VERSION "created by canmatrix"

NS_ :

BS_:

BU_: RadarFrontCenter DASy MPC3

BO_ 214 VFC_Object19A: 64 MPC3
 SG_ VFC_Obj19A_CRC : 0|16@1+ (1,0) [0|65535] ""  RadarFrontCenter,DASy
 SG_ VFC_Obj19A_AliveCtr : 16|8@1+ (1,0) [0|255] ""  RadarFrontCenter,DASy
 SG_ VFC_Obj19A_BlockCtr : 24|4@1+ (1,0) [0|15] ""  RadarFrontCenter,DASy
 SG_ VFC_Obj19A_ProtOrderIndex : 32|6@1+ (1,0) [0|63] ""  RadarFrontCenter,DASy
 SG_ VFC_Obj19A_Ax : 39|9@1+ (0.1,-16) [-16|16] "m/s^2"  RadarFrontCenter,DASy
 SG_ VFC_Obj19A_Vx : 48|12@1+ (0.1,-154) [-154|50] "m/s"  RadarFrontCenter,DASy
 SG_ VFC_Obj19A_Dx : 60|12@1+ (0.05,0) [0|204.7] "m"  RadarFrontCenter,DASy
 SG_ VFC_Obj19A_Dy : 72|14@1+ (0.01,-80) [-80|80] "m"  RadarFrontCenter,DASy
 SG_ VFC_Obj19A_Vy : 86|10@1+ (0.1,-50) [-50|50] "m/s"  RadarFrontCenter,DASy
 SG_ VFC_Obj19A_Ay : 96|8@1+ (0.1,-12) [-12|12] "m/s^2"  RadarFrontCenter,DASy
 SG_ VFC_Obj19A_DyStdDev : 104|10@1+ (0.02,0) [0|20] "m"  RadarFrontCenter,DASy
 SG_ VFC_Obj19A_DxStdDev : 118|10@1+ (0.05,0) [0|50] "m"  RadarFrontCenter,DASy
 SG_ VFC_Obj19A_VxStdDev : 128|10@1+ (0.1,0) [0|100] "m/s"  RadarFrontCenter,DASy
 SG_ VFC_Obj19A_ExistProb : 138|6@1+ (2,0) [0|100] "%"  RadarFrontCenter,DASy
 SG_ VFC_Obj19A_VyStdDev : 144|9@1+ (0.1,0) [0|50] "m/s"  RadarFrontCenter,DASy
 SG_ VFC_Obj19A_TypeProb : 154|6@1+ (2,0) [0|100] "%"  RadarFrontCenter,DASy
 SG_ VFC_Obj19A_AxStdDev : 160|8@1+ (0.1,0) [0|25] "m/s^2"  RadarFrontCenter,DASy
 SG_ VFC_Obj19A_AyStdDev : 168|8@1+ (0.1,0) [0|25] "m/s^2"  RadarFrontCenter,DASy
 SG_ VFC_Obj19A_PhiLeft : 176|13@1+ (0.00025,-1) [-1|1] ""  RadarFrontCenter,DASy
 SG_ VFC_Obj19A_ClassifiedView : 189|3@1+ (1,0) [0|7] ""  RadarFrontCenter,DASy
 SG_ VFC_Obj19A_Length : 192|9@1+ (0.05,0) [0|25.5] "m"  RadarFrontCenter,DASy
 SG_ VFC_Obj19A_WidthStdDev : 201|7@1+ (0.01,0) [0|1] "m"  RadarFrontCenter,DASy
 SG_ VFC_Obj19A_Height : 208|9@1+ (0.01,0) [0|5.11] "m"  RadarFrontCenter,DASy
 SG_ VFC_Obj19A_HeightStdDev : 217|7@1+ (0.01,0) [0|1] "m"  RadarFrontCenter,DASy
 SG_ VFC_Obj19A_PhiLeftStdDev : 224|8@1+ (0.0002,0) [0|0.05] ""  RadarFrontCenter,DASy
 SG_ VFC_Obj19A_HeadingStdDev : 232|6@1+ (0.01,0) [0|0.5] "rad"  RadarFrontCenter,DASy
 SG_ VFC_Obj19A_Measured : 238|2@1+ (1,0) [0|3] ""  RadarFrontCenter,DASy
 SG_ VFC_Obj19A_Heading : 240|9@1+ (0.01,-1.57) [-1.57|1.57] "rad"  RadarFrontCenter,DASy
 SG_ VFC_Obj19A_LengthStdDev : 249|7@1+ (0.05,0) [0|5] "m"  RadarFrontCenter,DASy
 SG_ VFC_Obj19A_PhiMid : 256|13@1+ (0.00025,-1) [-1|1] ""  RadarFrontCenter,DASy
 SG_ VFC_Obj19A_Width : 269|11@1+ (0.01,0) [0|12] "m"  RadarFrontCenter,DASy
 SG_ VFC_Obj19A_PhiMidStdDev : 280|8@1+ (0.0002,0) [0|0.05] ""  RadarFrontCenter,DASy
 SG_ VFC_Obj19A_PhiRight : 288|13@1+ (0.00025,-1) [-1|1] ""  RadarFrontCenter,DASy
 SG_ VFC_Obj19A_VisibleView : 301|3@1+ (1,0) [0|4] ""  RadarFrontCenter,DASy
 SG_ VFC_Obj19A_PhiRightStdDev : 304|8@1+ (0.0002,0) [0|0.05] ""  RadarFrontCenter,DASy
 SG_ VFC_Obj19A_PhiLeftVel : 312|13@1+ (0.001,-4) [-4|4] "1/s"  RadarFrontCenter,DASy
 SG_ VFC_Obj19A_PhiRightVel : 328|13@1+ (0.001,-4) [-4|4] "1/s"  RadarFrontCenter,DASy
 SG_ VFC_Obj19A_PhiRightVelStdDev : 344|8@1+ (0.001,0) [0|0.25] "1/s"  RadarFrontCenter,DASy
 SG_ VFC_Obj19A_PhiLeftVelStdDev : 352|8@1+ (0.001,0) [0|0.25] "1/s"  RadarFrontCenter,DASy
 SG_ VFC_Obj19A_PhiTop : 360|12@1+ (0.00025,-0.4) [-0.4|0.4] ""  RadarFrontCenter,DASy
 SG_ VFC_Obj19A_PhiBottom : 372|12@1+ (0.00025,-0.4) [-0.4|0.4] ""  RadarFrontCenter,DASy
 SG_ VFC_Obj19A_PhiTopStdDev : 384|8@1+ (0.0002,0) [0|0.05] ""  RadarFrontCenter,DASy
 SG_ VFC_Obj19A_HeadOrientation : 392|4@1+ (1,0) [0|10] ""  RadarFrontCenter,DASy
 SG_ VFC_Obj19A_Type : 396|4@1+ (1,0) [0|15] ""  RadarFrontCenter,DASy
 SG_ VFC_Obj19A_PhiBottomStdDev : 400|8@1+ (0.0002,0) [0|0.05] ""  RadarFrontCenter,DASy
 SG_ VFC_Obj19A_NormVx : 408|16@1+ (0.001,-40) [-40|25] "1/s"  RadarFrontCenter,DASy
 SG_ VFC_Obj19A_NormAx : 424|13@1+ (0.002,-10) [-10|6] "1/s^2"  RadarFrontCenter,DASy
 SG_ VFC_Obj19A_NormAxStdDev : 440|10@1+ (0.0025,0) [0|2.5] "1/s^2"  RadarFrontCenter,DASy
 SG_ VFC_Obj19A_ProbMovingLat : 450|6@1+ (2,0) [0|100] "%"  RadarFrontCenter,DASy
 SG_ VFC_Obj19A_ID : 456|8@1+ (1,0) [0|254] ""  RadarFrontCenter,DASy
 SG_ VFC_Obj19A_NormVxStdDev : 464|10@1+ (0.001,0) [0|1] "1/s"  RadarFrontCenter,DASy
 SG_ VFC_Obj19A_ProbMovingLong : 474|6@1+ (2,0) [0|100] "%"  RadarFrontCenter,DASy

BO_ 215 VFC_Object19B: 16 MPC3
 SG_ VFC_Obj19B_TTIPC_StdDev : 120|7@1+ (0.0625,0) [0|7.875] ""  RadarFrontCenter,DASy
 SG_ VFC_Obj19B_TTIPC : 104|11@1+ (0.008,-8) [-8|8] ""  RadarFrontCenter,DASy
 SG_ VFC_Obj19B_AngLongitude : 88|10@1+ (0.005,-2.5) [-2.5|2.5] "rad/s"  RadarFrontCenter,DASy
 SG_ VFC_Obj19B_CRC : 0|16@1+ (1,0) [0|65535] ""  RadarFrontCenter,DASy
 SG_ VFC_Obj19B_AliveCtr : 16|8@1+ (1,0) [0|255] ""  RadarFrontCenter,DASy
 SG_ VFC_Obj19B_BlockCtr : 24|4@1+ (1,0) [0|15] ""  RadarFrontCenter,DASy
 SG_ VFC_Obj19B_ScaleChange : 32|14@1+ (0.0001,0.5) [0.5|2.1] ""  RadarFrontCenter,DASy
 SG_ VFC_Obj19B_ScaleChngStdDev : 48|10@1+ (0.0001,0) [0|0.1] ""  RadarFrontCenter,DASy
 SG_ VFC_Obj19B_LineEdgeRightEgo : 58|1@1+ (1,0) [0|1] ""  RadarFrontCenter,DASy
 SG_ VFC_Obj19B_LineEdgeLeftEgo : 59|1@1+ (1,0) [0|1] ""  RadarFrontCenter,DASy
 SG_ VFC_Obj19B_CompletelyInImg : 60|1@1+ (1,0) [0|1] ""  RadarFrontCenter,DASy
 SG_ VFC_Obj19B_DirIndicator : 61|3@1+ (1,0) [0|7] ""  RadarFrontCenter,DASy
 SG_ VFC_Obj19B_LineEdgeAngle : 64|13@1+ (0.00025,-1) [-1|1] "rad"  RadarFrontCenter,DASy
 SG_ VFC_Obj19B_BrakeLight : 77|3@1+ (1,0) [0|7] ""  RadarFrontCenter,DASy
 SG_ VFC_Obj19B_MeasSource : 80|5@1+ (1,0) [0|31] ""  RadarFrontCenter,DASy
 SG_ VFC_Obj19B_Reliab : 98|6@1+ (1,0) [0|63] ""  RadarFrontCenter,DASy

BO_ 128 VFC_LineHeader: 16 MPC3
 SG_ VFC_LineHdr_AUTOSARTStamp : 96|26@1+ (1,0) [0|67108863] "ms"  DASy,RadarFrontCenter
 SG_ VFC_LineHdr_FrameNo : 28|4@1+ (1,0) [0|15] ""  RadarFrontCenter,DASy
 SG_ VFC_LineHdr_CRC : 0|16@1+ (1,0) [0|65535] ""  RadarFrontCenter,DASy
 SG_ VFC_LineHdr_AliveCtr : 16|8@1+ (1,0) [0|255] ""  RadarFrontCenter,DASy
 SG_ VFC_LineHdr_BlockCounter : 24|4@1+ (1,0) [0|15] ""  RadarFrontCenter,DASy
 SG_ VFC_LineHdr_Report : 32|8@1+ (1,0) [0|255] ""  RadarFrontCenter,DASy
 SG_ VFC_LineHdr_LineCount : 40|8@1+ (1,0) [0|255] ""  RadarFrontCenter,DASy
 SG_ VFC_LineHdr_PEPSIRuntime : 48|8@1+ (0.05,0) [0|10] "ms"  RadarFrontCenter,DASy
 SG_ VFC_LineHdr_TimeStamp : 56|26@1+ (1,0) [0|67108863] "ms"  RadarFrontCenter,DASy
 SG_ VFC_LineHdr_Blindness : 82|6@1+ (2,0) [0|100] "%"  RadarFrontCenter,DASy
 SG_ VFC_LineHdr_State : 88|3@1+ (1,0) [0|7] ""  RadarFrontCenter,DASy

BO_ 129 VFC_Line01: 32 MPC3
 SG_ VFC_Line01_CRC : 0|16@1+ (1,0) [0|65535] ""  RadarFrontCenter,DASy
 SG_ VFC_Line01_AliveCtr : 16|8@1+ (1,0) [0|255] ""  RadarFrontCenter,DASy
 SG_ VFC_Line01_BlockCounter : 24|4@1+ (1,0) [0|15] ""  RadarFrontCenter,DASy
 SG_ VFC_Line01_ProtOrderIndex : 32|6@1+ (1,0) [0|63] ""  RadarFrontCenter,DASy
 SG_ VFC_Line01_LineID : 40|8@1+ (1,0) [0|255] ""  RadarFrontCenter,DASy
 SG_ VFC_Line01_LaneRelation : 48|8@1+ (1,0) [0|255] ""  RadarFrontCenter,DASy
 SG_ VFC_Line01_ExistProb : 56|6@1+ (2,0) [0|100] "%"  RadarFrontCenter,DASy
 SG_ VFC_Line01_DxStart : 64|13@1+ (0.025,0) [0|204.775] "m"  RadarFrontCenter,DASy
 SG_ VFC_Line01_ColorClass : 77|3@1+ (1,0) [0|7] ""  RadarFrontCenter,DASy
 SG_ VFC_Line01_DxEnd : 80|10@1+ (0.25,0) [0|255.75] "m"  RadarFrontCenter,DASy
 SG_ VFC_Line01_HeadingAngle : 91|13@1+ (0.000488281,-1.6) [-1.6|1.6] "rad"  RadarFrontCenter,DASy
 SG_ VFC_Line01_Dy : 104|12@1+ (0.015625,-32) [-32|31.984375] "m"  RadarFrontCenter,DASy
 SG_ VFC_Line01_CurvChange : 116|12@1+ (3.8147E-006,-0.0078125) [-0.0078125|0.0078086965] "1/(m*m)"  RadarFrontCenter,DASy
 SG_ VFC_Line01_Curv : 128|13@1+ (3.8147E-006,-0.015625) [-0.015625|0.0156212077] "1/m"  RadarFrontCenter,DASy
 SG_ VFC_Line01_MeasureType : 141|3@1+ (1,0) [0|3] ""  RadarFrontCenter,DASy
 SG_ VFC_Line01_LineWidth : 144|8@1+ (0.01,0) [0|2.55] "m"  RadarFrontCenter,DASy
 SG_ VFC_Line01_CourseDeviation : 152|10@1+ (0.05,0) [0|50] ""  RadarFrontCenter,DASy
 SG_ VFC_Line01_Type : 162|5@1+ (1,0) [0|31] ""  RadarFrontCenter,DASy
 SG_ VFC_Line01_DyStdDevDxEnd : 167|9@1+ (0.0078125,0) [0|3.9921875] "m"  RadarFrontCenter,DASy
 SG_ VFC_Line01_HypoConfidence : 176|8@1+ (1,0) [0|255] ""  RadarFrontCenter,DASy
 SG_ VFC_Line01_prevID : 184|8@1+ (1,0) [0|255] ""  RadarFrontCenter,DASy
 SG_ VFC_Line01_nextID : 192|8@1+ (1,0) [0|255] ""  RadarFrontCenter,DASy
 SG_ VFC_Line01_DyStdDevDxStart : 200|9@1+ (0.0078125,0) [0|3.9921875] "m"  RadarFrontCenter,DASy
 SG_ VFC_Line01_TypeProb : 209|6@1+ (2,0) [0|100] "%"  RadarFrontCenter,DASy
 SG_ VFC_Line01_DyStdDevDxMid : 215|9@1+ (0.0078125,0) [0|3.9921875] "m"  RadarFrontCenter,DASy

BO_ 130 VFC_Line02: 32 MPC3
 SG_ VFC_Line02_CRC : 0|16@1+ (1,0) [0|65535] ""  RadarFrontCenter,DASy
 SG_ VFC_Line02_AliveCtr : 16|8@1+ (1,0) [0|255] ""  RadarFrontCenter,DASy
 SG_ VFC_Line02_BlockCounter : 24|4@1+ (1,0) [0|15] ""  RadarFrontCenter,DASy
 SG_ VFC_Line02_ProtOrderIndex : 32|6@1+ (1,0) [0|63] ""  RadarFrontCenter,DASy
 SG_ VFC_Line02_LineID : 40|8@1+ (1,0) [0|255] ""  RadarFrontCenter,DASy
 SG_ VFC_Line02_LaneRelation : 48|8@1+ (1,0) [0|255] ""  RadarFrontCenter,DASy
 SG_ VFC_Line02_ExistProb : 56|6@1+ (2,0) [0|100] "%"  RadarFrontCenter,DASy
 SG_ VFC_Line02_DxStart : 64|13@1+ (0.025,0) [0|204.775] "m"  RadarFrontCenter,DASy
 SG_ VFC_Line02_ColorClass : 77|3@1+ (1,0) [0|7] ""  RadarFrontCenter,DASy
 SG_ VFC_Line02_DxEnd : 80|10@1+ (0.25,0) [0|255.75] "m"  RadarFrontCenter,DASy
 SG_ VFC_Line02_HeadingAngle : 91|13@1+ (0.000488281,-1.6) [-1.6|1.6] "rad"  RadarFrontCenter,DASy
 SG_ VFC_Line02_Dy : 104|12@1+ (0.015625,-32) [-32|31.984375] "m"  RadarFrontCenter,DASy
 SG_ VFC_Line02_CurvChange : 116|12@1+ (3.8147E-006,-0.0078125) [-0.0078125|0.0078086965] "1/(m*m)"  RadarFrontCenter,DASy
 SG_ VFC_Line02_Curv : 128|13@1+ (3.8147E-006,-0.015625) [-0.015625|0.0156212077] "1/m"  RadarFrontCenter,DASy
 SG_ VFC_Line02_MeasureType : 141|3@1+ (1,0) [0|3] ""  RadarFrontCenter,DASy
 SG_ VFC_Line02_LineWidth : 144|8@1+ (0.01,0) [0|2.55] "m"  RadarFrontCenter,DASy
 SG_ VFC_Line02_CourseDeviation : 152|10@1+ (0.05,0) [0|50] ""  RadarFrontCenter,DASy
 SG_ VFC_Line02_Type : 162|5@1+ (1,0) [0|31] ""  RadarFrontCenter,DASy
 SG_ VFC_Line02_DyStdDevDxEnd : 167|9@1+ (0.0078125,0) [0|3.9921875] "m"  RadarFrontCenter,DASy
 SG_ VFC_Line02_HypoConfidence : 176|8@1+ (1,0) [0|255] ""  RadarFrontCenter,DASy
 SG_ VFC_Line02_prevID : 184|8@1+ (1,0) [0|255] ""  RadarFrontCenter,DASy
 SG_ VFC_Line02_nextID : 192|8@1+ (1,0) [0|255] ""  RadarFrontCenter,DASy
 SG_ VFC_Line02_DyStdDevDxStart : 200|9@1+ (0.0078125,0) [0|3.9921875] "m"  RadarFrontCenter,DASy
 SG_ VFC_Line02_TypeProb : 209|6@1+ (2,0) [0|100] "%"  RadarFrontCenter,DASy
 SG_ VFC_Line02_DyStdDevDxMid : 215|9@1+ (0.0078125,0) [0|3.9921875] "m"  RadarFrontCenter,DASy

BO_ 131 VFC_Line03: 32 MPC3
 SG_ VFC_Line03_CRC : 0|16@1+ (1,0) [0|65535] ""  RadarFrontCenter,DASy
 SG_ VFC_Line03_AliveCtr : 16|8@1+ (1,0) [0|255] ""  RadarFrontCenter,DASy
 SG_ VFC_Line03_BlockCounter : 24|4@1+ (1,0) [0|15] ""  RadarFrontCenter,DASy
 SG_ VFC_Line03_ProtOrderIndex : 32|6@1+ (1,0) [0|63] ""  RadarFrontCenter,DASy
 SG_ VFC_Line03_LineID : 40|8@1+ (1,0) [0|255] ""  RadarFrontCenter,DASy
 SG_ VFC_Line03_LaneRelation : 48|8@1+ (1,0) [0|255] ""  RadarFrontCenter,DASy
 SG_ VFC_Line03_ExistProb : 56|6@1+ (2,0) [0|100] "%"  RadarFrontCenter,DASy
 SG_ VFC_Line03_DxStart : 64|13@1+ (0.025,0) [0|204.775] "m"  RadarFrontCenter,DASy
 SG_ VFC_Line03_ColorClass : 77|3@1+ (1,0) [0|7] ""  RadarFrontCenter,DASy
 SG_ VFC_Line03_DxEnd : 80|10@1+ (0.25,0) [0|255.75] "m"  RadarFrontCenter,DASy
 SG_ VFC_Line03_HeadingAngle : 91|13@1+ (0.000488281,-1.6) [-1.6|1.6] "rad"  RadarFrontCenter,DASy
 SG_ VFC_Line03_Dy : 104|12@1+ (0.015625,-32) [-32|31.984375] "m"  RadarFrontCenter,DASy
 SG_ VFC_Line03_CurvChange : 116|12@1+ (3.8147E-006,-0.0078125) [-0.0078125|0.0078086965] "1/(m*m)"  RadarFrontCenter,DASy
 SG_ VFC_Line03_Curv : 128|13@1+ (3.8147E-006,-0.015625) [-0.015625|0.0156212077] "1/m"  RadarFrontCenter,DASy
 SG_ VFC_Line03_MeasureType : 141|3@1+ (1,0) [0|3] ""  RadarFrontCenter,DASy
 SG_ VFC_Line03_LineWidth : 144|8@1+ (0.01,0) [0|2.55] "m"  RadarFrontCenter,DASy
 SG_ VFC_Line03_CourseDeviation : 152|10@1+ (0.05,0) [0|50] ""  RadarFrontCenter,DASy
 SG_ VFC_Line03_Type : 162|5@1+ (1,0) [0|31] ""  RadarFrontCenter,DASy
 SG_ VFC_Line03_DyStdDevDxEnd : 167|9@1+ (0.0078125,0) [0|3.9921875] "m"  RadarFrontCenter,DASy
 SG_ VFC_Line03_HypoConfidence : 176|8@1+ (1,0) [0|255] ""  RadarFrontCenter,DASy
 SG_ VFC_Line03_prevID : 184|8@1+ (1,0) [0|255] ""  RadarFrontCenter,DASy
 SG_ VFC_Line03_nextID : 192|8@1+ (1,0) [0|255] ""  RadarFrontCenter,DASy
 SG_ VFC_Line03_DyStdDevDxStart : 200|9@1+ (0.0078125,0) [0|3.9921875] "m"  RadarFrontCenter,DASy
 SG_ VFC_Line03_TypeProb : 209|6@1+ (2,0) [0|100] "%"  RadarFrontCenter,DASy
 SG_ VFC_Line03_DyStdDevDxMid : 215|9@1+ (0.0078125,0) [0|3.9921875] "m"  RadarFrontCenter,DASy

BO_ 132 VFC_Line04: 32 MPC3
 SG_ VFC_Line04_CRC : 0|16@1+ (1,0) [0|65535] ""  RadarFrontCenter,DASy
 SG_ VFC_Line04_AliveCtr : 16|8@1+ (1,0) [0|255] ""  RadarFrontCenter,DASy
 SG_ VFC_Line04_BlockCounter : 24|4@1+ (1,0) [0|15] ""  RadarFrontCenter,DASy
 SG_ VFC_Line04_ProtOrderIndex : 32|6@1+ (1,0) [0|63] ""  RadarFrontCenter,DASy
 SG_ VFC_Line04_LineID : 40|8@1+ (1,0) [0|255] ""  RadarFrontCenter,DASy
 SG_ VFC_Line04_LaneRelation : 48|8@1+ (1,0) [0|255] ""  RadarFrontCenter,DASy
 SG_ VFC_Line04_ExistProb : 56|6@1+ (2,0) [0|100] "%"  RadarFrontCenter,DASy
 SG_ VFC_Line04_DxStart : 64|13@1+ (0.025,0) [0|204.775] "m"  RadarFrontCenter,DASy
 SG_ VFC_Line04_ColorClass : 77|3@1+ (1,0) [0|7] ""  RadarFrontCenter,DASy
 SG_ VFC_Line04_DxEnd : 80|10@1+ (0.25,0) [0|255.75] "m"  RadarFrontCenter,DASy
 SG_ VFC_Line04_HeadingAngle : 91|13@1+ (0.000488281,-1.6) [-1.6|1.6] "rad"  RadarFrontCenter,DASy
 SG_ VFC_Line04_Dy : 104|12@1+ (0.015625,-32) [-32|31.984375] "m"  RadarFrontCenter,DASy
 SG_ VFC_Line04_CurvChange : 116|12@1+ (3.8147E-006,-0.0078125) [-0.0078125|0.0078086965] "1/(m*m)"  RadarFrontCenter,DASy
 SG_ VFC_Line04_Curv : 128|13@1+ (3.8147E-006,-0.015625) [-0.015625|0.0156212077] "1/m"  RadarFrontCenter,DASy
 SG_ VFC_Line04_MeasureType : 141|3@1+ (1,0) [0|3] ""  RadarFrontCenter,DASy
 SG_ VFC_Line04_LineWidth : 144|8@1+ (0.01,0) [0|2.55] "m"  RadarFrontCenter,DASy
 SG_ VFC_Line04_CourseDeviation : 152|10@1+ (0.05,0) [0|50] ""  RadarFrontCenter,DASy
 SG_ VFC_Line04_Type : 162|5@1+ (1,0) [0|31] ""  RadarFrontCenter,DASy
 SG_ VFC_Line04_DyStdDevDxEnd : 167|9@1+ (0.0078125,0) [0|3.9921875] "m"  RadarFrontCenter,DASy
 SG_ VFC_Line04_HypoConfidence : 176|8@1+ (1,0) [0|255] ""  RadarFrontCenter,DASy
 SG_ VFC_Line04_prevID : 184|8@1+ (1,0) [0|255] ""  RadarFrontCenter,DASy
 SG_ VFC_Line04_nextID : 192|8@1+ (1,0) [0|255] ""  RadarFrontCenter,DASy
 SG_ VFC_Line04_DyStdDevDxStart : 200|9@1+ (0.0078125,0) [0|3.9921875] "m"  RadarFrontCenter,DASy
 SG_ VFC_Line04_TypeProb : 209|6@1+ (2,0) [0|100] "%"  RadarFrontCenter,DASy
 SG_ VFC_Line04_DyStdDevDxMid : 215|9@1+ (0.0078125,0) [0|3.9921875] "m"  RadarFrontCenter,DASy

BO_ 133 VFC_Line05: 32 MPC3
 SG_ VFC_Line05_CRC : 0|16@1+ (1,0) [0|65535] ""  RadarFrontCenter,DASy
 SG_ VFC_Line05_AliveCtr : 16|8@1+ (1,0) [0|255] ""  RadarFrontCenter,DASy
 SG_ VFC_Line05_BlockCounter : 24|4@1+ (1,0) [0|15] ""  RadarFrontCenter,DASy
 SG_ VFC_Line05_ProtOrderIndex : 32|6@1+ (1,0) [0|63] ""  RadarFrontCenter,DASy
 SG_ VFC_Line05_LineID : 40|8@1+ (1,0) [0|255] ""  RadarFrontCenter,DASy
 SG_ VFC_Line05_LaneRelation : 48|8@1+ (1,0) [0|255] ""  RadarFrontCenter,DASy
 SG_ VFC_Line05_ExistProb : 56|6@1+ (2,0) [0|100] "%"  RadarFrontCenter,DASy
 SG_ VFC_Line05_DxStart : 64|13@1+ (0.025,0) [0|204.775] "m"  RadarFrontCenter,DASy
 SG_ VFC_Line05_ColorClass : 77|3@1+ (1,0) [0|7] ""  RadarFrontCenter,DASy
 SG_ VFC_Line05_DxEnd : 80|10@1+ (0.25,0) [0|255.75] "m"  RadarFrontCenter,DASy
 SG_ VFC_Line05_HeadingAngle : 91|13@1+ (0.000488281,-1.6) [-1.6|1.6] "rad"  RadarFrontCenter,DASy
 SG_ VFC_Line05_Dy : 104|12@1+ (0.015625,-32) [-32|31.984375] "m"  RadarFrontCenter,DASy
 SG_ VFC_Line05_CurvChange : 116|12@1+ (3.8147E-006,-0.0078125) [-0.0078125|0.0078086965] "1/(m*m)"  RadarFrontCenter,DASy
 SG_ VFC_Line05_Curv : 128|13@1+ (3.8147E-006,-0.015625) [-0.015625|0.0156212077] "1/m"  RadarFrontCenter,DASy
 SG_ VFC_Line05_MeasureType : 141|3@1+ (1,0) [0|3] ""  RadarFrontCenter,DASy
 SG_ VFC_Line05_LineWidth : 144|8@1+ (0.01,0) [0|2.55] "m"  RadarFrontCenter,DASy
 SG_ VFC_Line05_CourseDeviation : 152|10@1+ (0.05,0) [0|50] ""  RadarFrontCenter,DASy
 SG_ VFC_Line05_Type : 162|5@1+ (1,0) [0|31] ""  RadarFrontCenter,DASy
 SG_ VFC_Line05_DyStdDevDxEnd : 167|9@1+ (0.0078125,0) [0|3.9921875] "m"  RadarFrontCenter,DASy
 SG_ VFC_Line05_HypoConfidence : 176|8@1+ (1,0) [0|255] ""  RadarFrontCenter,DASy
 SG_ VFC_Line05_prevID : 184|8@1+ (1,0) [0|255] ""  RadarFrontCenter,DASy
 SG_ VFC_Line05_nextID : 192|8@1+ (1,0) [0|255] ""  RadarFrontCenter,DASy
 SG_ VFC_Line05_DyStdDevDxStart : 200|9@1+ (0.0078125,0) [0|3.9921875] "m"  RadarFrontCenter,DASy
 SG_ VFC_Line05_TypeProb : 209|6@1+ (2,0) [0|100] "%"  RadarFrontCenter,DASy
 SG_ VFC_Line05_DyStdDevDxMid : 215|9@1+ (0.0078125,0) [0|3.9921875] "m"  RadarFrontCenter,DASy

BO_ 134 VFC_Line06: 32 MPC3
 SG_ VFC_Line06_CRC : 0|16@1+ (1,0) [0|65535] ""  RadarFrontCenter,DASy
 SG_ VFC_Line06_AliveCtr : 16|8@1+ (1,0) [0|255] ""  RadarFrontCenter,DASy
 SG_ VFC_Line06_BlockCounter : 24|4@1+ (1,0) [0|15] ""  RadarFrontCenter,DASy
 SG_ VFC_Line06_ProtOrderIndex : 32|6@1+ (1,0) [0|63] ""  RadarFrontCenter,DASy
 SG_ VFC_Line06_LineID : 40|8@1+ (1,0) [0|255] ""  RadarFrontCenter,DASy
 SG_ VFC_Line06_LaneRelation : 48|8@1+ (1,0) [0|255] ""  RadarFrontCenter,DASy
 SG_ VFC_Line06_ExistProb : 56|6@1+ (2,0) [0|100] "%"  RadarFrontCenter,DASy
 SG_ VFC_Line06_DxStart : 64|13@1+ (0.025,0) [0|204.775] "m"  RadarFrontCenter,DASy
 SG_ VFC_Line06_ColorClass : 77|3@1+ (1,0) [0|7] ""  RadarFrontCenter,DASy
 SG_ VFC_Line06_DxEnd : 80|10@1+ (0.25,0) [0|255.75] "m"  RadarFrontCenter,DASy
 SG_ VFC_Line06_HeadingAngle : 91|13@1+ (0.000488281,-1.6) [-1.6|1.6] "rad"  RadarFrontCenter,DASy
 SG_ VFC_Line06_Dy : 104|12@1+ (0.015625,-32) [-32|31.984375] "m"  RadarFrontCenter,DASy
 SG_ VFC_Line06_CurvChange : 116|12@1+ (3.8147E-006,-0.0078125) [-0.0078125|0.0078086965] "1/(m*m)"  RadarFrontCenter,DASy
 SG_ VFC_Line06_Curv : 128|13@1+ (3.8147E-006,-0.015625) [-0.015625|0.0156212077] "1/m"  RadarFrontCenter,DASy
 SG_ VFC_Line06_MeasureType : 141|3@1+ (1,0) [0|3] ""  RadarFrontCenter,DASy
 SG_ VFC_Line06_LineWidth : 144|8@1+ (0.01,0) [0|2.55] "m"  RadarFrontCenter,DASy
 SG_ VFC_Line06_CourseDeviation : 152|10@1+ (0.05,0) [0|50] ""  RadarFrontCenter,DASy
 SG_ VFC_Line06_Type : 162|5@1+ (1,0) [0|31] ""  RadarFrontCenter,DASy
 SG_ VFC_Line06_DyStdDevDxEnd : 167|9@1+ (0.0078125,0) [0|3.9921875] "m"  RadarFrontCenter,DASy
 SG_ VFC_Line06_HypoConfidence : 176|8@1+ (1,0) [0|255] ""  RadarFrontCenter,DASy
 SG_ VFC_Line06_prevID : 184|8@1+ (1,0) [0|255] ""  RadarFrontCenter,DASy
 SG_ VFC_Line06_nextID : 192|8@1+ (1,0) [0|255] ""  RadarFrontCenter,DASy
 SG_ VFC_Line06_DyStdDevDxStart : 200|9@1+ (0.0078125,0) [0|3.9921875] "m"  RadarFrontCenter,DASy
 SG_ VFC_Line06_TypeProb : 209|6@1+ (2,0) [0|100] "%"  RadarFrontCenter,DASy
 SG_ VFC_Line06_DyStdDevDxMid : 215|9@1+ (0.0078125,0) [0|3.9921875] "m"  RadarFrontCenter,DASy

BO_ 135 VFC_Line07: 32 MPC3
 SG_ VFC_Line07_CRC : 0|16@1+ (1,0) [0|65535] ""  RadarFrontCenter,DASy
 SG_ VFC_Line07_AliveCtr : 16|8@1+ (1,0) [0|255] ""  RadarFrontCenter,DASy
 SG_ VFC_Line07_BlockCounter : 24|4@1+ (1,0) [0|15] ""  RadarFrontCenter,DASy
 SG_ VFC_Line07_ProtOrderIndex : 32|6@1+ (1,0) [0|63] ""  RadarFrontCenter,DASy
 SG_ VFC_Line07_LineID : 40|8@1+ (1,0) [0|255] ""  RadarFrontCenter,DASy
 SG_ VFC_Line07_LaneRelation : 48|8@1+ (1,0) [0|255] ""  RadarFrontCenter,DASy
 SG_ VFC_Line07_ExistProb : 56|6@1+ (2,0) [0|100] "%"  RadarFrontCenter,DASy
 SG_ VFC_Line07_DxStart : 64|13@1+ (0.025,0) [0|204.775] "m"  RadarFrontCenter,DASy
 SG_ VFC_Line07_ColorClass : 77|3@1+ (1,0) [0|7] ""  RadarFrontCenter,DASy
 SG_ VFC_Line07_DxEnd : 80|10@1+ (0.25,0) [0|255.75] "m"  RadarFrontCenter,DASy
 SG_ VFC_Line07_HeadingAngle : 91|13@1+ (0.000488281,-1.6) [-1.6|1.6] "rad"  RadarFrontCenter,DASy
 SG_ VFC_Line07_Dy : 104|12@1+ (0.015625,-32) [-32|31.984375] "m"  RadarFrontCenter,DASy
 SG_ VFC_Line07_CurvChange : 116|12@1+ (3.8147E-006,-0.0078125) [-0.0078125|0.0078086965] "1/(m*m)"  RadarFrontCenter,DASy
 SG_ VFC_Line07_Curv : 128|13@1+ (3.8147E-006,-0.015625) [-0.015625|0.0156212077] "1/m"  RadarFrontCenter,DASy
 SG_ VFC_Line07_MeasureType : 141|3@1+ (1,0) [0|3] ""  RadarFrontCenter,DASy
 SG_ VFC_Line07_LineWidth : 144|8@1+ (0.01,0) [0|2.55] "m"  RadarFrontCenter,DASy
 SG_ VFC_Line07_CourseDeviation : 152|10@1+ (0.05,0) [0|50] ""  RadarFrontCenter,DASy
 SG_ VFC_Line07_Type : 162|5@1+ (1,0) [0|31] ""  RadarFrontCenter,DASy
 SG_ VFC_Line07_DyStdDevDxEnd : 167|9@1+ (0.0078125,0) [0|3.9921875] "m"  RadarFrontCenter,DASy
 SG_ VFC_Line07_HypoConfidence : 176|8@1+ (1,0) [0|255] ""  RadarFrontCenter,DASy
 SG_ VFC_Line07_prevID : 184|8@1+ (1,0) [0|255] ""  RadarFrontCenter,DASy
 SG_ VFC_Line07_nextID : 192|8@1+ (1,0) [0|255] ""  RadarFrontCenter,DASy
 SG_ VFC_Line07_DyStdDevDxStart : 200|9@1+ (0.0078125,0) [0|3.9921875] "m"  RadarFrontCenter,DASy
 SG_ VFC_Line07_TypeProb : 209|6@1+ (2,0) [0|100] "%"  RadarFrontCenter,DASy
 SG_ VFC_Line07_DyStdDevDxMid : 215|9@1+ (0.0078125,0) [0|3.9921875] "m"  RadarFrontCenter,DASy

BO_ 136 VFC_Line08: 32 MPC3
 SG_ VFC_Line08_CRC : 0|16@1+ (1,0) [0|65535] ""  RadarFrontCenter,DASy
 SG_ VFC_Line08_AliveCtr : 16|8@1+ (1,0) [0|255] ""  RadarFrontCenter,DASy
 SG_ VFC_Line08_BlockCounter : 24|4@1+ (1,0) [0|15] ""  RadarFrontCenter,DASy
 SG_ VFC_Line08_ProtOrderIndex : 32|6@1+ (1,0) [0|63] ""  RadarFrontCenter,DASy
 SG_ VFC_Line08_LineID : 40|8@1+ (1,0) [0|255] ""  RadarFrontCenter,DASy
 SG_ VFC_Line08_LaneRelation : 48|8@1+ (1,0) [0|255] ""  RadarFrontCenter,DASy
 SG_ VFC_Line08_ExistProb : 56|6@1+ (2,0) [0|100] "%"  RadarFrontCenter,DASy
 SG_ VFC_Line08_DxStart : 64|13@1+ (0.025,0) [0|204.775] "m"  RadarFrontCenter,DASy
 SG_ VFC_Line08_ColorClass : 77|3@1+ (1,0) [0|7] ""  RadarFrontCenter,DASy
 SG_ VFC_Line08_DxEnd : 80|10@1+ (0.25,0) [0|255.75] "m"  RadarFrontCenter,DASy
 SG_ VFC_Line08_HeadingAngle : 91|13@1+ (0.000488281,-1.6) [-1.6|1.6] "rad"  RadarFrontCenter,DASy
 SG_ VFC_Line08_Dy : 104|12@1+ (0.015625,-32) [-32|31.984375] "m"  RadarFrontCenter,DASy
 SG_ VFC_Line08_CurvChange : 116|12@1+ (3.8147E-006,-0.0078125) [-0.0078125|0.0078086965] "1/(m*m)"  RadarFrontCenter,DASy
 SG_ VFC_Line08_Curv : 128|13@1+ (3.8147E-006,-0.015625) [-0.015625|0.0156212077] "1/m"  RadarFrontCenter,DASy
 SG_ VFC_Line08_MeasureType : 141|3@1+ (1,0) [0|3] ""  RadarFrontCenter,DASy
 SG_ VFC_Line08_LineWidth : 144|8@1+ (0.01,0) [0|2.55] "m"  RadarFrontCenter,DASy
 SG_ VFC_Line08_CourseDeviation : 152|10@1+ (0.05,0) [0|50] ""  RadarFrontCenter,DASy
 SG_ VFC_Line08_Type : 162|5@1+ (1,0) [0|31] ""  RadarFrontCenter,DASy
 SG_ VFC_Line08_DyStdDevDxEnd : 167|9@1+ (0.0078125,0) [0|3.9921875] "m"  RadarFrontCenter,DASy
 SG_ VFC_Line08_HypoConfidence : 176|8@1+ (1,0) [0|255] ""  RadarFrontCenter,DASy
 SG_ VFC_Line08_prevID : 184|8@1+ (1,0) [0|255] ""  RadarFrontCenter,DASy
 SG_ VFC_Line08_nextID : 192|8@1+ (1,0) [0|255] ""  RadarFrontCenter,DASy
 SG_ VFC_Line08_DyStdDevDxStart : 200|9@1+ (0.0078125,0) [0|3.9921875] "m"  RadarFrontCenter,DASy
 SG_ VFC_Line08_TypeProb : 209|6@1+ (2,0) [0|100] "%"  RadarFrontCenter,DASy
 SG_ VFC_Line08_DyStdDevDxMid : 215|9@1+ (0.0078125,0) [0|3.9921875] "m"  RadarFrontCenter,DASy

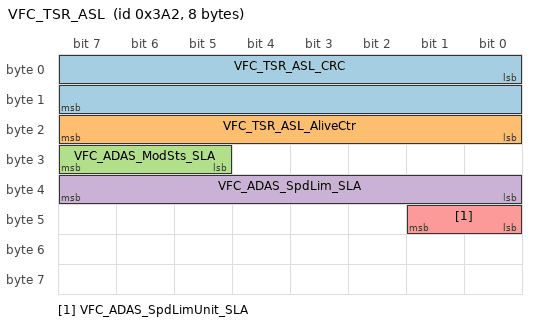
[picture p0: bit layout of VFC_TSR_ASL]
BO_ 930 VFC_TSR_ASL: 8 MPC3
 SG_ VFC_TSR_ASL_CRC : 0|16@1+ (1,0) [0|65535] ""  RadarFrontCenter,DASy
 SG_ VFC_TSR_ASL_AliveCtr : 16|8@1+ (1,0) [0|255] ""  RadarFrontCenter,DASy
 SG_ VFC_ADAS_ModSts_SLA : 29|3@1+ (1,0) [0|7] ""  RadarFrontCenter,DASy
 SG_ VFC_ADAS_SpdLim_SLA : 32|8@1+ (1,0) [0|255] ""  RadarFrontCenter,DASy
 SG_ VFC_ADAS_SpdLimUnit_SLA : 40|2@1+ (1,0) [0|3] ""  RadarFrontCenter,DASy

BO_ 384 RFC_LocationHdr00: 64 RadarFrontCenter
 SG_ RFC_Hdr00_CRC : 0|16@1+ (1,0) [0|65535] ""  DASy
 SG_ RFC_Hdr00_AliveCtr : 16|8@1+ (1,0) [0|255] ""  DASy
 SG_ RFC_Hdr00_ProtBlockCtr : 24|8@1+ (1,0) [0|255] ""  DASy
 SG_ RFC_Hdr00_ProtocolVersion : 32|16@1+ (1,0) [0|65535] ""  DASy
 SG_ RFC_Hdr00_ProtLocationCount : 48|8@1+ (1,0) [0|255] ""  DASy
 SG_ RFC_Hdr00_SensorState : 56|4@1+ (1,0) [0|15] ""  DASy
 SG_ RFC_Hdr00_TimeStamp : 60|26@1+ (1,0) [0|67108863] "ms"  DASy
 SG_ RFC_Hdr00_TimeStampStatus : 488|8@1+ (1,0) [0|255] ""  DASy
 SG_ RFC_Hdr00_LocDownSel : 87|1@1+ (1,0) [0|1] ""  DASy
 SG_ RFC_Hdr00_BliThetaVld : 88|8@1+ (1,0) [0|255] ""  DASy
 SG_ RFC_Hdr00_BliThetaSIMOVld : 96|8@1+ (1,0) [0|255] ""  DASy
 SG_ RFC_Hdr00_BliThetaMIMOVld : 104|8@1+ (1,0) [0|255] ""  DASy
 SG_ RFC_Hdr00_BliThetaSIMOShareVld : 112|8@1+ (1,0) [0|255] ""  DASy
 SG_ RFC_Hdr00_BliThetaMIMOShareVld : 120|8@1+ (1,0) [0|255] ""  DASy
 SG_ RFC_Hdr00_BliPhiVld : 128|8@1+ (1,0) [0|255] ""  DASy
 SG_ RFC_Hdr00_BliRCSMOVld : 136|8@1+ (1,0) [0|255] ""  DASy
 SG_ RFC_Hdr00_BliBinOverThresholdVld : 144|8@1+ (1,0) [0|255] ""  DASy
 SG_ RFC_Hdr00_BliNumValidReflectVld : 152|8@1+ (1,0) [0|255] ""  DASy
 SG_ RFC_Hdr00_BliTheta : 160|32@1- (1,0) [-3.4E+038|3.4E+038] ""  DASy
 SG_ RFC_Hdr00_BliThetaSIMO : 192|32@1- (1,0) [-3.4E+038|3.4E+038] ""  DASy
 SG_ RFC_Hdr00_BliThetaMIMO : 224|32@1- (1,0) [-3.4E+038|3.4E+038] ""  DASy
 SG_ RFC_Hdr00_BliThetaSIMOShare : 256|32@1- (1,0) [-3.4E+038|3.4E+038] ""  DASy
 SG_ RFC_Hdr00_BliThetaMIMOShare : 288|32@1- (1,0) [-3.4E+038|3.4E+038] ""  DASy
 SG_ RFC_Hdr00_BliPhi : 320|32@1- (1,0) [-3.4E+038|3.4E+038] ""  DASy
 SG_ RFC_Hdr00_BliRCSMO : 352|32@1- (1,0) [-3.4E+038|3.4E+038] ""  DASy
 SG_ RFC_Hdr00_BliBinsOverThreshold : 384|32@1- (1,0) [-3.4E+038|3.4E+038] ""  DASy
 SG_ RFC_Hdr00_BliNumValidReflections : 416|32@1- (1,0) [-3.4E+038|3.4E+038] ""  DASy
 SG_ RFC_Hdr00_BliCrossCorrSO : 448|32@1- (1,0) [-3.4E+038|3.4E+038] ""  DASy
 SG_ RFC_Hdr00_BliCrossCorrSOVld : 480|8@1+ (1,0) [0|255] ""  DASy

BO_ 385 RFC_LocationHdr01: 64 RadarFrontCenter
 SG_ RFC_Hdr01_PersVerWriteCnt03 : 56|8@1+ (1,0) [0|255] ""  DASy
 SG_ RFC_Hdr01_PersVerWriteCnt02 : 48|8@1+ (1,0) [0|255] ""  DASy
 SG_ RFC_Hdr01_PersVerWriteCnt01 : 40|8@1+ (1,0) [0|255] ""  DASy
 SG_ RFC_Hdr01_CRC : 0|16@1+ (1,0) [0|65535] ""  DASy
 SG_ RFC_Hdr01_AliveCtr : 16|8@1+ (1,0) [0|255] ""  DASy
 SG_ RFC_Hdr01_ProtBlockCtr : 24|8@1+ (1,0) [0|255] ""  DASy
 SG_ RFC_Hdr01_PersVerWriteCnt00 : 32|8@1+ (1,0) [0|255] ""  DASy
 SG_ RFC_Hdr01_PersAngIndAzi : 64|32@1- (1,0) [-3.4E+038|3.4E+038] "rad"  DASy
 SG_ RFC_Hdr01_PersAngIndElev : 96|32@1- (1,0) [-3.4E+038|3.4E+038] "rad"  DASy
 SG_ RFC_Hdr01_PersAngIndAziMean : 128|32@1- (1,0) [-3.4E+038|3.4E+038] "rad"  DASy
 SG_ RFC_Hdr01_PersAngIndElevMean : 160|32@1- (1,0) [-3.4E+038|3.4E+038] "rad"  DASy
 SG_ RFC_Hdr01_PersAngIndAziVnce : 192|32@1- (1,0) [-3.4E+038|3.4E+038] "rad^2"  DASy
 SG_ RFC_Hdr01_PersAngIndElevVnce : 224|32@1- (1,0) [-3.4E+038|3.4E+038] "rad^2"  DASy
 SG_ RFC_Hdr01_PersAngIndAziElevCov : 256|32@1- (1,0) [-3.4E+038|3.4E+038] "rad^2"  DASy
 SG_ RFC_Hdr01_PersAngCurrAzi : 288|32@1- (1,0) [-3.4E+038|3.4E+038] "rad"  DASy
 SG_ RFC_Hdr01_PersAngCurrElev : 320|32@1- (1,0) [-3.4E+038|3.4E+038] "rad"  DASy
 SG_ RFC_Hdr01_PersAngCurrAziMean : 352|32@1- (1,0) [-3.4E+038|3.4E+038] "rad"  DASy
 SG_ RFC_Hdr01_PersAngCurrElevMean : 384|32@1- (1,0) [-3.4E+038|3.4E+038] "rad"  DASy
 SG_ RFC_Hdr01_PersAngCurrAziVnce : 416|32@1- (1,0) [-3.4E+038|3.4E+038] "rad^2"  DASy
 SG_ RFC_Hdr01_PersAngCurrElevVnce : 448|32@1- (1,0) [-3.4E+038|3.4E+038] "rad^2"  DASy
 SG_ RFC_Hdr01_PersAngCurrAziElevCov : 480|32@1- (1,0) [-3.4E+038|3.4E+038] "rad^2"  DASy

BO_ 386 RFC_LocationHdr02: 64 RadarFrontCenter
 SG_ RFC_Hdr02_ModPerfDMax : 496|16@1+ (0.0078125,0) [0|511.9921875] "m"  DASy
 SG_ RFC_Hdr02_CRC : 0|16@1+ (1,0) [0|65535] ""  DASy
 SG_ RFC_Hdr02_AliveCtr : 16|8@1+ (1,0) [0|255] ""  DASy
 SG_ RFC_Hdr02_ProtBlockCtr : 24|8@1+ (1,0) [0|255] ""  DASy
 SG_ RFC_Hdr02_PersFiltDspMalIndAzi : 32|32@1- (1,0) [-3.4E+038|3.4E+038] ""  DASy
 SG_ RFC_Hdr02_PersFiltWeightIndAzi : 64|32@1- (1,0) [-3.4E+038|3.4E+038] ""  DASy
 SG_ RFC_Hdr02_PersFiltDspCurrAzi : 96|32@1- (1,0) [-3.4E+038|3.4E+038] ""  DASy
 SG_ RFC_Hdr02_PersFiltDspMalIndElev : 128|32@1- (1,0) [-3.4E+038|3.4E+038] ""  DASy
 SG_ RFC_Hdr02_PersFiltWeightIndElev : 160|32@1- (1,0) [-3.4E+038|3.4E+038] ""  DASy
 SG_ RFC_Hdr02_PersFiltDspCurrElev : 192|32@1- (1,0) [-3.4E+038|3.4E+038] ""  DASy
 SG_ RFC_Hdr02_PersMalStablePosAzi : 224|32@1- (1,0) [-3.4E+038|3.4E+038] "rad"  DASy
 SG_ RFC_Hdr02_PersMalStablePosElev : 256|32@1- (1,0) [-3.4E+038|3.4E+038] "rad"  DASy
 SG_ RFC_Hdr02_PersChDetPozAzi : 288|32@1- (1,0) [-3.4E+038|3.4E+038] "rad"  DASy
 SG_ RFC_Hdr02_PersChDetNegAzi : 320|32@1- (1,0) [-3.4E+038|3.4E+038] "rad"  DASy
 SG_ RFC_Hdr02_PersChDetPozElev : 352|32@1- (1,0) [-3.4E+038|3.4E+038] "rad"  DASy
 SG_ RFC_Hdr02_PersChDetNegElev : 384|32@1- (1,0) [-3.4E+038|3.4E+038] "rad"  DASy
 SG_ RFC_Hdr02_MntAziCur : 416|32@1- (1,0) [-3.4E+038|3.4E+038] "deg"  DASy
 SG_ RFC_Hdr02_MntElevCur : 448|32@1- (1,0) [-3.4E+038|3.4E+038] "deg"  DASy
 SG_ RFC_Hdr02_PersOutOfSpecAzi : 480|1@1+ (1,0) [0|1] ""  DASy
 SG_ RFC_Hdr02_PersOutOfSpecElev : 481|1@1+ (1,0) [0|1] ""  DASy

BO_ 387 RFC_LocationHdr03: 64 RadarFrontCenter
 SG_ RFC_Hdr03_CRC : 0|16@1+ (1,0) [0|65535] ""  DASy
 SG_ RFC_Hdr03_AliveCtr : 16|8@1+ (1,0) [0|255] ""  DASy
 SG_ RFC_Hdr03_ProtBlockCtr : 24|8@1+ (1,0) [0|255] ""  DASy
 SG_ RFC_Hdr03_FoVdMaxTheta00 : 32|9@1+ (1,0) [0|511] "m"  DASy
 SG_ RFC_Hdr03_FoVdMaxTheta01 : 41|9@1+ (1,0) [0|511] "m"  DASy
 SG_ RFC_Hdr03_FoVdMaxTheta02 : 50|9@1+ (1,0) [0|511] "m"  DASy
 SG_ RFC_Hdr03_FoVdMaxTheta03 : 59|9@1+ (1,0) [0|511] "m"  DASy
 SG_ RFC_Hdr03_FoVdMaxTheta04 : 68|9@1+ (1,0) [0|511] "m"  DASy
 SG_ RFC_Hdr03_FoVdMaxTheta05 : 77|9@1+ (1,0) [0|511] "m"  DASy
 SG_ RFC_Hdr03_FoVdMaxTheta06 : 86|9@1+ (1,0) [0|511] "m"  DASy
 SG_ RFC_Hdr03_FoVdMaxTheta07 : 95|9@1+ (1,0) [0|511] "m"  DASy
 SG_ RFC_Hdr03_FoVdMaxTheta08 : 104|9@1+ (1,0) [0|511] "m"  DASy
 SG_ RFC_Hdr03_FoVdMaxTheta09 : 113|9@1+ (1,0) [0|511] "m"  DASy
 SG_ RFC_Hdr03_FoVdMaxTheta10 : 122|9@1+ (1,0) [0|511] "m"  DASy
 SG_ RFC_Hdr03_FoVdMaxTheta11 : 131|9@1+ (1,0) [0|511] "m"  DASy
 SG_ RFC_Hdr03_FoVdMaxTheta12 : 140|9@1+ (1,0) [0|511] "m"  DASy
 SG_ RFC_Hdr03_FoVdMaxTheta13 : 149|9@1+ (1,0) [0|511] "m"  DASy
 SG_ RFC_Hdr03_FoVdMaxTheta14 : 158|9@1+ (1,0) [0|511] "m"  DASy
 SG_ RFC_Hdr03_FoVdMaxTheta15 : 167|9@1+ (1,0) [0|511] "m"  DASy
 SG_ RFC_Hdr03_FoVdMaxTheta16 : 176|9@1+ (1,0) [0|511] "m"  DASy
 SG_ RFC_Hdr03_FoVdMaxTheta17 : 185|9@1+ (1,0) [0|511] "m"  DASy
 SG_ RFC_Hdr03_FoVdMaxTheta18 : 194|9@1+ (1,0) [0|511] "m"  DASy
 SG_ RFC_Hdr03_FoVdMaxTheta19 : 203|9@1+ (1,0) [0|511] "m"  DASy
 SG_ RFC_Hdr03_FoVdMaxTheta20 : 212|9@1+ (1,0) [0|511] "m"  DASy
 SG_ RFC_Hdr03_FoVdMaxTheta21 : 221|9@1+ (1,0) [0|511] "m"  DASy
 SG_ RFC_Hdr03_FoVdMaxTheta22 : 230|9@1+ (1,0) [0|511] "m"  DASy
 SG_ RFC_Hdr03_FoVdMaxTheta23 : 239|9@1+ (1,0) [0|511] "m"  DASy
 SG_ RFC_Hdr03_FoVdMaxTheta24 : 248|9@1+ (1,0) [0|511] "m"  DASy
 SG_ RFC_Hdr03_FoVdMaxPhi00 : 257|7@1+ (0.01,0) [0|1] "-"  DASy
 SG_ RFC_Hdr03_FoVTheta00 : 264|8@1+ (1,-90) [-90|90] "deg"  DASy
 SG_ RFC_Hdr03_FoVTheta01 : 272|8@1+ (1,-90) [-90|90] "deg"  DASy
 SG_ RFC_Hdr03_FoVTheta02 : 280|8@1+ (1,-90) [-90|90] "deg"  DASy
 SG_ RFC_Hdr03_FoVTheta03 : 288|8@1+ (1,-90) [-90|90] "deg"  DASy
 SG_ RFC_Hdr03_FoVTheta04 : 296|8@1+ (1,-90) [-90|90] "deg"  DASy
 SG_ RFC_Hdr03_FoVTheta05 : 304|8@1+ (1,-90) [-90|90] "deg"  DASy
 SG_ RFC_Hdr03_FoVTheta06 : 312|8@1+ (1,-90) [-90|90] "deg"  DASy
 SG_ RFC_Hdr03_FoVTheta07 : 320|8@1+ (1,-90) [-90|90] "deg"  DASy
 SG_ RFC_Hdr03_FoVTheta08 : 328|8@1+ (1,-90) [-90|90] "deg"  DASy
 SG_ RFC_Hdr03_FoVTheta09 : 336|8@1+ (1,-90) [-90|90] "deg"  DASy
 SG_ RFC_Hdr03_FoVTheta10 : 344|8@1+ (1,-90) [-90|90] "deg"  DASy
 SG_ RFC_Hdr03_FoVTheta11 : 352|8@1+ (1,-90) [-90|90] "deg"  DASy
 SG_ RFC_Hdr03_FoVTheta12 : 360|8@1+ (1,-90) [-90|90] "deg"  DASy
 SG_ RFC_Hdr03_FoVTheta13 : 368|8@1+ (1,-90) [-90|90] "deg"  DASy
 SG_ RFC_Hdr03_FoVTheta14 : 376|8@1+ (1,-90) [-90|90] "deg"  DASy
 SG_ RFC_Hdr03_FoVTheta15 : 384|8@1+ (1,-90) [-90|90] "deg"  DASy
 SG_ RFC_Hdr03_FoVTheta16 : 392|8@1+ (1,-90) [-90|90] "deg"  DASy
 SG_ RFC_Hdr03_FoVTheta17 : 400|8@1+ (1,-90) [-90|90] "deg"  DASy
 SG_ RFC_Hdr03_FoVTheta18 : 408|8@1+ (1,-90) [-90|90] "deg"  DASy
 SG_ RFC_Hdr03_FoVTheta19 : 416|8@1+ (1,-90) [-90|90] "deg"  DASy
 SG_ RFC_Hdr03_FoVTheta20 : 424|8@1+ (1,-90) [-90|90] "deg"  DASy
 SG_ RFC_Hdr03_FoVTheta21 : 432|8@1+ (1,-90) [-90|90] "deg"  DASy
 SG_ RFC_Hdr03_FoVTheta22 : 440|8@1+ (1,-90) [-90|90] "deg"  DASy
 SG_ RFC_Hdr03_FoVTheta23 : 448|8@1+ (1,-90) [-90|90] "deg"  DASy
 SG_ RFC_Hdr03_FoVTheta24 : 456|8@1+ (1,-90) [-90|90] "deg"  DASy
 SG_ RFC_Hdr03_FoVdMaxPhi01 : 464|7@1+ (0.01,0) [0|1] "-"  DASy
 SG_ RFC_Hdr03_FoVdMaxPhi02 : 471|7@1+ (0.01,0) [0|1] "-"  DASy
 SG_ RFC_Hdr03_FoVdMaxPhi03 : 478|7@1+ (0.01,0) [0|1] "-"  DASy
 SG_ RFC_Hdr03_FoVdMaxPhi04 : 485|7@1+ (0.01,0) [0|1] "-"  DASy
 SG_ RFC_Hdr03_FoVdMaxPhi05 : 492|7@1+ (0.01,0) [0|1] "-"  DASy
 SG_ RFC_Hdr03_FoVdMaxPhi06 : 499|7@1+ (0.01,0) [0|1] "-"  DASy

BO_ 388 RFC_LocationHdr04: 64 RadarFrontCenter
 SG_ RFC_Hdr04_CRC : 0|16@1+ (1,0) [0|65535] ""  DASy
 SG_ RFC_Hdr04_AliveCtr : 16|8@1+ (1,0) [0|255] ""  DASy
 SG_ RFC_Hdr04_ProtBlockCtr : 24|8@1+ (1,0) [0|255] ""  DASy
 SG_ RFC_Hdr04_FoVdMaxPhi07 : 32|7@1+ (0.01,0) [0|1] "-"  DASy
 SG_ RFC_Hdr04_FoVdMaxPhi08 : 39|7@1+ (0.01,0) [0|1] "-"  DASy
 SG_ RFC_Hdr04_FoVdMaxPhi09 : 46|7@1+ (0.01,0) [0|1] "-"  DASy
 SG_ RFC_Hdr04_FoVdMaxPhi10 : 53|7@1+ (0.01,0) [0|1] "-"  DASy
 SG_ RFC_Hdr04_FoVPhi00 : 60|6@1+ (1,-30) [-30|30] "deg"  DASy
 SG_ RFC_Hdr04_FoVPhi01 : 66|6@1+ (1,-30) [-30|30] "deg"  DASy
 SG_ RFC_Hdr04_FoVPhi02 : 72|6@1+ (1,-30) [-30|30] "deg"  DASy
 SG_ RFC_Hdr04_FoVPhi03 : 78|6@1+ (1,-30) [-30|30] "deg"  DASy
 SG_ RFC_Hdr04_FoVPhi04 : 84|6@1+ (1,-30) [-30|30] "deg"  DASy
 SG_ RFC_Hdr04_FoVPhi05 : 90|6@1+ (1,-30) [-30|30] "deg"  DASy
 SG_ RFC_Hdr04_FoVPhi06 : 96|6@1+ (1,-30) [-30|30] "deg"  DASy
 SG_ RFC_Hdr04_FoVPhi07 : 102|6@1+ (1,-30) [-30|30] "deg"  DASy
 SG_ RFC_Hdr04_FoVPhi08 : 108|6@1+ (1,-30) [-30|30] "deg"  DASy
 SG_ RFC_Hdr04_FoVPhi09 : 114|6@1+ (1,-30) [-30|30] "deg"  DASy
 SG_ RFC_Hdr04_FoVPhi10 : 120|6@1+ (1,-30) [-30|30] "deg"  DASy
 SG_ RFC_Hdr04_MntPosX : 128|32@1- (1,0) [-3.4E+038|3.4E+038] "m"  DASy
 SG_ RFC_Hdr04_MntPosY : 160|32@1- (1,0) [-3.4E+038|3.4E+038] "m"  DASy
 SG_ RFC_Hdr04_MntPosZ : 192|32@1- (1,0) [-3.4E+038|3.4E+038] "m"  DASy
 SG_ RFC_Hdr04_MntAziNom : 224|32@1- (1,0) [-3.4E+038|3.4E+038] "deg"  DASy
 SG_ RFC_Hdr04_MntElevNom : 256|32@1- (1,0) [-3.4E+038|3.4E+038] "deg"  DASy
 SG_ RFC_Hdr04_InitCov : 288|32@1- (1,0) [-3.4E+038|3.4E+038] "-"  DASy
 SG_ RFC_Hdr04_TspMeasID : 320|32@1+ (1,0) [0|4294967295] "-"  DASy
 SG_ RFC_Hdr04_TspSensID : 352|32@1+ (1,0) [0|4294967295] "-"  DASy
 SG_ RFC_Hdr04_TspLastMeas : 384|32@1+ (1,0) [0|4294967295] "-"  DASy
 SG_ RFC_Hdr04_TspLastRec : 416|32@1+ (1,0) [0|4294967295] "-"  DASy
 SG_ RFC_Hdr04_TspPredMeas : 448|32@1+ (1,0) [0|4294967295] "-"  DASy
 SG_ RFC_Hdr04_TspPredRec : 480|32@1+ (1,0) [0|4294967295] "-"  DASy

BO_ 400 RFC_Location_000_001: 64 RadarFrontCenter
 SG_ RFC_Loc000_CRC : 0|16@1+ (1,0) [0|65535] ""  DASy
 SG_ RFC_Loc000_AliveCtr : 16|8@1+ (1,0) [0|255] ""  DASy
 SG_ RFC_Loc000_ProtBlockCtr : 24|8@1+ (1,0) [0|255] ""  DASy
 SG_ RFC_Loc000_Dr : 32|16@1+ (0.0078125,0) [0|511.9921875] "m"  DASy
 SG_ RFC_Loc000_Vr : 48|16@1+ (0.00390625,-128) [-128|127.99609375] "m/s"  DASy
 SG_ RFC_Loc000_Theta : 64|16@1+ (0.01,-327.68) [-90|90] "deg"  DASy
 SG_ RFC_Loc000_Phi : 80|16@1+ (0.01,-327.68) [-30|30] "deg"  DASy
 SG_ RFC_Loc000_DrVnce : 96|16@1+ (1.52588E-005,0) [0|0.999984741210937] "m^2"  DASy
 SG_ RFC_Loc000_VrVnce : 112|16@1+ (1.52588E-005,0) [0|0.999984741210937] "m^2/s^2"  DASy
 SG_ RFC_Loc000_ThetaVnce : 128|16@1+ (0.00390625,0) [0|255.99609375] "deg^2"  DASy
 SG_ RFC_Loc000_PhiVnce : 144|16@1+ (0.00390625,0) [0|255.99609375] "deg^2"  DASy
 SG_ RFC_Loc000_DrVrCoVnce : 160|16@1+ (3.814697265625E-006,-0.125) [-0.125|0.124996185302734] "m^2/s"  DASy
 SG_ RFC_Loc000_RCS : 176|16@1+ (0.00390625,-128) [-128|127.99609375] "dBsm"  DASy
 SG_ RFC_Loc000_RSSI : 192|16@1+ (0.00195312,0) [0|127.998046875] "dimensionless"  DASy
 SG_ RFC_Loc000_DrVrQuality : 208|8@1+ (1,0) [0|255] "dimensionless"  DASy
 SG_ RFC_Loc000_ThetaQuality : 216|8@1+ (1,0) [0|255] "dimensionless"  DASy
 SG_ RFC_Loc000_PhiQuality : 224|8@1+ (1,0) [0|255] "dimensionless"  DASy
 SG_ RFC_Loc001_Dr : 256|16@1+ (0.0078125,0) [0|511.9921875] "m"  DASy
 SG_ RFC_Loc001_Vr : 272|16@1+ (0.00390625,-128) [-128|127.99609375] "m/s"  DASy
 SG_ RFC_Loc001_Theta : 288|16@1+ (0.01,-327.68) [-90|90] "deg"  DASy
 SG_ RFC_Loc001_Phi : 304|16@1+ (0.01,-327.68) [-30|30] "deg"  DASy
 SG_ RFC_Loc001_DrVnce : 320|16@1+ (1.52588E-005,0) [0|0.999984741210937] "m^2"  DASy
 SG_ RFC_Loc001_VrVnce : 336|16@1+ (1.52588E-005,0) [0|0.999984741210937] "m^2/s^2"  DASy
 SG_ RFC_Loc001_ThetaVnce : 352|16@1+ (0.00390625,0) [0|255.99609375] "deg^2"  DASy
 SG_ RFC_Loc001_PhiVnce : 368|16@1+ (0.00390625,0) [0|255.99609375] "deg^2"  DASy
 SG_ RFC_Loc001_DrVrCoVnce : 384|16@1+ (3.814697265625E-006,-0.125) [-0.125|0.124996185302734] "m^2/s"  DASy
 SG_ RFC_Loc001_RCS : 400|16@1+ (0.00390625,-128) [-128|127.99609375] "dBsm"  DASy
 SG_ RFC_Loc001_RSSI : 416|16@1+ (0.00195312,0) [0|127.998046875] "dimensionless"  DASy
 SG_ RFC_Loc001_DrVrQuality : 432|8@1+ (1,0) [0|255] "dimensionless"  DASy
 SG_ RFC_Loc001_ThetaQuality : 440|8@1+ (1,0) [0|255] "dimensionless"  DASy
 SG_ RFC_Loc001_PhiQuality : 448|8@1+ (1,0) [0|255] "dimensionless"  DASy

BO_ 401 RFC_Location_002_003: 64 RadarFrontCenter
 SG_ RFC_Loc002_CRC : 0|16@1+ (1,0) [0|65535] ""  DASy
 SG_ RFC_Loc002_AliveCtr : 16|8@1+ (1,0) [0|255] ""  DASy
 SG_ RFC_Loc002_ProtBlockCtr : 24|8@1+ (1,0) [0|255] ""  DASy
 SG_ RFC_Loc002_Dr : 32|16@1+ (0.0078125,0) [0|511.9921875] "m"  DASy
 SG_ RFC_Loc002_Vr : 48|16@1+ (0.00390625,-128) [-128|127.99609375] "m/s"  DASy
 SG_ RFC_Loc002_Theta : 64|16@1+ (0.01,-327.68) [-90|90] "deg"  DASy
 SG_ RFC_Loc002_Phi : 80|16@1+ (0.01,-327.68) [-30|30] "deg"  DASy
 SG_ RFC_Loc002_DrVnce : 96|16@1+ (1.52588E-005,0) [0|0.999984741210937] "m^2"  DASy
 SG_ RFC_Loc002_VrVnce : 112|16@1+ (1.52588E-005,0) [0|0.999984741210937] "m^2/s^2"  DASy
 SG_ RFC_Loc002_ThetaVnce : 128|16@1+ (0.00390625,0) [0|255.99609375] "deg^2"  DASy
 SG_ RFC_Loc002_PhiVnce : 144|16@1+ (0.00390625,0) [0|255.99609375] "deg^2"  DASy
 SG_ RFC_Loc002_DrVrCoVnce : 160|16@1+ (3.814697265625E-006,-0.125) [-0.125|0.124996185302734] "m^2/s"  DASy
 SG_ RFC_Loc002_RCS : 176|16@1+ (0.00390625,-128) [-128|127.99609375] "dBsm"  DASy
 SG_ RFC_Loc002_RSSI : 192|16@1+ (0.00195312,0) [0|127.998046875] "dimensionless"  DASy
 SG_ RFC_Loc002_DrVrQuality : 208|8@1+ (1,0) [0|255] "dimensionless"  DASy
 SG_ RFC_Loc002_ThetaQuality : 216|8@1+ (1,0) [0|255] "dimensionless"  DASy
 SG_ RFC_Loc002_PhiQuality : 224|8@1+ (1,0) [0|255] "dimensionless"  DASy
 SG_ RFC_Loc003_Dr : 256|16@1+ (0.0078125,0) [0|511.9921875] "m"  DASy
 SG_ RFC_Loc003_Vr : 272|16@1+ (0.00390625,-128) [-128|127.99609375] "m/s"  DASy
 SG_ RFC_Loc003_Theta : 288|16@1+ (0.01,-327.68) [-90|90] "deg"  DASy
 SG_ RFC_Loc003_Phi : 304|16@1+ (0.01,-327.68) [-30|30] "deg"  DASy
 SG_ RFC_Loc003_DrVnce : 320|16@1+ (1.52588E-005,0) [0|0.999984741210937] "m^2"  DASy
 SG_ RFC_Loc003_VrVnce : 336|16@1+ (1.52588E-005,0) [0|0.999984741210937] "m^2/s^2"  DASy
 SG_ RFC_Loc003_ThetaVnce : 352|16@1+ (0.00390625,0) [0|255.99609375] "deg^2"  DASy
 SG_ RFC_Loc003_PhiVnce : 368|16@1+ (0.00390625,0) [0|255.99609375] "deg^2"  DASy
 SG_ RFC_Loc003_DrVrCoVnce : 384|16@1+ (3.814697265625E-006,-0.125) [-0.125|0.124996185302734] "m^2/s"  DASy
 SG_ RFC_Loc003_RCS : 400|16@1+ (0.00390625,-128) [-128|127.99609375] "dBsm"  DASy
 SG_ RFC_Loc003_RSSI : 416|16@1+ (0.00195312,0) [0|127.998046875] "dimensionless"  DASy
 SG_ RFC_Loc003_DrVrQuality : 432|8@1+ (1,0) [0|255] "dimensionless"  DASy
 SG_ RFC_Loc003_ThetaQuality : 440|8@1+ (1,0) [0|255] "dimensionless"  DASy
 SG_ RFC_Loc003_PhiQuality : 448|8@1+ (1,0) [0|255] "dimensionless"  DASy

BO_ 402 RFC_Location_004_005: 64 RadarFrontCenter
 SG_ RFC_Loc004_CRC : 0|16@1+ (1,0) [0|65535] ""  DASy
 SG_ RFC_Loc004_AliveCtr : 16|8@1+ (1,0) [0|255] ""  DASy
 SG_ RFC_Loc004_ProtBlockCtr : 24|8@1+ (1,0) [0|255] ""  DASy
 SG_ RFC_Loc004_Dr : 32|16@1+ (0.0078125,0) [0|511.9921875] "m"  DASy
 SG_ RFC_Loc004_Vr : 48|16@1+ (0.00390625,-128) [-128|127.99609375] "m/s"  DASy
 SG_ RFC_Loc004_Theta : 64|16@1+ (0.01,-327.68) [-90|90] "deg"  DASy
 SG_ RFC_Loc004_Phi : 80|16@1+ (0.01,-327.68) [-30|30] "deg"  DASy
 SG_ RFC_Loc004_DrVnce : 96|16@1+ (1.52588E-005,0) [0|0.999984741210937] "m^2"  DASy
 SG_ RFC_Loc004_VrVnce : 112|16@1+ (1.52588E-005,0) [0|0.999984741210937] "m^2/s^2"  DASy
 SG_ RFC_Loc004_ThetaVnce : 128|16@1+ (0.00390625,0) [0|255.99609375] "deg^2"  DASy
 SG_ RFC_Loc004_PhiVnce : 144|16@1+ (0.00390625,0) [0|255.99609375] "deg^2"  DASy
 SG_ RFC_Loc004_DrVrCoVnce : 160|16@1+ (3.814697265625E-006,-0.125) [-0.125|0.124996185302734] "m^2/s"  DASy
 SG_ RFC_Loc004_RCS : 176|16@1+ (0.00390625,-128) [-128|127.99609375] "dBsm"  DASy
 SG_ RFC_Loc004_RSSI : 192|16@1+ (0.00195312,0) [0|127.998046875] "dimensionless"  DASy
 SG_ RFC_Loc004_DrVrQuality : 208|8@1+ (1,0) [0|255] "dimensionless"  DASy
 SG_ RFC_Loc004_ThetaQuality : 216|8@1+ (1,0) [0|255] "dimensionless"  DASy
 SG_ RFC_Loc004_PhiQuality : 224|8@1+ (1,0) [0|255] "dimensionless"  DASy
 SG_ RFC_Loc005_Dr : 256|16@1+ (0.0078125,0) [0|511.9921875] "m"  DASy
 SG_ RFC_Loc005_Vr : 272|16@1+ (0.00390625,-128) [-128|127.99609375] "m/s"  DASy
 SG_ RFC_Loc005_Theta : 288|16@1+ (0.01,-327.68) [-90|90] "deg"  DASy
 SG_ RFC_Loc005_Phi : 304|16@1+ (0.01,-327.68) [-30|30] "deg"  DASy
 SG_ RFC_Loc005_DrVnce : 320|16@1+ (1.52588E-005,0) [0|0.999984741210937] "m^2"  DASy
 SG_ RFC_Loc005_VrVnce : 336|16@1+ (1.52588E-005,0) [0|0.999984741210937] "m^2/s^2"  DASy
 SG_ RFC_Loc005_ThetaVnce : 352|16@1+ (0.00390625,0) [0|255.99609375] "deg^2"  DASy
 SG_ RFC_Loc005_PhiVnce : 368|16@1+ (0.00390625,0) [0|255.99609375] "deg^2"  DASy
 SG_ RFC_Loc005_DrVrCoVnce : 384|16@1+ (3.814697265625E-006,-0.125) [-0.125|0.124996185302734] "m^2/s"  DASy
 SG_ RFC_Loc005_RCS : 400|16@1+ (0.00390625,-128) [-128|127.99609375] "dBsm"  DASy
 SG_ RFC_Loc005_RSSI : 416|16@1+ (0.00195312,0) [0|127.998046875] "dimensionless"  DASy
 SG_ RFC_Loc005_DrVrQuality : 432|8@1+ (1,0) [0|255] "dimensionless"  DASy
 SG_ RFC_Loc005_ThetaQuality : 440|8@1+ (1,0) [0|255] "dimensionless"  DASy
 SG_ RFC_Loc005_PhiQuality : 448|8@1+ (1,0) [0|255] "dimensionless"  DASy

BO_ 403 RFC_Location_006_007: 64 RadarFrontCenter
 SG_ RFC_Loc006_CRC : 0|16@1+ (1,0) [0|65535] ""  DASy
 SG_ RFC_Loc006_AliveCtr : 16|8@1+ (1,0) [0|255] ""  DASy
 SG_ RFC_Loc006_ProtBlockCtr : 24|8@1+ (1,0) [0|255] ""  DASy
 SG_ RFC_Loc006_Dr : 32|16@1+ (0.0078125,0) [0|511.9921875] "m"  DASy
 SG_ RFC_Loc006_Vr : 48|16@1+ (0.00390625,-128) [-128|127.99609375] "m/s"  DASy
 SG_ RFC_Loc006_Theta : 64|16@1+ (0.01,-327.68) [-90|90] "deg"  DASy
 SG_ RFC_Loc006_Phi : 80|16@1+ (0.01,-327.68) [-30|30] "deg"  DASy
 SG_ RFC_Loc006_DrVnce : 96|16@1+ (1.52588E-005,0) [0|0.999984741210937] "m^2"  DASy
 SG_ RFC_Loc006_VrVnce : 112|16@1+ (1.52588E-005,0) [0|0.999984741210937] "m^2/s^2"  DASy
 SG_ RFC_Loc006_ThetaVnce : 128|16@1+ (0.00390625,0) [0|255.99609375] "deg^2"  DASy
 SG_ RFC_Loc006_PhiVnce : 144|16@1+ (0.00390625,0) [0|255.99609375] "deg^2"  DASy
 SG_ RFC_Loc006_DrVrCoVnce : 160|16@1+ (3.814697265625E-006,-0.125) [-0.125|0.124996185302734] "m^2/s"  DASy
 SG_ RFC_Loc006_RCS : 176|16@1+ (0.00390625,-128) [-128|127.99609375] "dBsm"  DASy
 SG_ RFC_Loc006_RSSI : 192|16@1+ (0.00195312,0) [0|127.998046875] "dimensionless"  DASy
 SG_ RFC_Loc006_DrVrQuality : 208|8@1+ (1,0) [0|255] "dimensionless"  DASy
 SG_ RFC_Loc006_ThetaQuality : 216|8@1+ (1,0) [0|255] "dimensionless"  DASy
 SG_ RFC_Loc006_PhiQuality : 224|8@1+ (1,0) [0|255] "dimensionless"  DASy
 SG_ RFC_Loc007_Dr : 256|16@1+ (0.0078125,0) [0|511.9921875] "m"  DASy
 SG_ RFC_Loc007_Vr : 272|16@1+ (0.00390625,-128) [-128|127.99609375] "m/s"  DASy
 SG_ RFC_Loc007_Theta : 288|16@1+ (0.01,-327.68) [-90|90] "deg"  DASy
 SG_ RFC_Loc007_Phi : 304|16@1+ (0.01,-327.68) [-30|30] "deg"  DASy
 SG_ RFC_Loc007_DrVnce : 320|16@1+ (1.52588E-005,0) [0|0.999984741210937] "m^2"  DASy
 SG_ RFC_Loc007_VrVnce : 336|16@1+ (1.52588E-005,0) [0|0.999984741210937] "m^2/s^2"  DASy
 SG_ RFC_Loc007_ThetaVnce : 352|16@1+ (0.00390625,0) [0|255.99609375] "deg^2"  DASy
 SG_ RFC_Loc007_PhiVnce : 368|16@1+ (0.00390625,0) [0|255.99609375] "deg^2"  DASy
 SG_ RFC_Loc007_DrVrCoVnce : 384|16@1+ (3.814697265625E-006,-0.125) [-0.125|0.124996185302734] "m^2/s"  DASy
 SG_ RFC_Loc007_RCS : 400|16@1+ (0.00390625,-128) [-128|127.99609375] "dBsm"  DASy
 SG_ RFC_Loc007_RSSI : 416|16@1+ (0.00195312,0) [0|127.998046875] "dimensionless"  DASy
 SG_ RFC_Loc007_DrVrQuality : 432|8@1+ (1,0) [0|255] "dimensionless"  DASy
 SG_ RFC_Loc007_ThetaQuality : 440|8@1+ (1,0) [0|255] "dimensionless"  DASy
 SG_ RFC_Loc007_PhiQuality : 448|8@1+ (1,0) [0|255] "dimensionless"  DASy

BO_ 404 RFC_Location_008_009: 64 RadarFrontCenter
 SG_ RFC_Loc008_CRC : 0|16@1+ (1,0) [0|65535] ""  DASy
 SG_ RFC_Loc008_AliveCtr : 16|8@1+ (1,0) [0|255] ""  DASy
 SG_ RFC_Loc008_ProtBlockCtr : 24|8@1+ (1,0) [0|255] ""  DASy
 SG_ RFC_Loc008_Dr : 32|16@1+ (0.0078125,0) [0|511.9921875] "m"  DASy
 SG_ RFC_Loc008_Vr : 48|16@1+ (0.00390625,-128) [-128|127.99609375] "m/s"  DASy
 SG_ RFC_Loc008_Theta : 64|16@1+ (0.01,-327.68) [-90|90] "deg"  DASy
 SG_ RFC_Loc008_Phi : 80|16@1+ (0.01,-327.68) [-30|30] "deg"  DASy
 SG_ RFC_Loc008_DrVnce : 96|16@1+ (1.52588E-005,0) [0|0.999984741210937] "m^2"  DASy
 SG_ RFC_Loc008_VrVnce : 112|16@1+ (1.52588E-005,0) [0|0.999984741210937] "m^2/s^2"  DASy
 SG_ RFC_Loc008_ThetaVnce : 128|16@1+ (0.00390625,0) [0|255.99609375] "deg^2"  DASy
 SG_ RFC_Loc008_PhiVnce : 144|16@1+ (0.00390625,0) [0|255.99609375] "deg^2"  DASy
 SG_ RFC_Loc008_DrVrCoVnce : 160|16@1+ (3.814697265625E-006,-0.125) [-0.125|0.124996185302734] "m^2/s"  DASy
 SG_ RFC_Loc008_RCS : 176|16@1+ (0.00390625,-128) [-128|127.99609375] "dBsm"  DASy
 SG_ RFC_Loc008_RSSI : 192|16@1+ (0.00195312,0) [0|127.998046875] "dimensionless"  DASy
 SG_ RFC_Loc008_DrVrQuality : 208|8@1+ (1,0) [0|255] "dimensionless"  DASy
 SG_ RFC_Loc008_ThetaQuality : 216|8@1+ (1,0) [0|255] "dimensionless"  DASy
 SG_ RFC_Loc008_PhiQuality : 224|8@1+ (1,0) [0|255] "dimensionless"  DASy
 SG_ RFC_Loc009_Dr : 256|16@1+ (0.0078125,0) [0|511.9921875] "m"  DASy
 SG_ RFC_Loc009_Vr : 272|16@1+ (0.00390625,-128) [-128|127.99609375] "m/s"  DASy
 SG_ RFC_Loc009_Theta : 288|16@1+ (0.01,-327.68) [-90|90] "deg"  DASy
 SG_ RFC_Loc009_Phi : 304|16@1+ (0.01,-327.68) [-30|30] "deg"  DASy
 SG_ RFC_Loc009_DrVnce : 320|16@1+ (1.52588E-005,0) [0|0.999984741210937] "m^2"  DASy
 SG_ RFC_Loc009_VrVnce : 336|16@1+ (1.52588E-005,0) [0|0.999984741210937] "m^2/s^2"  DASy
 SG_ RFC_Loc009_ThetaVnce : 352|16@1+ (0.00390625,0) [0|255.99609375] "deg^2"  DASy
 SG_ RFC_Loc009_PhiVnce : 368|16@1+ (0.00390625,0) [0|255.99609375] "deg^2"  DASy
 SG_ RFC_Loc009_DrVrCoVnce : 384|16@1+ (3.814697265625E-006,-0.125) [-0.125|0.124996185302734] "m^2/s"  DASy
 SG_ RFC_Loc009_RCS : 400|16@1+ (0.00390625,-128) [-128|127.99609375] "dBsm"  DASy
 SG_ RFC_Loc009_RSSI : 416|16@1+ (0.00195312,0) [0|127.998046875] "dimensionless"  DASy
 SG_ RFC_Loc009_DrVrQuality : 432|8@1+ (1,0) [0|255] "dimensionless"  DASy
 SG_ RFC_Loc009_ThetaQuality : 440|8@1+ (1,0) [0|255] "dimensionless"  DASy
 SG_ RFC_Loc009_PhiQuality : 448|8@1+ (1,0) [0|255] "dimensionless"  DASy

BO_ 405 RFC_Location_010_011: 64 RadarFrontCenter
 SG_ RFC_Loc010_CRC : 0|16@1+ (1,0) [0|65535] ""  DASy
 SG_ RFC_Loc010_AliveCtr : 16|8@1+ (1,0) [0|255] ""  DASy
 SG_ RFC_Loc010_ProtBlockCtr : 24|8@1+ (1,0) [0|255] ""  DASy
 SG_ RFC_Loc010_Dr : 32|16@1+ (0.0078125,0) [0|511.9921875] "m"  DASy
 SG_ RFC_Loc010_Vr : 48|16@1+ (0.00390625,-128) [-128|127.99609375] "m/s"  DASy
 SG_ RFC_Loc010_Theta : 64|16@1+ (0.01,-327.68) [-90|90] "deg"  DASy
 SG_ RFC_Loc010_Phi : 80|16@1+ (0.01,-327.68) [-30|30] "deg"  DASy
 SG_ RFC_Loc010_DrVnce : 96|16@1+ (1.52588E-005,0) [0|0.999984741210937] "m^2"  DASy
 SG_ RFC_Loc010_VrVnce : 112|16@1+ (1.52588E-005,0) [0|0.999984741210937] "m^2/s^2"  DASy
 SG_ RFC_Loc010_ThetaVnce : 128|16@1+ (0.00390625,0) [0|255.99609375] "deg^2"  DASy
 SG_ RFC_Loc010_PhiVnce : 144|16@1+ (0.00390625,0) [0|255.99609375] "deg^2"  DASy
 SG_ RFC_Loc010_DrVrCoVnce : 160|16@1+ (3.814697265625E-006,-0.125) [-0.125|0.124996185302734] "m^2/s"  DASy
 SG_ RFC_Loc010_RCS : 176|16@1+ (0.00390625,-128) [-128|127.99609375] "dBsm"  DASy
 SG_ RFC_Loc010_RSSI : 192|16@1+ (0.00195312,0) [0|127.998046875] "dimensionless"  DASy
 SG_ RFC_Loc010_DrVrQuality : 208|8@1+ (1,0) [0|255] "dimensionless"  DASy
 SG_ RFC_Loc010_ThetaQuality : 216|8@1+ (1,0) [0|255] "dimensionless"  DASy
 SG_ RFC_Loc010_PhiQuality : 224|8@1+ (1,0) [0|255] "dimensionless"  DASy
 SG_ RFC_Loc011_Dr : 256|16@1+ (0.0078125,0) [0|511.9921875] "m"  DASy
 SG_ RFC_Loc011_Vr : 272|16@1+ (0.00390625,-128) [-128|127.99609375] "m/s"  DASy
 SG_ RFC_Loc011_Theta : 288|16@1+ (0.01,-327.68) [-90|90] "deg"  DASy
 SG_ RFC_Loc011_Phi : 304|16@1+ (0.01,-327.68) [-30|30] "deg"  DASy
 SG_ RFC_Loc011_DrVnce : 320|16@1+ (1.52588E-005,0) [0|0.999984741210937] "m^2"  DASy
 SG_ RFC_Loc011_VrVnce : 336|16@1+ (1.52588E-005,0) [0|0.999984741210937] "m^2/s^2"  DASy
 SG_ RFC_Loc011_ThetaVnce : 352|16@1+ (0.00390625,0) [0|255.99609375] "deg^2"  DASy
 SG_ RFC_Loc011_PhiVnce : 368|16@1+ (0.00390625,0) [0|255.99609375] "deg^2"  DASy
 SG_ RFC_Loc011_DrVrCoVnce : 384|16@1+ (3.814697265625E-006,-0.125) [-0.125|0.124996185302734] "m^2/s"  DASy
 SG_ RFC_Loc011_RCS : 400|16@1+ (0.00390625,-128) [-128|127.99609375] "dBsm"  DASy
 SG_ RFC_Loc011_RSSI : 416|16@1+ (0.00195312,0) [0|127.998046875] "dimensionless"  DASy
 SG_ RFC_Loc011_DrVrQuality : 432|8@1+ (1,0) [0|255] "dimensionless"  DASy
 SG_ RFC_Loc011_ThetaQuality : 440|8@1+ (1,0) [0|255] "dimensionless"  DASy
 SG_ RFC_Loc011_PhiQuality : 448|8@1+ (1,0) [0|255] "dimensionless"  DASy

BO_ 406 RFC_Location_012_013: 64 RadarFrontCenter
 SG_ RFC_Loc012_CRC : 0|16@1+ (1,0) [0|65535] ""  DASy
 SG_ RFC_Loc012_AliveCtr : 16|8@1+ (1,0) [0|255] ""  DASy
 SG_ RFC_Loc012_ProtBlockCtr : 24|8@1+ (1,0) [0|255] ""  DASy
 SG_ RFC_Loc012_Dr : 32|16@1+ (0.0078125,0) [0|511.9921875] "m"  DASy
 SG_ RFC_Loc012_Vr : 48|16@1+ (0.00390625,-128) [-128|127.99609375] "m/s"  DASy
 SG_ RFC_Loc012_Theta : 64|16@1+ (0.01,-327.68) [-90|90] "deg"  DASy
 SG_ RFC_Loc012_Phi : 80|16@1+ (0.01,-327.68) [-30|30] "deg"  DASy
 SG_ RFC_Loc012_DrVnce : 96|16@1+ (1.52588E-005,0) [0|0.999984741210937] "m^2"  DASy
 SG_ RFC_Loc012_VrVnce : 112|16@1+ (1.52588E-005,0) [0|0.999984741210937] "m^2/s^2"  DASy
 SG_ RFC_Loc012_ThetaVnce : 128|16@1+ (0.00390625,0) [0|255.99609375] "deg^2"  DASy
 SG_ RFC_Loc012_PhiVnce : 144|16@1+ (0.00390625,0) [0|255.99609375] "deg^2"  DASy
 SG_ RFC_Loc012_DrVrCoVnce : 160|16@1+ (3.814697265625E-006,-0.125) [-0.125|0.124996185302734] "m^2/s"  DASy
 SG_ RFC_Loc012_RCS : 176|16@1+ (0.00390625,-128) [-128|127.99609375] "dBsm"  DASy
 SG_ RFC_Loc012_RSSI : 192|16@1+ (0.00195312,0) [0|127.998046875] "dimensionless"  DASy
 SG_ RFC_Loc012_DrVrQuality : 208|8@1+ (1,0) [0|255] "dimensionless"  DASy
 SG_ RFC_Loc012_ThetaQuality : 216|8@1+ (1,0) [0|255] "dimensionless"  DASy
 SG_ RFC_Loc012_PhiQuality : 224|8@1+ (1,0) [0|255] "dimensionless"  DASy
 SG_ RFC_Loc013_Dr : 256|16@1+ (0.0078125,0) [0|511.9921875] "m"  DASy
 SG_ RFC_Loc013_Vr : 272|16@1+ (0.00390625,-128) [-128|127.99609375] "m/s"  DASy
 SG_ RFC_Loc013_Theta : 288|16@1+ (0.01,-327.68) [-90|90] "deg"  DASy
 SG_ RFC_Loc013_Phi : 304|16@1+ (0.01,-327.68) [-30|30] "deg"  DASy
 SG_ RFC_Loc013_DrVnce : 320|16@1+ (1.52588E-005,0) [0|0.999984741210937] "m^2"  DASy
 SG_ RFC_Loc013_VrVnce : 336|16@1+ (1.52588E-005,0) [0|0.999984741210937] "m^2/s^2"  DASy
 SG_ RFC_Loc013_ThetaVnce : 352|16@1+ (0.00390625,0) [0|255.99609375] "deg^2"  DASy
 SG_ RFC_Loc013_PhiVnce : 368|16@1+ (0.00390625,0) [0|255.99609375] "deg^2"  DASy
 SG_ RFC_Loc013_DrVrCoVnce : 384|16@1+ (3.814697265625E-006,-0.125) [-0.125|0.124996185302734] "m^2/s"  DASy
 SG_ RFC_Loc013_RCS : 400|16@1+ (0.00390625,-128) [-128|127.99609375] "dBsm"  DASy
 SG_ RFC_Loc013_RSSI : 416|16@1+ (0.00195312,0) [0|127.998046875] "dimensionless"  DASy
 SG_ RFC_Loc013_DrVrQuality : 432|8@1+ (1,0) [0|255] "dimensionless"  DASy
 SG_ RFC_Loc013_ThetaQuality : 440|8@1+ (1,0) [0|255] "dimensionless"  DASy
 SG_ RFC_Loc013_PhiQuality : 448|8@1+ (1,0) [0|255] "dimensionless"  DASy

BO_ 407 RFC_Location_014_015: 64 RadarFrontCenter
 SG_ RFC_Loc014_CRC : 0|16@1+ (1,0) [0|65535] ""  DASy
 SG_ RFC_Loc014_AliveCtr : 16|8@1+ (1,0) [0|255] ""  DASy
 SG_ RFC_Loc014_ProtBlockCtr : 24|8@1+ (1,0) [0|255] ""  DASy
 SG_ RFC_Loc014_Dr : 32|16@1+ (0.0078125,0) [0|511.9921875] "m"  DASy
 SG_ RFC_Loc014_Vr : 48|16@1+ (0.00390625,-128) [-128|127.99609375] "m/s"  DASy
 SG_ RFC_Loc014_Theta : 64|16@1+ (0.01,-327.68) [-90|90] "deg"  DASy
 SG_ RFC_Loc014_Phi : 80|16@1+ (0.01,-327.68) [-30|30] "deg"  DASy
 SG_ RFC_Loc014_DrVnce : 96|16@1+ (1.52588E-005,0) [0|0.999984741210937] "m^2"  DASy
 SG_ RFC_Loc014_VrVnce : 112|16@1+ (1.52588E-005,0) [0|0.999984741210937] "m^2/s^2"  DASy
 SG_ RFC_Loc014_ThetaVnce : 128|16@1+ (0.00390625,0) [0|255.99609375] "deg^2"  DASy
 SG_ RFC_Loc014_PhiVnce : 144|16@1+ (0.00390625,0) [0|255.99609375] "deg^2"  DASy
 SG_ RFC_Loc014_DrVrCoVnce : 160|16@1+ (3.814697265625E-006,-0.125) [-0.125|0.124996185302734] "m^2/s"  DASy
 SG_ RFC_Loc014_RCS : 176|16@1+ (0.00390625,-128) [-128|127.99609375] "dBsm"  DASy
 SG_ RFC_Loc014_RSSI : 192|16@1+ (0.00195312,0) [0|127.998046875] "dimensionless"  DASy
 SG_ RFC_Loc014_DrVrQuality : 208|8@1+ (1,0) [0|255] "dimensionless"  DASy
 SG_ RFC_Loc014_ThetaQuality : 216|8@1+ (1,0) [0|255] "dimensionless"  DASy
 SG_ RFC_Loc014_PhiQuality : 224|8@1+ (1,0) [0|255] "dimensionless"  DASy
 SG_ RFC_Loc015_Dr : 256|16@1+ (0.0078125,0) [0|511.9921875] "m"  DASy
 SG_ RFC_Loc015_Vr : 272|16@1+ (0.00390625,-128) [-128|127.99609375] "m/s"  DASy
 SG_ RFC_Loc015_Theta : 288|16@1+ (0.01,-327.68) [-90|90] "deg"  DASy
 SG_ RFC_Loc015_Phi : 304|16@1+ (0.01,-327.68) [-30|30] "deg"  DASy
 SG_ RFC_Loc015_DrVnce : 320|16@1+ (1.52588E-005,0) [0|0.999984741210937] "m^2"  DASy
 SG_ RFC_Loc015_VrVnce : 336|16@1+ (1.52588E-005,0) [0|0.999984741210937] "m^2/s^2"  DASy
 SG_ RFC_Loc015_ThetaVnce : 352|16@1+ (0.00390625,0) [0|255.99609375] "deg^2"  DASy
 SG_ RFC_Loc015_PhiVnce : 368|16@1+ (0.00390625,0) [0|255.99609375] "deg^2"  DASy
 SG_ RFC_Loc015_DrVrCoVnce : 384|16@1+ (3.814697265625E-006,-0.125) [-0.125|0.124996185302734] "m^2/s"  DASy
 SG_ RFC_Loc015_RCS : 400|16@1+ (0.00390625,-128) [-128|127.99609375] "dBsm"  DASy
 SG_ RFC_Loc015_RSSI : 416|16@1+ (0.00195312,0) [0|127.998046875] "dimensionless"  DASy
 SG_ RFC_Loc015_DrVrQuality : 432|8@1+ (1,0) [0|255] "dimensionless"  DASy
 SG_ RFC_Loc015_ThetaQuality : 440|8@1+ (1,0) [0|255] "dimensionless"  DASy
 SG_ RFC_Loc015_PhiQuality : 448|8@1+ (1,0) [0|255] "dimensionless"  DASy

BO_ 408 RFC_Location_016_017: 64 RadarFrontCenter
 SG_ RFC_Loc016_CRC : 0|16@1+ (1,0) [0|65535] ""  DASy
 SG_ RFC_Loc016_AliveCtr : 16|8@1+ (1,0) [0|255] ""  DASy
 SG_ RFC_Loc016_ProtBlockCtr : 24|8@1+ (1,0) [0|255] ""  DASy
 SG_ RFC_Loc016_Dr : 32|16@1+ (0.0078125,0) [0|511.9921875] "m"  DASy
 SG_ RFC_Loc016_Vr : 48|16@1+ (0.00390625,-128) [-128|127.99609375] "m/s"  DASy
 SG_ RFC_Loc016_Theta : 64|16@1+ (0.01,-327.68) [-90|90] "deg"  DASy
 SG_ RFC_Loc016_Phi : 80|16@1+ (0.01,-327.68) [-30|30] "deg"  DASy
 SG_ RFC_Loc016_DrVnce : 96|16@1+ (1.52588E-005,0) [0|0.999984741210937] "m^2"  DASy
 SG_ RFC_Loc016_VrVnce : 112|16@1+ (1.52588E-005,0) [0|0.999984741210937] "m^2/s^2"  DASy
 SG_ RFC_Loc016_ThetaVnce : 128|16@1+ (0.00390625,0) [0|255.99609375] "deg^2"  DASy
 SG_ RFC_Loc016_PhiVnce : 144|16@1+ (0.00390625,0) [0|255.99609375] "deg^2"  DASy
 SG_ RFC_Loc016_DrVrCoVnce : 160|16@1+ (3.814697265625E-006,-0.125) [-0.125|0.124996185302734] "m^2/s"  DASy
 SG_ RFC_Loc016_RCS : 176|16@1+ (0.00390625,-128) [-128|127.99609375] "dBsm"  DASy
 SG_ RFC_Loc016_RSSI : 192|16@1+ (0.00195312,0) [0|127.998046875] "dimensionless"  DASy
 SG_ RFC_Loc016_DrVrQuality : 208|8@1+ (1,0) [0|255] "dimensionless"  DASy
 SG_ RFC_Loc016_ThetaQuality : 216|8@1+ (1,0) [0|255] "dimensionless"  DASy
 SG_ RFC_Loc016_PhiQuality : 224|8@1+ (1,0) [0|255] "dimensionless"  DASy
 SG_ RFC_Loc017_Dr : 256|16@1+ (0.0078125,0) [0|511.9921875] "m"  DASy
 SG_ RFC_Loc017_Vr : 272|16@1+ (0.00390625,-128) [-128|127.99609375] "m/s"  DASy
 SG_ RFC_Loc017_Theta : 288|16@1+ (0.01,-327.68) [-90|90] "deg"  DASy
 SG_ RFC_Loc017_Phi : 304|16@1+ (0.01,-327.68) [-30|30] "deg"  DASy
 SG_ RFC_Loc017_DrVnce : 320|16@1+ (1.52588E-005,0) [0|0.999984741210937] "m^2"  DASy
 SG_ RFC_Loc017_VrVnce : 336|16@1+ (1.52588E-005,0) [0|0.999984741210937] "m^2/s^2"  DASy
 SG_ RFC_Loc017_ThetaVnce : 352|16@1+ (0.00390625,0) [0|255.99609375] "deg^2"  DASy
 SG_ RFC_Loc017_PhiVnce : 368|16@1+ (0.00390625,0) [0|255.99609375] "deg^2"  DASy
 SG_ RFC_Loc017_DrVrCoVnce : 384|16@1+ (3.814697265625E-006,-0.125) [-0.125|0.124996185302734] "m^2/s"  DASy
 SG_ RFC_Loc017_RCS : 400|16@1+ (0.00390625,-128) [-128|127.99609375] "dBsm"  DASy
 SG_ RFC_Loc017_RSSI : 416|16@1+ (0.00195312,0) [0|127.998046875] "dimensionless"  DASy
 SG_ RFC_Loc017_DrVrQuality : 432|8@1+ (1,0) [0|255] "dimensionless"  DASy
 SG_ RFC_Loc017_ThetaQuality : 440|8@1+ (1,0) [0|255] "dimensionless"  DASy
 SG_ RFC_Loc017_PhiQuality : 448|8@1+ (1,0) [0|255] "dimensionless"  DASy

BO_ 409 RFC_Location_018_019: 64 RadarFrontCenter
 SG_ RFC_Loc018_CRC : 0|16@1+ (1,0) [0|65535] ""  DASy
 SG_ RFC_Loc018_AliveCtr : 16|8@1+ (1,0) [0|255] ""  DASy
 SG_ RFC_Loc018_ProtBlockCtr : 24|8@1+ (1,0) [0|255] ""  DASy
 SG_ RFC_Loc018_Dr : 32|16@1+ (0.0078125,0) [0|511.9921875] "m"  DASy
 SG_ RFC_Loc018_Vr : 48|16@1+ (0.00390625,-128) [-128|127.99609375] "m/s"  DASy
 SG_ RFC_Loc018_Theta : 64|16@1+ (0.01,-327.68) [-90|90] "deg"  DASy
 SG_ RFC_Loc018_Phi : 80|16@1+ (0.01,-327.68) [-30|30] "deg"  DASy
 SG_ RFC_Loc018_DrVnce : 96|16@1+ (1.52588E-005,0) [0|0.999984741210937] "m^2"  DASy
 SG_ RFC_Loc018_VrVnce : 112|16@1+ (1.52588E-005,0) [0|0.999984741210937] "m^2/s^2"  DASy
 SG_ RFC_Loc018_ThetaVnce : 128|16@1+ (0.00390625,0) [0|255.99609375] "deg^2"  DASy
 SG_ RFC_Loc018_PhiVnce : 144|16@1+ (0.00390625,0) [0|255.99609375] "deg^2"  DASy
 SG_ RFC_Loc018_DrVrCoVnce : 160|16@1+ (3.814697265625E-006,-0.125) [-0.125|0.124996185302734] "m^2/s"  DASy
 SG_ RFC_Loc018_RCS : 176|16@1+ (0.00390625,-128) [-128|127.99609375] "dBsm"  DASy
 SG_ RFC_Loc018_RSSI : 192|16@1+ (0.00195312,0) [0|127.998046875] "dimensionless"  DASy
 SG_ RFC_Loc018_DrVrQuality : 208|8@1+ (1,0) [0|255] "dimensionless"  DASy
 SG_ RFC_Loc018_ThetaQuality : 216|8@1+ (1,0) [0|255] "dimensionless"  DASy
 SG_ RFC_Loc018_PhiQuality : 224|8@1+ (1,0) [0|255] "dimensionless"  DASy
 SG_ RFC_Loc019_Dr : 256|16@1+ (0.0078125,0) [0|511.9921875] "m"  DASy
 SG_ RFC_Loc019_Vr : 272|16@1+ (0.00390625,-128) [-128|127.99609375] "m/s"  DASy
 SG_ RFC_Loc019_Theta : 288|16@1+ (0.01,-327.68) [-90|90] "deg"  DASy
 SG_ RFC_Loc019_Phi : 304|16@1+ (0.01,-327.68) [-30|30] "deg"  DASy
 SG_ RFC_Loc019_DrVnce : 320|16@1+ (1.52588E-005,0) [0|0.999984741210937] "m^2"  DASy
 SG_ RFC_Loc019_VrVnce : 336|16@1+ (1.52588E-005,0) [0|0.999984741210937] "m^2/s^2"  DASy
 SG_ RFC_Loc019_ThetaVnce : 352|16@1+ (0.00390625,0) [0|255.99609375] "deg^2"  DASy
 SG_ RFC_Loc019_PhiVnce : 368|16@1+ (0.00390625,0) [0|255.99609375] "deg^2"  DASy
 SG_ RFC_Loc019_DrVrCoVnce : 384|16@1+ (3.814697265625E-006,-0.125) [-0.125|0.124996185302734] "m^2/s"  DASy
 SG_ RFC_Loc019_RCS : 400|16@1+ (0.00390625,-128) [-128|127.99609375] "dBsm"  DASy
 SG_ RFC_Loc019_RSSI : 416|16@1+ (0.00195312,0) [0|127.998046875] "dimensionless"  DASy
 SG_ RFC_Loc019_DrVrQuality : 432|8@1+ (1,0) [0|255] "dimensionless"  DASy
 SG_ RFC_Loc019_ThetaQuality : 440|8@1+ (1,0) [0|255] "dimensionless"  DASy
 SG_ RFC_Loc019_PhiQuality : 448|8@1+ (1,0) [0|255] "dimensionless"  DASy

CM_ SG_ 214 VFC_Obj19A_CRC "CRC - Autosar E2E Profile 5";
CM_ SG_ 214 VFC_Obj19A_AliveCtr "Alive counter - Autosar E2E Profile 5";
CM_ SG_ 214 VFC_Obj19A_BlockCtr "Protocol-Signal: Block-Counter";
CM_ SG_ 214 VFC_Obj19A_ProtOrderIndex "Protocol-Signal: Index to ensure same order in Tx and Rx of the objects";
CM_ SG_ 214 VFC_Obj19A_Ax "Object Acceleration in longitudinal direction";
CM_ SG_ 214 VFC_Obj19A_Vx "Object Velocity in longitudinal direction";
CM_ SG_ 214 VFC_Obj19A_Dx "Object Position in longitudinal direction";
CM_ SG_ 214 VFC_Obj19A_Dy "Object Position in lateral direction";
CM_ SG_ 214 VFC_Obj19A_Vy "Object Velocity in lateral direction";
CM_ SG_ 214 VFC_Obj19A_Ay "Object Acceleration in lateral direction";
CM_ SG_ 214 VFC_Obj19A_DyStdDev "Standard deviation of Object position in lateral direction";
CM_ SG_ 214 VFC_Obj19A_DxStdDev "Standard deviation of Object position in longitudinal direction";
CM_ SG_ 214 VFC_Obj19A_VxStdDev "Standard deviation of Object velocity in longitudinal direction";
CM_ SG_ 214 VFC_Obj19A_ExistProb "Object existence probability";
CM_ SG_ 214 VFC_Obj19A_VyStdDev "Standard deviation of Object velocity in lateral direction";
CM_ SG_ 214 VFC_Obj19A_TypeProb "Probability of the classified object type";
CM_ SG_ 214 VFC_Obj19A_AxStdDev "Standard deviation of Object acceleration in longitudinal direction";
CM_ SG_ 214 VFC_Obj19A_AyStdDev "Standard deviation of Object acceleration in lateral direction";
CM_ SG_ 214 VFC_Obj19A_PhiLeft "ACCS Viewing Angle of left object edge(dimensionless)";
CM_ SG_ 214 VFC_Obj19A_ClassifiedView "The classified view of object to be used in connection with Heading angle";
CM_ SG_ 214 VFC_Obj19A_Length "Length of the object";
CM_ SG_ 214 VFC_Obj19A_WidthStdDev "Standard deviation of object width";
CM_ SG_ 214 VFC_Obj19A_Height "Height of the object";
CM_ SG_ 214 VFC_Obj19A_HeightStdDev "Standard deviation of object height";
CM_ SG_ 214 VFC_Obj19A_PhiLeftStdDev "Standard deviation of the ACCS angle of left object(dimensionless)";
CM_ SG_ 214 VFC_Obj19A_HeadingStdDev "Standard deviation of object Heading angle";
CM_ SG_ 214 VFC_Obj19A_Measured "Indicator if the object detected is measured or predicted.";
CM_ SG_ 214 VFC_Obj19A_Heading "Heading angle of the object";
CM_ SG_ 214 VFC_Obj19A_LengthStdDev "Standard deviation of object length";
CM_ SG_ 214 VFC_Obj19A_PhiMid "Viewing angle of the ACCS middle of the object(dimensionless)";
CM_ SG_ 214 VFC_Obj19A_Width "Width of the object";
CM_ SG_ 214 VFC_Obj19A_PhiMidStdDev "Standard deviation of the ACCS middle angle of object(dimensionless)";
CM_ SG_ 214 VFC_Obj19A_PhiRight "ACCS Viewing Angle of right object edge(dimensionless)";
CM_ SG_ 214 VFC_Obj19A_VisibleView "The visible view of the detectd object";
CM_ SG_ 214 VFC_Obj19A_PhiRightStdDev "Standard deviation of the ACCS angle of right object(dimensionless)";
CM_ SG_ 214 VFC_Obj19A_PhiLeftVel "Velocity of the ACCS viewing angle of the left edge";
CM_ SG_ 214 VFC_Obj19A_PhiRightVel "Velocity of the ACCS viewing angle of the right edge";
CM_ SG_ 214 VFC_Obj19A_PhiRightVelStdDev "Standard deviation of ACCS viewing angle velocity of right object edge from ego vehicle related to camera";
CM_ SG_ 214 VFC_Obj19A_PhiLeftVelStdDev "Standard deviation of ACCS viewing angle velocity of left object edge from ego vehicle related to camera";
CM_ SG_ 214 VFC_Obj19A_PhiTop "ACCS Viewing angle of the top of the object(dimensionless)";
CM_ SG_ 214 VFC_Obj19A_PhiBottom "ACCS Viewing angle of the bottom of the object(dimensionless)";
CM_ SG_ 214 VFC_Obj19A_PhiTopStdDev "Standard deviation  of the ACCS top angle of object(dimensionless)";
CM_ SG_ 214 VFC_Obj19A_HeadOrientation "The orientation of the head of cyclists or pedestrians that are detected.";
CM_ SG_ 214 VFC_Obj19A_Type "Classification of the object";
CM_ SG_ 214 VFC_Obj19A_PhiBottomStdDev "Standard deviation of the ACCS bottom angle of object(dimensionless)";
CM_ SG_ 214 VFC_Obj19A_NormVx "Normalised object velocity in longitudinal direction.";
CM_ SG_ 214 VFC_Obj19A_NormAx "Normalised object acceleration in longitudinal direction.";
CM_ SG_ 214 VFC_Obj19A_NormAxStdDev "Standard deviation of Normalized Object Acceleration in longitudinal direction";
CM_ SG_ 214 VFC_Obj19A_ProbMovingLat "Probability of object moving laterally";
CM_ SG_ 214 VFC_Obj19A_ID "Unique Object ID";
CM_ SG_ 214 VFC_Obj19A_NormVxStdDev "Standard deviation of Normalized Object Velocity in longitudinal direction";
CM_ SG_ 214 VFC_Obj19A_ProbMovingLong "Probability of object moving longitudinally";
CM_ SG_ 215 VFC_Obj19B_TTIPC_StdDev "Inverse TTI standard deviation";
CM_ SG_ 215 VFC_Obj19B_TTIPC "Inverse TTI";
CM_ SG_ 215 VFC_Obj19B_AngLongitude "angular velocity with regarding to longitudinal direction";
CM_ SG_ 215 VFC_Obj19B_CRC "CRC - Autosar E2E Profile 5";
CM_ SG_ 215 VFC_Obj19B_AliveCtr "Alive counter - Autosar E2E Profile 5";
CM_ SG_ 215 VFC_Obj19B_BlockCtr "Protocol-Signal: Block Counter";
CM_ SG_ 215 VFC_Obj19B_ScaleChange "A scale change of of the detected object";
CM_ SG_ 215 VFC_Obj19B_ScaleChngStdDev "Standard deviation of object scale change";
CM_ SG_ 215 VFC_Obj19B_LineEdgeRightEgo "ObjLineEdgeAngle refers to the line which limits the host vehicle lane on the right side";
CM_ SG_ 215 VFC_Obj19B_LineEdgeLeftEgo "ObjLineEdgeAngle refers to the line which limits the host vehicle lane on the left side";
CM_ SG_ 215 VFC_Obj19B_CompletelyInImg "indicator if the object is completely measrued in the image";
CM_ SG_ 215 VFC_Obj19B_DirIndicator "The detected direction indicator lights";
CM_ SG_ 215 VFC_Obj19B_LineEdgeAngle "Angle between the video object's edge and the lane marking";
CM_ SG_ 215 VFC_Obj19B_BrakeLight "The number of detected lights. More confident if more lights are detected.";
CM_ SG_ 215 VFC_Obj19B_MeasSource "Bitmask for the measurement programs from which this object originates";
CM_ SG_ 215 VFC_Obj19B_Reliab "Bitmask that indicates the algorithmic paths that have detected this object";
CM_ SG_ 128 VFC_LineHdr_AUTOSARTStamp "Time stamp when Clothoids measurement, in autosar time sync mode";
CM_ SG_ 128 VFC_LineHdr_FrameNo "The frame number that the data belongs to";
CM_ SG_ 128 VFC_LineHdr_CRC "CRC - Autosar E2E Profile 5";
CM_ SG_ 128 VFC_LineHdr_AliveCtr "Alive counter - Autosar E2E Profile 5";
CM_ SG_ 128 VFC_LineHdr_BlockCounter "Protocol-Signal:Blockcounter";
CM_ SG_ 128 VFC_LineHdr_Report "Bitmask for Errors if PEPSI was not executed";
CM_ SG_ 128 VFC_LineHdr_LineCount "Number of Lines to be send (max 15)";
CM_ SG_ 128 VFC_LineHdr_PEPSIRuntime "Last runtime of the PEPSI Algorithm. As PEPSI does runtime management, this can be used as an indicator for the quality of the results.";
CM_ SG_ 128 VFC_LineHdr_TimeStamp "TimeStamp of Clothoids when lines are measured, for 1R1V sensor set";
CM_ SG_ 128 VFC_LineHdr_Blindness "Blindness Indicator for Lines";
CM_ SG_ 128 VFC_LineHdr_State "Informs the system of the current state of the camera";
CM_ SG_ 129 VFC_Line01_CRC "CRC - Autosar E2E Profile 5";
CM_ SG_ 129 VFC_Line01_AliveCtr "Alive counter - Autosar E2E Profile 5";
CM_ SG_ 129 VFC_Line01_BlockCounter "Protocol-Signal:Blockcounter";
CM_ SG_ 129 VFC_Line01_ProtOrderIndex "Protocol-Signal: Index to ensure same order in Tx and Rx of the clothoids";
CM_ SG_ 129 VFC_Line01_LineID "Object ID is used to order the Objects in line";
CM_ SG_ 129 VFC_Line01_LaneRelation "Indicating its position relative to the ego lane";
CM_ SG_ 129 VFC_Line01_ExistProb "Confidence for this line";
CM_ SG_ 129 VFC_Line01_DxStart "Longitudinal start point of the line, also called dxStart";
CM_ SG_ 129 VFC_Line01_ColorClass "The color of the line";
CM_ SG_ 129 VFC_Line01_DxEnd "Longitudinal range of the line, also called dxEnd";
CM_ SG_ 129 VFC_Line01_HeadingAngle "Heading angle, difference in yaw angle between vehicle heading and Line";
CM_ SG_ 129 VFC_Line01_Dy "Dy at position of DxStart  (not always x=0, because of high values for 2nd segment)";
CM_ SG_ 129 VFC_Line01_CurvChange "Currvature change or alteration of the Line, also called kappaDt";
CM_ SG_ 129 VFC_Line01_Curv "Curvature of the Line, also called kappa";
CM_ SG_ 129 VFC_Line01_MeasureType "Indicates if Line was measured, interpolated or inferred (virtual line)";
CM_ SG_ 129 VFC_Line01_LineWidth "Width of the line";
CM_ SG_ 129 VFC_Line01_CourseDeviation "Confidence measure quantifying a weighted deviation between course/path and the predicted lane";
CM_ SG_ 129 VFC_Line01_Type "Type of the Line";
CM_ SG_ 129 VFC_Line01_DyStdDevDxEnd "Standard deviation of the lateral offset, at point of DxEnd";
CM_ SG_ 129 VFC_Line01_HypoConfidence "multiple hypothesis info. from Video (ambiguity ID)";
CM_ SG_ 129 VFC_Line01_prevID "when in multi-segment, prevID is used to show that the current line ID is from which previous ID";
CM_ SG_ 129 VFC_Line01_nextID "when in multi-segment, nextID is used to show that which line ID is next to the current line ID";
CM_ SG_ 129 VFC_Line01_DyStdDevDxStart "Standard deviation of the lateral offset, at point of DxStart";
CM_ SG_ 129 VFC_Line01_TypeProb "Confidence measure for Type classification";
CM_ SG_ 129 VFC_Line01_DyStdDevDxMid "Standard deviation of the lateral offset, at point of DxMid, DyStdDevDxMid (dxMid = (dxEnd-dxStart)/2 )";
CM_ SG_ 130 VFC_Line02_CRC "CRC - Autosar E2E Profile 5";
CM_ SG_ 130 VFC_Line02_AliveCtr "Alive counter - Autosar E2E Profile 5";
CM_ SG_ 130 VFC_Line02_BlockCounter "Protocol-Signal:Blockcounter";
CM_ SG_ 130 VFC_Line02_ProtOrderIndex "Protocol-Signal: Index to ensure same order in Tx and Rx of the clothoids";
CM_ SG_ 130 VFC_Line02_LineID "Object ID is used to order the Objects in line";
CM_ SG_ 130 VFC_Line02_LaneRelation "Indicating its position relative to the ego lane";
CM_ SG_ 130 VFC_Line02_ExistProb "Confidence for this line";
CM_ SG_ 130 VFC_Line02_DxStart "Longitudinal start point of the line, also called dxStart";
CM_ SG_ 130 VFC_Line02_ColorClass "The color of the line";
CM_ SG_ 130 VFC_Line02_DxEnd "Longitudinal range of the line, also called dxEnd";
CM_ SG_ 130 VFC_Line02_HeadingAngle "Heading angle, difference in yaw angle between vehicle heading and Line";
CM_ SG_ 130 VFC_Line02_Dy "Dy at position of DxStart  (not always x=0, because of high values for 2nd segment)";
CM_ SG_ 130 VFC_Line02_CurvChange "Currvature change or alteration of the Line, also called kappaDt";
CM_ SG_ 130 VFC_Line02_Curv "Curvature of the Line, also called kappa";
CM_ SG_ 130 VFC_Line02_MeasureType "Indicates if Line was measured, interpolated or inferred (virtual line)";
CM_ SG_ 130 VFC_Line02_LineWidth "Width of the line";
CM_ SG_ 130 VFC_Line02_CourseDeviation "Confidence measure quantifying a weighted deviation between course/path and the predicted lane";
CM_ SG_ 130 VFC_Line02_Type "Type of the Line";
CM_ SG_ 130 VFC_Line02_DyStdDevDxEnd "Standard deviation of the lateral offset, at point of DxEnd";
CM_ SG_ 130 VFC_Line02_HypoConfidence "multiple hypothesis info. from Video (ambiguity ID)";
CM_ SG_ 130 VFC_Line02_prevID "when in multi-segment, prevID is used to show that the current line ID is from which previous ID";
CM_ SG_ 130 VFC_Line02_nextID "when in multi-segment, nextID is used to show that which line ID is next to the current line ID";
CM_ SG_ 130 VFC_Line02_DyStdDevDxStart "Standard deviation of the lateral offset, at point of DxStart";
CM_ SG_ 130 VFC_Line02_TypeProb "Confidence measure for Type classification";
CM_ SG_ 130 VFC_Line02_DyStdDevDxMid "Standard deviation of the lateral offset, at point of DxMid, DyStdDevDxMid (dxMid = (dxEnd-dxStart)/2 )";
CM_ SG_ 131 VFC_Line03_CRC "CRC - Autosar E2E Profile 5";
CM_ SG_ 131 VFC_Line03_AliveCtr "Alive counter - Autosar E2E Profile 5";
CM_ SG_ 131 VFC_Line03_BlockCounter "Protocol-Signal:Blockcounter";
CM_ SG_ 131 VFC_Line03_ProtOrderIndex "Protocol-Signal: Index to ensure same order in Tx and Rx of the clothoids";
CM_ SG_ 131 VFC_Line03_LineID "Object ID is used to order the Objects in line";
CM_ SG_ 131 VFC_Line03_LaneRelation "Indicating its position relative to the ego lane";
CM_ SG_ 131 VFC_Line03_ExistProb "Confidence for this line";
CM_ SG_ 131 VFC_Line03_DxStart "Longitudinal start point of the line, also called dxStart";
CM_ SG_ 131 VFC_Line03_ColorClass "The color of the line";
CM_ SG_ 131 VFC_Line03_DxEnd "Longitudinal range of the line, also called dxEnd";
CM_ SG_ 131 VFC_Line03_HeadingAngle "Heading angle, difference in yaw angle between vehicle heading and Line";
CM_ SG_ 131 VFC_Line03_Dy "Dy at position of DxStart  (not always x=0, because of high values for 2nd segment)";
CM_ SG_ 131 VFC_Line03_CurvChange "Currvature change or alteration of the Line, also called kappaDt";
CM_ SG_ 131 VFC_Line03_Curv "Curvature of the Line, also called kappa";
CM_ SG_ 131 VFC_Line03_MeasureType "Indicates if Line was measured, interpolated or inferred (virtual line)";
CM_ SG_ 131 VFC_Line03_LineWidth "Width of the line";
CM_ SG_ 131 VFC_Line03_CourseDeviation "Confidence measure quantifying a weighted deviation between course/path and the predicted lane";
CM_ SG_ 131 VFC_Line03_Type "Type of the Line";
CM_ SG_ 131 VFC_Line03_DyStdDevDxEnd "Standard deviation of the lateral offset, at point of DxEnd";
CM_ SG_ 131 VFC_Line03_HypoConfidence "multiple hypothesis info. from Video (ambiguity ID)";
CM_ SG_ 131 VFC_Line03_prevID "when in multi-segment, prevID is used to show that the current line ID is from which previous ID";
CM_ SG_ 131 VFC_Line03_nextID "when in multi-segment, nextID is used to show that which line ID is next to the current line ID";
CM_ SG_ 131 VFC_Line03_DyStdDevDxStart "Standard deviation of the lateral offset, at point of DxStart";
CM_ SG_ 131 VFC_Line03_TypeProb "Confidence measure for Type classification";
CM_ SG_ 131 VFC_Line03_DyStdDevDxMid "Standard deviation of the lateral offset, at point of DxMid, DyStdDevDxMid (dxMid = (dxEnd-dxStart)/2 )";
CM_ SG_ 132 VFC_Line04_CRC "CRC - Autosar E2E Profile 5";
CM_ SG_ 132 VFC_Line04_AliveCtr "Alive counter - Autosar E2E Profile 5";
CM_ SG_ 132 VFC_Line04_BlockCounter "Protocol-Signal:Blockcounter";
CM_ SG_ 132 VFC_Line04_ProtOrderIndex "Protocol-Signal: Index to ensure same order in Tx and Rx of the clothoids";
CM_ SG_ 132 VFC_Line04_LineID "Object ID is used to order the Objects in line";
CM_ SG_ 132 VFC_Line04_LaneRelation "Indicating its position relative to the ego lane";
CM_ SG_ 132 VFC_Line04_ExistProb "Confidence for this line";
CM_ SG_ 132 VFC_Line04_DxStart "Longitudinal start point of the line, also called dxStart";
CM_ SG_ 132 VFC_Line04_ColorClass "The color of the line";
CM_ SG_ 132 VFC_Line04_DxEnd "Longitudinal range of the line, also called dxEnd";
CM_ SG_ 132 VFC_Line04_HeadingAngle "Heading angle, difference in yaw angle between vehicle heading and Line";
CM_ SG_ 132 VFC_Line04_Dy "Dy at position of DxStart  (not always x=0, because of high values for 2nd segment)";
CM_ SG_ 132 VFC_Line04_CurvChange "Currvature change or alteration of the Line, also called kappaDt";
CM_ SG_ 132 VFC_Line04_Curv "Curvature of the Line, also called kappa";
CM_ SG_ 132 VFC_Line04_MeasureType "Indicates if Line was measured, interpolated or inferred (virtual line)";
CM_ SG_ 132 VFC_Line04_LineWidth "Width of the line";
CM_ SG_ 132 VFC_Line04_CourseDeviation "Confidence measure quantifying a weighted deviation between course/path and the predicted lane";
CM_ SG_ 132 VFC_Line04_Type "Type of the Line";
CM_ SG_ 132 VFC_Line04_DyStdDevDxEnd "Standard deviation of the lateral offset, at point of DxEnd";
CM_ SG_ 132 VFC_Line04_HypoConfidence "multiple hypothesis info. from Video (ambiguity ID)";
CM_ SG_ 132 VFC_Line04_prevID "when in multi-segment, prevID is used to show that the current line ID is from which previous ID";
CM_ SG_ 132 VFC_Line04_nextID "when in multi-segment, nextID is used to show that which line ID is next to the current line ID";
CM_ SG_ 132 VFC_Line04_DyStdDevDxStart "Standard deviation of the lateral offset, at point of DxStart";
CM_ SG_ 132 VFC_Line04_TypeProb "Confidence measure for Type classification";
CM_ SG_ 132 VFC_Line04_DyStdDevDxMid "Standard deviation of the lateral offset, at point of DxMid, DyStdDevDxMid (dxMid = (dxEnd-dxStart)/2 )";
CM_ SG_ 133 VFC_Line05_CRC "CRC - Autosar E2E Profile 5";
CM_ SG_ 133 VFC_Line05_AliveCtr "Alive counter - Autosar E2E Profile 5";
CM_ SG_ 133 VFC_Line05_BlockCounter "Protocol-Signal:Blockcounter";
CM_ SG_ 133 VFC_Line05_ProtOrderIndex "Protocol-Signal: Index to ensure same order in Tx and Rx of the clothoids";
CM_ SG_ 133 VFC_Line05_LineID "Object ID is used to order the Objects in line";
CM_ SG_ 133 VFC_Line05_LaneRelation "Indicating its position relative to the ego lane";
CM_ SG_ 133 VFC_Line05_ExistProb "Confidence for this line";
CM_ SG_ 133 VFC_Line05_DxStart "Longitudinal start point of the line, also called dxStart";
CM_ SG_ 133 VFC_Line05_ColorClass "The color of the line";
CM_ SG_ 133 VFC_Line05_DxEnd "Longitudinal range of the line, also called dxEnd";
CM_ SG_ 133 VFC_Line05_HeadingAngle "Heading angle, difference in yaw angle between vehicle heading and Line";
CM_ SG_ 133 VFC_Line05_Dy "Dy at position of DxStart  (not always x=0, because of high values for 2nd segment)";
CM_ SG_ 133 VFC_Line05_CurvChange "Currvature change or alteration of the Line, also called kappaDt";
CM_ SG_ 133 VFC_Line05_Curv "Curvature of the Line, also called kappa";
CM_ SG_ 133 VFC_Line05_MeasureType "Indicates if Line was measured, interpolated or inferred (virtual line)";
CM_ SG_ 133 VFC_Line05_LineWidth "Width of the line";
CM_ SG_ 133 VFC_Line05_CourseDeviation "Confidence measure quantifying a weighted deviation between course/path and the predicted lane";
CM_ SG_ 133 VFC_Line05_Type "Type of the Line";
CM_ SG_ 133 VFC_Line05_DyStdDevDxEnd "Standard deviation of the lateral offset, at point of DxEnd";
CM_ SG_ 133 VFC_Line05_HypoConfidence "multiple hypothesis info. from Video (ambiguity ID)";
CM_ SG_ 133 VFC_Line05_prevID "when in multi-segment, prevID is used to show that the current line ID is from which previous ID";
CM_ SG_ 133 VFC_Line05_nextID "when in multi-segment, nextID is used to show that which line ID is next to the current line ID";
CM_ SG_ 133 VFC_Line05_DyStdDevDxStart "Standard deviation of the lateral offset, at point of DxStart";
CM_ SG_ 133 VFC_Line05_TypeProb "Confidence measure for Type classification";
CM_ SG_ 133 VFC_Line05_DyStdDevDxMid "Standard deviation of the lateral offset, at point of DxMid, DyStdDevDxMid (dxMid = (dxEnd-dxStart)/2 )";
CM_ SG_ 134 VFC_Line06_CRC "CRC - Autosar E2E Profile 5";
CM_ SG_ 134 VFC_Line06_AliveCtr "Alive counter - Autosar E2E Profile 5";
CM_ SG_ 134 VFC_Line06_BlockCounter "Protocol-Signal:Blockcounter";
CM_ SG_ 134 VFC_Line06_ProtOrderIndex "Protocol-Signal: Index to ensure same order in Tx and Rx of the clothoids";
CM_ SG_ 134 VFC_Line06_LineID "Object ID is used to order the Objects in line";
CM_ SG_ 134 VFC_Line06_LaneRelation "Indicating its position relative to the ego lane";
CM_ SG_ 134 VFC_Line06_ExistProb "Confidence for this line";
CM_ SG_ 134 VFC_Line06_DxStart "Longitudinal start point of the line, also called dxStart";
CM_ SG_ 134 VFC_Line06_ColorClass "The color of the line";
CM_ SG_ 134 VFC_Line06_DxEnd "Longitudinal range of the line, also called dxEnd";
CM_ SG_ 134 VFC_Line06_HeadingAngle "Heading angle, difference in yaw angle between vehicle heading and Line";
CM_ SG_ 134 VFC_Line06_Dy "Dy at position of DxStart  (not always x=0, because of high values for 2nd segment)";
CM_ SG_ 134 VFC_Line06_CurvChange "Currvature change or alteration of the Line, also called kappaDt";
CM_ SG_ 134 VFC_Line06_Curv "Curvature of the Line, also called kappa";
CM_ SG_ 134 VFC_Line06_MeasureType "Indicates if Line was measured, interpolated or inferred (virtual line)";
CM_ SG_ 134 VFC_Line06_LineWidth "Width of the line";
CM_ SG_ 134 VFC_Line06_CourseDeviation "Confidence measure quantifying a weighted deviation between course/path and the predicted lane";
CM_ SG_ 134 VFC_Line06_Type "Type of the Line";
CM_ SG_ 134 VFC_Line06_DyStdDevDxEnd "Standard deviation of the lateral offset, at point of DxEnd";
CM_ SG_ 134 VFC_Line06_HypoConfidence "multiple hypothesis info. from Video (ambiguity ID)";
CM_ SG_ 134 VFC_Line06_prevID "when in multi-segment, prevID is used to show that the current line ID is from which previous ID";
CM_ SG_ 134 VFC_Line06_nextID "when in multi-segment, nextID is used to show that which line ID is next to the current line ID";
CM_ SG_ 134 VFC_Line06_DyStdDevDxStart "Standard deviation of the lateral offset, at point of DxStart";
CM_ SG_ 134 VFC_Line06_TypeProb "Confidence measure for Type classification";
CM_ SG_ 134 VFC_Line06_DyStdDevDxMid "Standard deviation of the lateral offset, at point of DxMid, DyStdDevDxMid (dxMid = (dxEnd-dxStart)/2 )";
CM_ SG_ 135 VFC_Line07_CRC "CRC - Autosar E2E Profile 5";
CM_ SG_ 135 VFC_Line07_AliveCtr "Alive counter - Autosar E2E Profile 5";
CM_ SG_ 135 VFC_Line07_BlockCounter "Protocol-Signal:Blockcounter";
CM_ SG_ 135 VFC_Line07_ProtOrderIndex "Protocol-Signal: Index to ensure same order in Tx and Rx of the clothoids";
CM_ SG_ 135 VFC_Line07_LineID "Object ID is used to order the Objects in line";
CM_ SG_ 135 VFC_Line07_LaneRelation "Indicating its position relative to the ego lane";
CM_ SG_ 135 VFC_Line07_ExistProb "Confidence for this line";
CM_ SG_ 135 VFC_Line07_DxStart "Longitudinal start point of the line, also called dxStart";
CM_ SG_ 135 VFC_Line07_ColorClass "The color of the line";
CM_ SG_ 135 VFC_Line07_DxEnd "Longitudinal range of the line, also called dxEnd";
CM_ SG_ 135 VFC_Line07_HeadingAngle "Heading angle, difference in yaw angle between vehicle heading and Line";
CM_ SG_ 135 VFC_Line07_Dy "Dy at position of DxStart  (not always x=0, because of high values for 2nd segment)";
CM_ SG_ 135 VFC_Line07_CurvChange "Currvature change or alteration of the Line, also called kappaDt";
CM_ SG_ 135 VFC_Line07_Curv "Curvature of the Line, also called kappa";
CM_ SG_ 135 VFC_Line07_MeasureType "Indicates if Line was measured, interpolated or inferred (virtual line)";
CM_ SG_ 135 VFC_Line07_LineWidth "Width of the line";
CM_ SG_ 135 VFC_Line07_CourseDeviation "Confidence measure quantifying a weighted deviation between course/path and the predicted lane";
CM_ SG_ 135 VFC_Line07_Type "Type of the Line";
CM_ SG_ 135 VFC_Line07_DyStdDevDxEnd "Standard deviation of the lateral offset, at point of DxEnd";
CM_ SG_ 135 VFC_Line07_HypoConfidence "multiple hypothesis info. from Video (ambiguity ID)";
CM_ SG_ 135 VFC_Line07_prevID "when in multi-segment, prevID is used to show that the current line ID is from which previous ID";
CM_ SG_ 135 VFC_Line07_nextID "when in multi-segment, nextID is used to show that which line ID is next to the current line ID";
CM_ SG_ 135 VFC_Line07_DyStdDevDxStart "Standard deviation of the lateral offset, at point of DxStart";
CM_ SG_ 135 VFC_Line07_TypeProb "Confidence measure for Type classification";
CM_ SG_ 135 VFC_Line07_DyStdDevDxMid "Standard deviation of the lateral offset, at point of DxMid, DyStdDevDxMid (dxMid = (dxEnd-dxStart)/2 )";
CM_ SG_ 136 VFC_Line08_CRC "CRC - Autosar E2E Profile 5";
CM_ SG_ 136 VFC_Line08_AliveCtr "Alive counter - Autosar E2E Profile 5";
CM_ SG_ 136 VFC_Line08_BlockCounter "Protocol-Signal:Blockcounter";
CM_ SG_ 136 VFC_Line08_ProtOrderIndex "Protocol-Signal: Index to ensure same order in Tx and Rx of the clothoids";
CM_ SG_ 136 VFC_Line08_LineID "Object ID is used to order the Objects in line";
CM_ SG_ 136 VFC_Line08_LaneRelation "Indicating its position relative to the ego lane";
CM_ SG_ 136 VFC_Line08_ExistProb "Confidence for this line";
CM_ SG_ 136 VFC_Line08_DxStart "Longitudinal start point of the line, also called dxStart";
CM_ SG_ 136 VFC_Line08_ColorClass "The color of the line";
CM_ SG_ 136 VFC_Line08_DxEnd "Longitudinal range of the line, also called dxEnd";
CM_ SG_ 136 VFC_Line08_HeadingAngle "Heading angle, difference in yaw angle between vehicle heading and Line";
CM_ SG_ 136 VFC_Line08_Dy "Dy at position of DxStart  (not always x=0, because of high values for 2nd segment)";
CM_ SG_ 136 VFC_Line08_CurvChange "Currvature change or alteration of the Line, also called kappaDt";
CM_ SG_ 136 VFC_Line08_Curv "Curvature of the Line, also called kappa";
CM_ SG_ 136 VFC_Line08_MeasureType "Indicates if Line was measured, interpolated or inferred (virtual line)";
CM_ SG_ 136 VFC_Line08_LineWidth "Width of the line";
CM_ SG_ 136 VFC_Line08_CourseDeviation "Confidence measure quantifying a weighted deviation between course/path and the predicted lane";
CM_ SG_ 136 VFC_Line08_Type "Type of the Line";
CM_ SG_ 136 VFC_Line08_DyStdDevDxEnd "Standard deviation of the lateral offset, at point of DxEnd";
CM_ SG_ 136 VFC_Line08_HypoConfidence "multiple hypothesis info. from Video (ambiguity ID)";
CM_ SG_ 136 VFC_Line08_prevID "when in multi-segment, prevID is used to show that the current line ID is from which previous ID";
CM_ SG_ 136 VFC_Line08_nextID "when in multi-segment, nextID is used to show that which line ID is next to the current line ID";
CM_ SG_ 136 VFC_Line08_DyStdDevDxStart "Standard deviation of the lateral offset, at point of DxStart";
CM_ SG_ 136 VFC_Line08_TypeProb "Confidence measure for Type classification";
CM_ SG_ 136 VFC_Line08_DyStdDevDxMid "Standard deviation of the lateral offset, at point of DxMid, DyStdDevDxMid (dxMid = (dxEnd-dxStart)/2 )";
CM_ BO_ 930 "Speed limit value, from video to DASy";
CM_ SG_ 930 VFC_TSR_ASL_CRC "CRC - Autosar E2E Profile 5";
CM_ SG_ 930 VFC_TSR_ASL_AliveCtr "Alive counter - Autosar E2E Profile 5";
CM_ SG_ 930 VFC_ADAS_ModSts_SLA "SLA mode status, from BJEV ASL spec V0.8";
CM_ SG_ 930 VFC_ADAS_SpdLim_SLA "Speed limit value, from BJEV ASL spec V0.8";
CM_ SG_ 930 VFC_ADAS_SpdLimUnit_SLA "Speed limit unit, from BJEV ASL spec V0.8";
CM_ SG_ 384 RFC_Hdr00_CRC "CRC - Autosar E2E Profile 5";
CM_ SG_ 384 RFC_Hdr00_AliveCtr "Alive counter - Autosar E2E Profile 5";
CM_ SG_ 384 RFC_Hdr00_ProtBlockCtr "Protocol-Signal: Block-Counter";
CM_ SG_ 384 RFC_Hdr00_ProtocolVersion "Protocol version to be send: 0x0004 = V0.4 (Checked-In Version)";
CM_ SG_ 384 RFC_Hdr00_ProtLocationCount "number of detected VALID Locations that have been sent to the bus";
CM_ SG_ 384 RFC_Hdr00_SensorState "The sensor shall provide its operation state.
In case of multiple errors the most severe state shall be sent.";
CM_ SG_ 384 RFC_Hdr00_TimeStamp "Time Stamp";
CM_ SG_ 384 RFC_Hdr00_TimeStampStatus "Autosar StbM_TimeBaseStatusType bitfield with extension:
Bit 0: TIMEOUT
Bit 1: Reserved1
Bit 2: SYNC_TO_GATEWAY
Bit 3: GLOBAL_TIME_BASE
Bit 4: TIMELEAP_FUTURE
Bit 5: TIMELEAP_PAST
Bit 6: Reserved6
Bit 7: Extension: GENERAL_ERROR";
CM_ SG_ 384 RFC_Hdr00_LocDownSel "the detected number of locations exceeded the number of max. objects that can be transmitted";
CM_ SG_ 384 RFC_Hdr00_BliThetaVld "Validity flag RFC_Hdr00_BliTheta";
CM_ SG_ 384 RFC_Hdr00_BliThetaSIMOVld "Validity flag RFC_Hdr00_BliThetaSIMO";
CM_ SG_ 384 RFC_Hdr00_BliThetaMIMOVld "Validity flag RFC_Hdr00_BliThetaMIMO";
CM_ SG_ 384 RFC_Hdr00_BliThetaSIMOShareVld "Validity flag RFC_Hdr00_BliThetaSIMOShare";
CM_ SG_ 384 RFC_Hdr00_BliThetaMIMOShareVld "Validity flag RFC_Hdr00_BliThetaMIMOShare";
CM_ SG_ 384 RFC_Hdr00_BliPhiVld "Validity flag RFC_Hdr00_BliPhi";
CM_ SG_ 384 RFC_Hdr00_BliRCSMOVld "Validity flag RFC_Hdr00_BliRCSMO";
CM_ SG_ 384 RFC_Hdr00_BliBinOverThresholdVld "Validity flag RFC_Hdr00_BliBinsOverThreshold";
CM_ SG_ 384 RFC_Hdr00_BliNumValidReflectVld "Validity flag RFC_Hdr00_BliNumValidReflections";
CM_ SG_ 384 RFC_Hdr00_BliTheta "Blindness Average Overall Azimuth Angle Quality";
CM_ SG_ 384 RFC_Hdr00_BliThetaSIMO "Blindness Average Azimuth Angle Quality for SIMO Angles";
CM_ SG_ 384 RFC_Hdr00_BliThetaMIMO "Blindness Average Azimuth Angle Quality for MIMO Angles";
CM_ SG_ 384 RFC_Hdr00_BliThetaSIMOShare "Blindness High SIMO Azimuth Angle Quality Share";
CM_ SG_ 384 RFC_Hdr00_BliThetaMIMOShare "Blindness High MIMO Azimuth Angle Quality Share";
CM_ SG_ 384 RFC_Hdr00_BliPhi "Blindness High Elevation Angle Quality Share";
CM_ SG_ 384 RFC_Hdr00_BliRCSMO "Blindness RCS Indicator for Moving Objects";
CM_ SG_ 384 RFC_Hdr00_BliBinsOverThreshold "Blindness Number of Bins over Detection Threshold";
CM_ SG_ 384 RFC_Hdr00_BliNumValidReflections "Blindness Number of Valid Reflections";
CM_ SG_ 384 RFC_Hdr00_BliCrossCorrSO "Blindness Cross correlation indicator for stationary objects";
CM_ SG_ 384 RFC_Hdr00_BliCrossCorrSOVld "Validity flag RFC_Hdr00_BliCrossCorrSO";
CM_ SG_ 385 RFC_Hdr01_PersVerWriteCnt03 "Version and write counter";
CM_ SG_ 385 RFC_Hdr01_PersVerWriteCnt02 "Version and write counter";
CM_ SG_ 385 RFC_Hdr01_PersVerWriteCnt01 "Version and write counter";
CM_ SG_ 385 RFC_Hdr01_CRC "CRC - Autosar E2E Profile 5";
CM_ SG_ 385 RFC_Hdr01_AliveCtr "Alive counter - Autosar E2E Profile 5";
CM_ SG_ 385 RFC_Hdr01_ProtBlockCtr "Protocol-Signal: Block-Counter";
CM_ SG_ 385 RFC_Hdr01_PersVerWriteCnt00 "Version and write counter";
CM_ SG_ 385 RFC_Hdr01_PersAngIndAzi "Indicator of current mounting position, mounting angle in azi";
CM_ SG_ 385 RFC_Hdr01_PersAngIndElev "Indicator of current mounting position, mounting angle in elev.";
CM_ SG_ 385 RFC_Hdr01_PersAngIndAziMean "Indicator of current mounting position, mean az angle.";
CM_ SG_ 385 RFC_Hdr01_PersAngIndElevMean "Indicator of current mounting position, mean el angle.";
CM_ SG_ 385 RFC_Hdr01_PersAngIndAziVnce "Indicator of current mounting position, az angle variance";
CM_ SG_ 385 RFC_Hdr01_PersAngIndElevVnce "Indicator of current mounting position, el angle variance";
CM_ SG_ 385 RFC_Hdr01_PersAngIndAziElevCov "Indicator of current mounting position, az el angle covariance.";
CM_ SG_ 385 RFC_Hdr01_PersAngCurrAzi "Current mounting position, mounting angle in az.";
CM_ SG_ 385 RFC_Hdr01_PersAngCurrElev "Current mounting position, mounting angle in el.";
CM_ SG_ 385 RFC_Hdr01_PersAngCurrAziMean "Current mounting position, mean az angle.";
CM_ SG_ 385 RFC_Hdr01_PersAngCurrElevMean "Current mounting position, mean el angle.";
CM_ SG_ 385 RFC_Hdr01_PersAngCurrAziVnce "Current mounting position, az angle variance.";
CM_ SG_ 385 RFC_Hdr01_PersAngCurrElevVnce "Current mounting position, el angle variance.";
CM_ SG_ 385 RFC_Hdr01_PersAngCurrAziElevCov "Current mounting position, az el angle covariance.";
CM_ SG_ 386 RFC_Hdr02_ModPerfDMax "maximal measurable distance";
CM_ SG_ 386 RFC_Hdr02_CRC "CRC - Autosar E2E Profile 5";
CM_ SG_ 386 RFC_Hdr02_AliveCtr "Alive counter - Autosar E2E Profile 5";
CM_ SG_ 386 RFC_Hdr02_ProtBlockCtr "Protocol-Signal: Block-Counter";
CM_ SG_ 386 RFC_Hdr02_PersFiltDspMalIndAzi "Learned filter weights for indicator and current mounting in az, weight for indicator";
CM_ SG_ 386 RFC_Hdr02_PersFiltWeightIndAzi "Learned filter weights for indicator and current mounting in az, mean weight for indicator";
CM_ SG_ 386 RFC_Hdr02_PersFiltDspCurrAzi "Learned filter weights for indicator and current mounting in az, weight for current mounting";
CM_ SG_ 386 RFC_Hdr02_PersFiltDspMalIndElev "Learned filter weights for indicator and current mounting in el, weight for indicator";
CM_ SG_ 386 RFC_Hdr02_PersFiltWeightIndElev "Learned filter weights for indicator and current mounting in el, mean weight for indicator";
CM_ SG_ 386 RFC_Hdr02_PersFiltDspCurrElev "Learned filter weights for indicator and current mounting in el, weight for current mounting";
CM_ SG_ 386 RFC_Hdr02_PersMalStablePosAzi "stable position in az.";
CM_ SG_ 386 RFC_Hdr02_PersMalStablePosElev "stable position in el.";
CM_ SG_ 386 RFC_Hdr02_PersChDetPozAzi "data of change detector, az positive change";
CM_ SG_ 386 RFC_Hdr02_PersChDetNegAzi "data of change detector, az negtive change";
CM_ SG_ 386 RFC_Hdr02_PersChDetPozElev "data of change detector el positive change";
CM_ SG_ 386 RFC_Hdr02_PersChDetNegElev "data of change detector, el negtiive change";
CM_ SG_ 386 RFC_Hdr02_MntAziCur "Sensor mounting angle azimuth current";
CM_ SG_ 386 RFC_Hdr02_MntElevCur "Sensor mounting angle elevation current";
CM_ SG_ 386 RFC_Hdr02_PersOutOfSpecAzi "out of spec status (azimuth oos status)";
CM_ SG_ 386 RFC_Hdr02_PersOutOfSpecElev "out of spec status (elevation oos status)";
CM_ SG_ 387 RFC_Hdr03_CRC "CRC - Autosar E2E Profile 5";
CM_ SG_ 387 RFC_Hdr03_AliveCtr "Alive counter - Autosar E2E Profile 5";
CM_ SG_ 387 RFC_Hdr03_ProtBlockCtr "Protocol-Signal: Block-Counter";
CM_ SG_ 387 RFC_Hdr03_FoVdMaxTheta00 "FoV range for 10m^2 target at azimuth angle 00";
CM_ SG_ 387 RFC_Hdr03_FoVdMaxTheta01 "FoV range for 10m^2 target at azimuth angle 01";
CM_ SG_ 387 RFC_Hdr03_FoVdMaxTheta02 "FoV range for 10m^2 target at azimuth angle 02";
CM_ SG_ 387 RFC_Hdr03_FoVdMaxTheta03 "FoV range for 10m^2 target at azimuth angle 03";
CM_ SG_ 387 RFC_Hdr03_FoVdMaxTheta04 "FoV range for 10m^2 target at azimuth angle 04";
CM_ SG_ 387 RFC_Hdr03_FoVdMaxTheta05 "FoV range for 10m^2 target at azimuth angle 05";
CM_ SG_ 387 RFC_Hdr03_FoVdMaxTheta06 "FoV range for 10m^2 target at azimuth angle 06";
CM_ SG_ 387 RFC_Hdr03_FoVdMaxTheta07 "FoV range for 10m^2 target at azimuth angle 07";
CM_ SG_ 387 RFC_Hdr03_FoVdMaxTheta08 "FoV range for 10m^2 target at azimuth angle 08";
CM_ SG_ 387 RFC_Hdr03_FoVdMaxTheta09 "FoV range for 10m^2 target at azimuth angle 09";
CM_ SG_ 387 RFC_Hdr03_FoVdMaxTheta10 "FoV range for 10m^2 target at azimuth angle 10";
CM_ SG_ 387 RFC_Hdr03_FoVdMaxTheta11 "FoV range for 10m^2 target at azimuth angle 11";
CM_ SG_ 387 RFC_Hdr03_FoVdMaxTheta12 "FoV range for 10m^2 target at azimuth angle 12";
CM_ SG_ 387 RFC_Hdr03_FoVdMaxTheta13 "FoV range for 10m^2 target at azimuth angle 13";
CM_ SG_ 387 RFC_Hdr03_FoVdMaxTheta14 "FoV range for 10m^2 target at azimuth angle 14";
CM_ SG_ 387 RFC_Hdr03_FoVdMaxTheta15 "FoV range for 10m^2 target at azimuth angle 15";
CM_ SG_ 387 RFC_Hdr03_FoVdMaxTheta16 "FoV range for 10m^2 target at azimuth angle 16";
CM_ SG_ 387 RFC_Hdr03_FoVdMaxTheta17 "FoV range for 10m^2 target at azimuth angle 17";
CM_ SG_ 387 RFC_Hdr03_FoVdMaxTheta18 "FoV range for 10m^2 target at azimuth angle 18";
CM_ SG_ 387 RFC_Hdr03_FoVdMaxTheta19 "FoV range for 10m^2 target at azimuth angle 19";
CM_ SG_ 387 RFC_Hdr03_FoVdMaxTheta20 "FoV range for 10m^2 target at azimuth angle 20";
CM_ SG_ 387 RFC_Hdr03_FoVdMaxTheta21 "FoV range for 10m^2 target at azimuth angle 21";
CM_ SG_ 387 RFC_Hdr03_FoVdMaxTheta22 "FoV range for 10m^2 target at azimuth angle 22";
CM_ SG_ 387 RFC_Hdr03_FoVdMaxTheta23 "FoV range for 10m^2 target at azimuth angle 23";
CM_ SG_ 387 RFC_Hdr03_FoVdMaxTheta24 "FoV range for 10m^2 target at azimuth angle 24";
CM_ SG_ 387 RFC_Hdr03_FoVdMaxPhi00 "FoV Range scaling for elevation angle 00";
CM_ SG_ 387 RFC_Hdr03_FoVTheta00 "FoV azimuth angle array 00";
CM_ SG_ 387 RFC_Hdr03_FoVTheta01 "FoV azimuth angle array 01";
CM_ SG_ 387 RFC_Hdr03_FoVTheta02 "FoV azimuth angle array 02";
CM_ SG_ 387 RFC_Hdr03_FoVTheta03 "FoV azimuth angle array 03";
CM_ SG_ 387 RFC_Hdr03_FoVTheta04 "FoV azimuth angle array 04";
CM_ SG_ 387 RFC_Hdr03_FoVTheta05 "FoV azimuth angle array 05";
CM_ SG_ 387 RFC_Hdr03_FoVTheta06 "FoV azimuth angle array 06";
CM_ SG_ 387 RFC_Hdr03_FoVTheta07 "FoV azimuth angle array 07";
CM_ SG_ 387 RFC_Hdr03_FoVTheta08 "FoV azimuth angle array 08";
CM_ SG_ 387 RFC_Hdr03_FoVTheta09 "FoV azimuth angle array 09";
CM_ SG_ 387 RFC_Hdr03_FoVTheta10 "FoV azimuth angle array 10";
CM_ SG_ 387 RFC_Hdr03_FoVTheta11 "FoV azimuth angle array 11";
CM_ SG_ 387 RFC_Hdr03_FoVTheta12 "FoV azimuth angle array 12";
CM_ SG_ 387 RFC_Hdr03_FoVTheta13 "FoV azimuth angle array 13";
CM_ SG_ 387 RFC_Hdr03_FoVTheta14 "FoV azimuth angle array 14";
CM_ SG_ 387 RFC_Hdr03_FoVTheta15 "FoV azimuth angle array 15";
CM_ SG_ 387 RFC_Hdr03_FoVTheta16 "FoV azimuth angle array 16";
CM_ SG_ 387 RFC_Hdr03_FoVTheta17 "FoV azimuth angle array 17";
CM_ SG_ 387 RFC_Hdr03_FoVTheta18 "FoV azimuth angle array 18";
CM_ SG_ 387 RFC_Hdr03_FoVTheta19 "FoV azimuth angle array 19";
CM_ SG_ 387 RFC_Hdr03_FoVTheta20 "FoV azimuth angle array 20";
CM_ SG_ 387 RFC_Hdr03_FoVTheta21 "FoV azimuth angle array 21";
CM_ SG_ 387 RFC_Hdr03_FoVTheta22 "FoV azimuth angle array 22";
CM_ SG_ 387 RFC_Hdr03_FoVTheta23 "FoV azimuth angle array 23";
CM_ SG_ 387 RFC_Hdr03_FoVTheta24 "FoV azimuth angle array 24";
CM_ SG_ 387 RFC_Hdr03_FoVdMaxPhi01 "FoV Range scaling for elevation angle 01";
CM_ SG_ 387 RFC_Hdr03_FoVdMaxPhi02 "FoV Range scaling for elevation angle 02";
CM_ SG_ 387 RFC_Hdr03_FoVdMaxPhi03 "FoV Range scaling for elevation angle 03";
CM_ SG_ 387 RFC_Hdr03_FoVdMaxPhi04 "FoV Range scaling for elevation angle 04";
CM_ SG_ 387 RFC_Hdr03_FoVdMaxPhi05 "FoV Range scaling for elevation angle 05";
CM_ SG_ 387 RFC_Hdr03_FoVdMaxPhi06 "FoV Range scaling for elevation angle 06";
CM_ SG_ 388 RFC_Hdr04_CRC "CRC - Autosar E2E Profile 5";
CM_ SG_ 388 RFC_Hdr04_AliveCtr "Alive counter - Autosar E2E Profile 5";
CM_ SG_ 388 RFC_Hdr04_ProtBlockCtr "Protocol-Signal: Block-Counter";
CM_ SG_ 388 RFC_Hdr04_FoVdMaxPhi07 "FoV Range scaling for elevation angle 07";
CM_ SG_ 388 RFC_Hdr04_FoVdMaxPhi08 "FoV Range scaling for elevation angle 08";
CM_ SG_ 388 RFC_Hdr04_FoVdMaxPhi09 "FoV Range scaling for elevation angle 09";
CM_ SG_ 388 RFC_Hdr04_FoVdMaxPhi10 "FoV Range scaling for elevation angle 10";
CM_ SG_ 388 RFC_Hdr04_FoVPhi00 "FoV elevation angle array 00";
CM_ SG_ 388 RFC_Hdr04_FoVPhi01 "FoV elevation angle array 01";
CM_ SG_ 388 RFC_Hdr04_FoVPhi02 "FoV elevation angle array 02";
CM_ SG_ 388 RFC_Hdr04_FoVPhi03 "FoV elevation angle array 03";
CM_ SG_ 388 RFC_Hdr04_FoVPhi04 "FoV elevation angle array 04";
CM_ SG_ 388 RFC_Hdr04_FoVPhi05 "FoV elevation angle array 05";
CM_ SG_ 388 RFC_Hdr04_FoVPhi06 "FoV elevation angle array 06";
CM_ SG_ 388 RFC_Hdr04_FoVPhi07 "FoV elevation angle array 07";
CM_ SG_ 388 RFC_Hdr04_FoVPhi08 "FoV elevation angle array 08";
CM_ SG_ 388 RFC_Hdr04_FoVPhi09 "FoV elevation angle array 09";
CM_ SG_ 388 RFC_Hdr04_FoVPhi10 "FoV elevation angle array 10";
CM_ SG_ 388 RFC_Hdr04_MntPosX "Sensor mounting X position in vehile FOR";
CM_ SG_ 388 RFC_Hdr04_MntPosY "Sensor mounting Y position in vehile FOR";
CM_ SG_ 388 RFC_Hdr04_MntPosZ "Sensor mounting Z position in vehile FOR";
CM_ SG_ 388 RFC_Hdr04_MntAziNom "Sensor mounting angle azimuth norminal";
CM_ SG_ 388 RFC_Hdr04_MntElevNom "Sensor mounting angle elevation norminal";
CM_ SG_ 388 RFC_Hdr04_InitCov "Initial CoVariance Factor";
CM_ SG_ 388 RFC_Hdr04_TspMeasID "TimeStamp Pair measurement ID";
CM_ SG_ 388 RFC_Hdr04_TspSensID "TimeStamp Pair sensor ID";
CM_ SG_ 388 RFC_Hdr04_TspLastMeas "TimeStamp Pair last measurement time stamp";
CM_ SG_ 388 RFC_Hdr04_TspLastRec "TimeStamp Pair last reception time stamp";
CM_ SG_ 388 RFC_Hdr04_TspPredMeas "TimeStamp Pair predicted measurement time stamp";
CM_ SG_ 388 RFC_Hdr04_TspPredRec "TimeStamp Pair predected reception time stamp";
CM_ SG_ 400 RFC_Loc000_CRC "CRC - Autosar E2E Profile 5, DataID = TBD";
CM_ SG_ 400 RFC_Loc000_AliveCtr "Alive counter - Autosar E2E Profile 5";
CM_ SG_ 400 RFC_Loc000_ProtBlockCtr "Protocol-Signal: Block-Counter";
CM_ SG_ 400 RFC_Loc000_Dr "Location radial distance";
CM_ SG_ 400 RFC_Loc000_Vr "Location radial relative velocity";
CM_ SG_ 400 RFC_Loc000_Theta "Location azimuth angle. \"Not a number\" TBD";
CM_ SG_ 400 RFC_Loc000_Phi "Location elevation angle. \"Not a number\" TBD";
CM_ SG_ 400 RFC_Loc000_DrVnce "Variance of Location radial distance";
CM_ SG_ 400 RFC_Loc000_VrVnce "Variance of Location radial relative velocity";
CM_ SG_ 400 RFC_Loc000_ThetaVnce "Variance of Location azimuth angle";
CM_ SG_ 400 RFC_Loc000_PhiVnce "Variance of Location elevation angle";
CM_ SG_ 400 RFC_Loc000_DrVrCoVnce "Covariance of Dr and Vr";
CM_ SG_ 400 RFC_Loc000_RCS "Radar Cross Section (RCS) estimation";
CM_ SG_ 400 RFC_Loc000_RSSI "Received Signal Strength Indication (RSSI)";
CM_ SG_ 400 RFC_Loc000_DrVrQuality "Quality of radial distance and velocity resolution processing. Physical range [0..1]";
CM_ SG_ 400 RFC_Loc000_ThetaQuality "Probability for correct signal model (azimuth angle). Physical range [0..1]";
CM_ SG_ 400 RFC_Loc000_PhiQuality "Probability for correct signal model (elevation angle). Physical range [0..1]";
CM_ SG_ 400 RFC_Loc001_Dr "Location radial distance";
CM_ SG_ 400 RFC_Loc001_Vr "Location radial relative velocity";
CM_ SG_ 400 RFC_Loc001_Theta "Location azimuth angle. \"Not a number\" TBD";
CM_ SG_ 400 RFC_Loc001_Phi "Location elevation angle. \"Not a number\" TBD";
CM_ SG_ 400 RFC_Loc001_DrVnce "Variance of Location radial distance";
CM_ SG_ 400 RFC_Loc001_VrVnce "Variance of Location radial relative velocity";
CM_ SG_ 400 RFC_Loc001_ThetaVnce "Variance of Location azimuth angle";
CM_ SG_ 400 RFC_Loc001_PhiVnce "Variance of Location elevation angle";
CM_ SG_ 400 RFC_Loc001_DrVrCoVnce "Covariance of Dr and Vr";
CM_ SG_ 400 RFC_Loc001_RCS "Radar Cross Section (RCS) estimation";
CM_ SG_ 400 RFC_Loc001_RSSI "Received Signal Strength Indication (RSSI)";
CM_ SG_ 400 RFC_Loc001_DrVrQuality "Quality of radial distance and velocity resolution processing. Physical range [0..1]";
CM_ SG_ 400 RFC_Loc001_ThetaQuality "Probability for correct signal model (azimuth angle). Physical range [0..1]";
CM_ SG_ 400 RFC_Loc001_PhiQuality "Probability for correct signal model (elevation angle). Physical range [0..1]";
CM_ SG_ 401 RFC_Loc002_CRC "CRC - Autosar E2E Profile 5, DataID = TBD";
CM_ SG_ 401 RFC_Loc002_AliveCtr "Alive counter - Autosar E2E Profile 5";
CM_ SG_ 401 RFC_Loc002_ProtBlockCtr "Protocol-Signal: Block-Counter";
CM_ SG_ 401 RFC_Loc002_Dr "Location radial distance";
CM_ SG_ 401 RFC_Loc002_Vr "Location radial relative velocity";
CM_ SG_ 401 RFC_Loc002_Theta "Location azimuth angle. \"Not a number\" TBD";
CM_ SG_ 401 RFC_Loc002_Phi "Location elevation angle. \"Not a number\" TBD";
CM_ SG_ 401 RFC_Loc002_DrVnce "Variance of Location radial distance";
CM_ SG_ 401 RFC_Loc002_VrVnce "Variance of Location radial relative velocity";
CM_ SG_ 401 RFC_Loc002_ThetaVnce "Variance of Location azimuth angle";
CM_ SG_ 401 RFC_Loc002_PhiVnce "Variance of Location elevation angle";
CM_ SG_ 401 RFC_Loc002_DrVrCoVnce "Covariance of Dr and Vr";
CM_ SG_ 401 RFC_Loc002_RCS "Radar Cross Section (RCS) estimation";
CM_ SG_ 401 RFC_Loc002_RSSI "Received Signal Strength Indication (RSSI)";
CM_ SG_ 401 RFC_Loc002_DrVrQuality "Quality of radial distance and velocity resolution processing. Physical range [0..1]";
CM_ SG_ 401 RFC_Loc002_ThetaQuality "Probability for correct signal model (azimuth angle). Physical range [0..1]";
CM_ SG_ 401 RFC_Loc002_PhiQuality "Probability for correct signal model (elevation angle). Physical range [0..1]";
CM_ SG_ 401 RFC_Loc003_Dr "Location radial distance";
CM_ SG_ 401 RFC_Loc003_Vr "Location radial relative velocity";
CM_ SG_ 401 RFC_Loc003_Theta "Location azimuth angle. \"Not a number\" TBD";
CM_ SG_ 401 RFC_Loc003_Phi "Location elevation angle. \"Not a number\" TBD";
CM_ SG_ 401 RFC_Loc003_DrVnce "Variance of Location radial distance";
CM_ SG_ 401 RFC_Loc003_VrVnce "Variance of Location radial relative velocity";
CM_ SG_ 401 RFC_Loc003_ThetaVnce "Variance of Location azimuth angle";
CM_ SG_ 401 RFC_Loc003_PhiVnce "Variance of Location elevation angle";
CM_ SG_ 401 RFC_Loc003_DrVrCoVnce "Covariance of Dr and Vr";
CM_ SG_ 401 RFC_Loc003_RCS "Radar Cross Section (RCS) estimation";
CM_ SG_ 401 RFC_Loc003_RSSI "Received Signal Strength Indication (RSSI)";
CM_ SG_ 401 RFC_Loc003_DrVrQuality "Quality of radial distance and velocity resolution processing. Physical range [0..1]";
CM_ SG_ 401 RFC_Loc003_ThetaQuality "Probability for correct signal model (azimuth angle). Physical range [0..1]";
CM_ SG_ 401 RFC_Loc003_PhiQuality "Probability for correct signal model (elevation angle). Physical range [0..1]";
CM_ SG_ 402 RFC_Loc004_CRC "CRC - Autosar E2E Profile 5, DataID = TBD";
CM_ SG_ 402 RFC_Loc004_AliveCtr "Alive counter - Autosar E2E Profile 5";
CM_ SG_ 402 RFC_Loc004_ProtBlockCtr "Protocol-Signal: Block-Counter";
CM_ SG_ 402 RFC_Loc004_Dr "Location radial distance";
CM_ SG_ 402 RFC_Loc004_Vr "Location radial relative velocity";
CM_ SG_ 402 RFC_Loc004_Theta "Location azimuth angle. \"Not a number\" TBD";
CM_ SG_ 402 RFC_Loc004_Phi "Location elevation angle. \"Not a number\" TBD";
CM_ SG_ 402 RFC_Loc004_DrVnce "Variance of Location radial distance";
CM_ SG_ 402 RFC_Loc004_VrVnce "Variance of Location radial relative velocity";
CM_ SG_ 402 RFC_Loc004_ThetaVnce "Variance of Location azimuth angle";
CM_ SG_ 402 RFC_Loc004_PhiVnce "Variance of Location elevation angle";
CM_ SG_ 402 RFC_Loc004_DrVrCoVnce "Covariance of Dr and Vr";
CM_ SG_ 402 RFC_Loc004_RCS "Radar Cross Section (RCS) estimation";
CM_ SG_ 402 RFC_Loc004_RSSI "Received Signal Strength Indication (RSSI)";
CM_ SG_ 402 RFC_Loc004_DrVrQuality "Quality of radial distance and velocity resolution processing. Physical range [0..1]";
CM_ SG_ 402 RFC_Loc004_ThetaQuality "Probability for correct signal model (azimuth angle). Physical range [0..1]";
CM_ SG_ 402 RFC_Loc004_PhiQuality "Probability for correct signal model (elevation angle). Physical range [0..1]";
CM_ SG_ 402 RFC_Loc005_Dr "Location radial distance";
CM_ SG_ 402 RFC_Loc005_Vr "Location radial relative velocity";
CM_ SG_ 402 RFC_Loc005_Theta "Location azimuth angle. \"Not a number\" TBD";
CM_ SG_ 402 RFC_Loc005_Phi "Location elevation angle. \"Not a number\" TBD";
CM_ SG_ 402 RFC_Loc005_DrVnce "Variance of Location radial distance";
CM_ SG_ 402 RFC_Loc005_VrVnce "Variance of Location radial relative velocity";
CM_ SG_ 402 RFC_Loc005_ThetaVnce "Variance of Location azimuth angle";
CM_ SG_ 402 RFC_Loc005_PhiVnce "Variance of Location elevation angle";
CM_ SG_ 402 RFC_Loc005_DrVrCoVnce "Covariance of Dr and Vr";
CM_ SG_ 402 RFC_Loc005_RCS "Radar Cross Section (RCS) estimation";
CM_ SG_ 402 RFC_Loc005_RSSI "Received Signal Strength Indication (RSSI)";
CM_ SG_ 402 RFC_Loc005_DrVrQuality "Quality of radial distance and velocity resolution processing. Physical range [0..1]";
CM_ SG_ 402 RFC_Loc005_ThetaQuality "Probability for correct signal model (azimuth angle). Physical range [0..1]";
CM_ SG_ 402 RFC_Loc005_PhiQuality "Probability for correct signal model (elevation angle). Physical range [0..1]";
CM_ SG_ 403 RFC_Loc006_CRC "CRC - Autosar E2E Profile 5, DataID = TBD";
CM_ SG_ 403 RFC_Loc006_AliveCtr "Alive counter - Autosar E2E Profile 5";
CM_ SG_ 403 RFC_Loc006_ProtBlockCtr "Protocol-Signal: Block-Counter";
CM_ SG_ 403 RFC_Loc006_Dr "Location radial distance";
CM_ SG_ 403 RFC_Loc006_Vr "Location radial relative velocity";
CM_ SG_ 403 RFC_Loc006_Theta "Location azimuth angle. \"Not a number\" TBD";
CM_ SG_ 403 RFC_Loc006_Phi "Location elevation angle. \"Not a number\" TBD";
CM_ SG_ 403 RFC_Loc006_DrVnce "Variance of Location radial distance";
CM_ SG_ 403 RFC_Loc006_VrVnce "Variance of Location radial relative velocity";
CM_ SG_ 403 RFC_Loc006_ThetaVnce "Variance of Location azimuth angle";
CM_ SG_ 403 RFC_Loc006_PhiVnce "Variance of Location elevation angle";
CM_ SG_ 403 RFC_Loc006_DrVrCoVnce "Covariance of Dr and Vr";
CM_ SG_ 403 RFC_Loc006_RCS "Radar Cross Section (RCS) estimation";
CM_ SG_ 403 RFC_Loc006_RSSI "Received Signal Strength Indication (RSSI)";
CM_ SG_ 403 RFC_Loc006_DrVrQuality "Quality of radial distance and velocity resolution processing. Physical range [0..1]";
CM_ SG_ 403 RFC_Loc006_ThetaQuality "Probability for correct signal model (azimuth angle). Physical range [0..1]";
CM_ SG_ 403 RFC_Loc006_PhiQuality "Probability for correct signal model (elevation angle). Physical range [0..1]";
CM_ SG_ 403 RFC_Loc007_Dr "Location radial distance";
CM_ SG_ 403 RFC_Loc007_Vr "Location radial relative velocity";
CM_ SG_ 403 RFC_Loc007_Theta "Location azimuth angle. \"Not a number\" TBD";
CM_ SG_ 403 RFC_Loc007_Phi "Location elevation angle. \"Not a number\" TBD";
CM_ SG_ 403 RFC_Loc007_DrVnce "Variance of Location radial distance";
CM_ SG_ 403 RFC_Loc007_VrVnce "Variance of Location radial relative velocity";
CM_ SG_ 403 RFC_Loc007_ThetaVnce "Variance of Location azimuth angle";
CM_ SG_ 403 RFC_Loc007_PhiVnce "Variance of Location elevation angle";
CM_ SG_ 403 RFC_Loc007_DrVrCoVnce "Covariance of Dr and Vr";
CM_ SG_ 403 RFC_Loc007_RCS "Radar Cross Section (RCS) estimation";
CM_ SG_ 403 RFC_Loc007_RSSI "Received Signal Strength Indication (RSSI)";
CM_ SG_ 403 RFC_Loc007_DrVrQuality "Quality of radial distance and velocity resolution processing. Physical range [0..1]";
CM_ SG_ 403 RFC_Loc007_ThetaQuality "Probability for correct signal model (azimuth angle). Physical range [0..1]";
CM_ SG_ 403 RFC_Loc007_PhiQuality "Probability for correct signal model (elevation angle). Physical range [0..1]";
CM_ SG_ 404 RFC_Loc008_CRC "CRC - Autosar E2E Profile 5, DataID = TBD";
CM_ SG_ 404 RFC_Loc008_AliveCtr "Alive counter - Autosar E2E Profile 5";
CM_ SG_ 404 RFC_Loc008_ProtBlockCtr "Protocol-Signal: Block-Counter";
CM_ SG_ 404 RFC_Loc008_Dr "Location radial distance";
CM_ SG_ 404 RFC_Loc008_Vr "Location radial relative velocity";
CM_ SG_ 404 RFC_Loc008_Theta "Location azimuth angle. \"Not a number\" TBD";
CM_ SG_ 404 RFC_Loc008_Phi "Location elevation angle. \"Not a number\" TBD";
CM_ SG_ 404 RFC_Loc008_DrVnce "Variance of Location radial distance";
CM_ SG_ 404 RFC_Loc008_VrVnce "Variance of Location radial relative velocity";
CM_ SG_ 404 RFC_Loc008_ThetaVnce "Variance of Location azimuth angle";
CM_ SG_ 404 RFC_Loc008_PhiVnce "Variance of Location elevation angle";
CM_ SG_ 404 RFC_Loc008_DrVrCoVnce "Covariance of Dr and Vr";
CM_ SG_ 404 RFC_Loc008_RCS "Radar Cross Section (RCS) estimation";
CM_ SG_ 404 RFC_Loc008_RSSI "Received Signal Strength Indication (RSSI)";
CM_ SG_ 404 RFC_Loc008_DrVrQuality "Quality of radial distance and velocity resolution processing. Physical range [0..1]";
CM_ SG_ 404 RFC_Loc008_ThetaQuality "Probability for correct signal model (azimuth angle). Physical range [0..1]";
CM_ SG_ 404 RFC_Loc008_PhiQuality "Probability for correct signal model (elevation angle). Physical range [0..1]";
CM_ SG_ 404 RFC_Loc009_Dr "Location radial distance";
CM_ SG_ 404 RFC_Loc009_Vr "Location radial relative velocity";
CM_ SG_ 404 RFC_Loc009_Theta "Location azimuth angle. \"Not a number\" TBD";
CM_ SG_ 404 RFC_Loc009_Phi "Location elevation angle. \"Not a number\" TBD";
CM_ SG_ 404 RFC_Loc009_DrVnce "Variance of Location radial distance";
CM_ SG_ 404 RFC_Loc009_VrVnce "Variance of Location radial relative velocity";
CM_ SG_ 404 RFC_Loc009_ThetaVnce "Variance of Location azimuth angle";
CM_ SG_ 404 RFC_Loc009_PhiVnce "Variance of Location elevation angle";
CM_ SG_ 404 RFC_Loc009_DrVrCoVnce "Covariance of Dr and Vr";
CM_ SG_ 404 RFC_Loc009_RCS "Radar Cross Section (RCS) estimation";
CM_ SG_ 404 RFC_Loc009_RSSI "Received Signal Strength Indication (RSSI)";
CM_ SG_ 404 RFC_Loc009_DrVrQuality "Quality of radial distance and velocity resolution processing. Physical range [0..1]";
CM_ SG_ 404 RFC_Loc009_ThetaQuality "Probability for correct signal model (azimuth angle). Physical range [0..1]";
CM_ SG_ 404 RFC_Loc009_PhiQuality "Probability for correct signal model (elevation angle). Physical range [0..1]";
CM_ SG_ 405 RFC_Loc010_CRC "CRC - Autosar E2E Profile 5, DataID = TBD";
CM_ SG_ 405 RFC_Loc010_AliveCtr "Alive counter - Autosar E2E Profile 5";
CM_ SG_ 405 RFC_Loc010_ProtBlockCtr "Protocol-Signal: Block-Counter";
CM_ SG_ 405 RFC_Loc010_Dr "Location radial distance";
CM_ SG_ 405 RFC_Loc010_Vr "Location radial relative velocity";
CM_ SG_ 405 RFC_Loc010_Theta "Location azimuth angle. \"Not a number\" TBD";
CM_ SG_ 405 RFC_Loc010_Phi "Location elevation angle. \"Not a number\" TBD";
CM_ SG_ 405 RFC_Loc010_DrVnce "Variance of Location radial distance";
CM_ SG_ 405 RFC_Loc010_VrVnce "Variance of Location radial relative velocity";
CM_ SG_ 405 RFC_Loc010_ThetaVnce "Variance of Location azimuth angle";
CM_ SG_ 405 RFC_Loc010_PhiVnce "Variance of Location elevation angle";
CM_ SG_ 405 RFC_Loc010_DrVrCoVnce "Covariance of Dr and Vr";
CM_ SG_ 405 RFC_Loc010_RCS "Radar Cross Section (RCS) estimation";
CM_ SG_ 405 RFC_Loc010_RSSI "Received Signal Strength Indication (RSSI)";
CM_ SG_ 405 RFC_Loc010_DrVrQuality "Quality of radial distance and velocity resolution processing. Physical range [0..1]";
CM_ SG_ 405 RFC_Loc010_ThetaQuality "Probability for correct signal model (azimuth angle). Physical range [0..1]";
CM_ SG_ 405 RFC_Loc010_PhiQuality "Probability for correct signal model (elevation angle). Physical range [0..1]";
CM_ SG_ 405 RFC_Loc011_Dr "Location radial distance";
CM_ SG_ 405 RFC_Loc011_Vr "Location radial relative velocity";
CM_ SG_ 405 RFC_Loc011_Theta "Location azimuth angle. \"Not a number\" TBD";
CM_ SG_ 405 RFC_Loc011_Phi "Location elevation angle. \"Not a number\" TBD";
CM_ SG_ 405 RFC_Loc011_DrVnce "Variance of Location radial distance";
CM_ SG_ 405 RFC_Loc011_VrVnce "Variance of Location radial relative velocity";
CM_ SG_ 405 RFC_Loc011_ThetaVnce "Variance of Location azimuth angle";
CM_ SG_ 405 RFC_Loc011_PhiVnce "Variance of Location elevation angle";
CM_ SG_ 405 RFC_Loc011_DrVrCoVnce "Covariance of Dr and Vr";
CM_ SG_ 405 RFC_Loc011_RCS "Radar Cross Section (RCS) estimation";
CM_ SG_ 405 RFC_Loc011_RSSI "Received Signal Strength Indication (RSSI)";
CM_ SG_ 405 RFC_Loc011_DrVrQuality "Quality of radial distance and velocity resolution processing. Physical range [0..1]";
CM_ SG_ 405 RFC_Loc011_ThetaQuality "Probability for correct signal model (azimuth angle). Physical range [0..1]";
CM_ SG_ 405 RFC_Loc011_PhiQuality "Probability for correct signal model (elevation angle). Physical range [0..1]";
CM_ SG_ 406 RFC_Loc012_CRC "CRC - Autosar E2E Profile 5, DataID = TBD";
CM_ SG_ 406 RFC_Loc012_AliveCtr "Alive counter - Autosar E2E Profile 5";
CM_ SG_ 406 RFC_Loc012_ProtBlockCtr "Protocol-Signal: Block-Counter";
CM_ SG_ 406 RFC_Loc012_Dr "Location radial distance";
CM_ SG_ 406 RFC_Loc012_Vr "Location radial relative velocity";
CM_ SG_ 406 RFC_Loc012_Theta "Location azimuth angle. \"Not a number\" TBD";
CM_ SG_ 406 RFC_Loc012_Phi "Location elevation angle. \"Not a number\" TBD";
CM_ SG_ 406 RFC_Loc012_DrVnce "Variance of Location radial distance";
CM_ SG_ 406 RFC_Loc012_VrVnce "Variance of Location radial relative velocity";
CM_ SG_ 406 RFC_Loc012_ThetaVnce "Variance of Location azimuth angle";
CM_ SG_ 406 RFC_Loc012_PhiVnce "Variance of Location elevation angle";
CM_ SG_ 406 RFC_Loc012_DrVrCoVnce "Covariance of Dr and Vr";
CM_ SG_ 406 RFC_Loc012_RCS "Radar Cross Section (RCS) estimation";
CM_ SG_ 406 RFC_Loc012_RSSI "Received Signal Strength Indication (RSSI)";
CM_ SG_ 406 RFC_Loc012_DrVrQuality "Quality of radial distance and velocity resolution processing. Physical range [0..1]";
CM_ SG_ 406 RFC_Loc012_ThetaQuality "Probability for correct signal model (azimuth angle). Physical range [0..1]";
CM_ SG_ 406 RFC_Loc012_PhiQuality "Probability for correct signal model (elevation angle). Physical range [0..1]";
CM_ SG_ 406 RFC_Loc013_Dr "Location radial distance";
CM_ SG_ 406 RFC_Loc013_Vr "Location radial relative velocity";
CM_ SG_ 406 RFC_Loc013_Theta "Location azimuth angle. \"Not a number\" TBD";
CM_ SG_ 406 RFC_Loc013_Phi "Location elevation angle. \"Not a number\" TBD";
CM_ SG_ 406 RFC_Loc013_DrVnce "Variance of Location radial distance";
CM_ SG_ 406 RFC_Loc013_VrVnce "Variance of Location radial relative velocity";
CM_ SG_ 406 RFC_Loc013_ThetaVnce "Variance of Location azimuth angle";
CM_ SG_ 406 RFC_Loc013_PhiVnce "Variance of Location elevation angle";
CM_ SG_ 406 RFC_Loc013_DrVrCoVnce "Covariance of Dr and Vr";
CM_ SG_ 406 RFC_Loc013_RCS "Radar Cross Section (RCS) estimation";
CM_ SG_ 406 RFC_Loc013_RSSI "Received Signal Strength Indication (RSSI)";
CM_ SG_ 406 RFC_Loc013_DrVrQuality "Quality of radial distance and velocity resolution processing. Physical range [0..1]";
CM_ SG_ 406 RFC_Loc013_ThetaQuality "Probability for correct signal model (azimuth angle). Physical range [0..1]";
CM_ SG_ 406 RFC_Loc013_PhiQuality "Probability for correct signal model (elevation angle). Physical range [0..1]";
CM_ SG_ 407 RFC_Loc014_CRC "CRC - Autosar E2E Profile 5, DataID = TBD";
CM_ SG_ 407 RFC_Loc014_AliveCtr "Alive counter - Autosar E2E Profile 5";
CM_ SG_ 407 RFC_Loc014_ProtBlockCtr "Protocol-Signal: Block-Counter";
CM_ SG_ 407 RFC_Loc014_Dr "Location radial distance";
CM_ SG_ 407 RFC_Loc014_Vr "Location radial relative velocity";
CM_ SG_ 407 RFC_Loc014_Theta "Location azimuth angle. \"Not a number\" TBD";
CM_ SG_ 407 RFC_Loc014_Phi "Location elevation angle. \"Not a number\" TBD";
CM_ SG_ 407 RFC_Loc014_DrVnce "Variance of Location radial distance";
CM_ SG_ 407 RFC_Loc014_VrVnce "Variance of Location radial relative velocity";
CM_ SG_ 407 RFC_Loc014_ThetaVnce "Variance of Location azimuth angle";
CM_ SG_ 407 RFC_Loc014_PhiVnce "Variance of Location elevation angle";
CM_ SG_ 407 RFC_Loc014_DrVrCoVnce "Covariance of Dr and Vr";
CM_ SG_ 407 RFC_Loc014_RCS "Radar Cross Section (RCS) estimation";
CM_ SG_ 407 RFC_Loc014_RSSI "Received Signal Strength Indication (RSSI)";
CM_ SG_ 407 RFC_Loc014_DrVrQuality "Quality of radial distance and velocity resolution processing. Physical range [0..1]";
CM_ SG_ 407 RFC_Loc014_ThetaQuality "Probability for correct signal model (azimuth angle). Physical range [0..1]";
CM_ SG_ 407 RFC_Loc014_PhiQuality "Probability for correct signal model (elevation angle). Physical range [0..1]";
CM_ SG_ 407 RFC_Loc015_Dr "Location radial distance";
CM_ SG_ 407 RFC_Loc015_Vr "Location radial relative velocity";
CM_ SG_ 407 RFC_Loc015_Theta "Location azimuth angle. \"Not a number\" TBD";
CM_ SG_ 407 RFC_Loc015_Phi "Location elevation angle. \"Not a number\" TBD";
CM_ SG_ 407 RFC_Loc015_DrVnce "Variance of Location radial distance";
CM_ SG_ 407 RFC_Loc015_VrVnce "Variance of Location radial relative velocity";
CM_ SG_ 407 RFC_Loc015_ThetaVnce "Variance of Location azimuth angle";
CM_ SG_ 407 RFC_Loc015_PhiVnce "Variance of Location elevation angle";
CM_ SG_ 407 RFC_Loc015_DrVrCoVnce "Covariance of Dr and Vr";
CM_ SG_ 407 RFC_Loc015_RCS "Radar Cross Section (RCS) estimation";
CM_ SG_ 407 RFC_Loc015_RSSI "Received Signal Strength Indication (RSSI)";
CM_ SG_ 407 RFC_Loc015_DrVrQuality "Quality of radial distance and velocity resolution processing. Physical range [0..1]";
CM_ SG_ 407 RFC_Loc015_ThetaQuality "Probability for correct signal model (azimuth angle). Physical range [0..1]";
CM_ SG_ 407 RFC_Loc015_PhiQuality "Probability for correct signal model (elevation angle). Physical range [0..1]";
CM_ SG_ 408 RFC_Loc016_CRC "CRC - Autosar E2E Profile 5, DataID = TBD";
CM_ SG_ 408 RFC_Loc016_AliveCtr "Alive counter - Autosar E2E Profile 5";
CM_ SG_ 408 RFC_Loc016_ProtBlockCtr "Protocol-Signal: Block-Counter";
CM_ SG_ 408 RFC_Loc016_Dr "Location radial distance";
CM_ SG_ 408 RFC_Loc016_Vr "Location radial relative velocity";
CM_ SG_ 408 RFC_Loc016_Theta "Location azimuth angle. \"Not a number\" TBD";
CM_ SG_ 408 RFC_Loc016_Phi "Location elevation angle. \"Not a number\" TBD";
CM_ SG_ 408 RFC_Loc016_DrVnce "Variance of Location radial distance";
CM_ SG_ 408 RFC_Loc016_VrVnce "Variance of Location radial relative velocity";
CM_ SG_ 408 RFC_Loc016_ThetaVnce "Variance of Location azimuth angle";
CM_ SG_ 408 RFC_Loc016_PhiVnce "Variance of Location elevation angle";
CM_ SG_ 408 RFC_Loc016_DrVrCoVnce "Covariance of Dr and Vr";
CM_ SG_ 408 RFC_Loc016_RCS "Radar Cross Section (RCS) estimation";
CM_ SG_ 408 RFC_Loc016_RSSI "Received Signal Strength Indication (RSSI)";
CM_ SG_ 408 RFC_Loc016_DrVrQuality "Quality of radial distance and velocity resolution processing. Physical range [0..1]";
CM_ SG_ 408 RFC_Loc016_ThetaQuality "Probability for correct signal model (azimuth angle). Physical range [0..1]";
CM_ SG_ 408 RFC_Loc016_PhiQuality "Probability for correct signal model (elevation angle). Physical range [0..1]";
CM_ SG_ 408 RFC_Loc017_Dr "Location radial distance";
CM_ SG_ 408 RFC_Loc017_Vr "Location radial relative velocity";
CM_ SG_ 408 RFC_Loc017_Theta "Location azimuth angle. \"Not a number\" TBD";
CM_ SG_ 408 RFC_Loc017_Phi "Location elevation angle. \"Not a number\" TBD";
CM_ SG_ 408 RFC_Loc017_DrVnce "Variance of Location radial distance";
CM_ SG_ 408 RFC_Loc017_VrVnce "Variance of Location radial relative velocity";
CM_ SG_ 408 RFC_Loc017_ThetaVnce "Variance of Location azimuth angle";
CM_ SG_ 408 RFC_Loc017_PhiVnce "Variance of Location elevation angle";
CM_ SG_ 408 RFC_Loc017_DrVrCoVnce "Covariance of Dr and Vr";
CM_ SG_ 408 RFC_Loc017_RCS "Radar Cross Section (RCS) estimation";
CM_ SG_ 408 RFC_Loc017_RSSI "Received Signal Strength Indication (RSSI)";
CM_ SG_ 408 RFC_Loc017_DrVrQuality "Quality of radial distance and velocity resolution processing. Physical range [0..1]";
CM_ SG_ 408 RFC_Loc017_ThetaQuality "Probability for correct signal model (azimuth angle). Physical range [0..1]";
CM_ SG_ 408 RFC_Loc017_PhiQuality "Probability for correct signal model (elevation angle). Physical range [0..1]";
CM_ SG_ 409 RFC_Loc018_CRC "CRC - Autosar E2E Profile 5, DataID = TBD";
CM_ SG_ 409 RFC_Loc018_AliveCtr "Alive counter - Autosar E2E Profile 5";
CM_ SG_ 409 RFC_Loc018_ProtBlockCtr "Protocol-Signal: Block-Counter";
CM_ SG_ 409 RFC_Loc018_Dr "Location radial distance";
CM_ SG_ 409 RFC_Loc018_Vr "Location radial relative velocity";
CM_ SG_ 409 RFC_Loc018_Theta "Location azimuth angle. \"Not a number\" TBD";
CM_ SG_ 409 RFC_Loc018_Phi "Location elevation angle. \"Not a number\" TBD";
CM_ SG_ 409 RFC_Loc018_DrVnce "Variance of Location radial distance";
CM_ SG_ 409 RFC_Loc018_VrVnce "Variance of Location radial relative velocity";
CM_ SG_ 409 RFC_Loc018_ThetaVnce "Variance of Location azimuth angle";
CM_ SG_ 409 RFC_Loc018_PhiVnce "Variance of Location elevation angle";
CM_ SG_ 409 RFC_Loc018_DrVrCoVnce "Covariance of Dr and Vr";
CM_ SG_ 409 RFC_Loc018_RCS "Radar Cross Section (RCS) estimation";
CM_ SG_ 409 RFC_Loc018_RSSI "Received Signal Strength Indication (RSSI)";
CM_ SG_ 409 RFC_Loc018_DrVrQuality "Quality of radial distance and velocity resolution processing. Physical range [0..1]";
CM_ SG_ 409 RFC_Loc018_ThetaQuality "Probability for correct signal model (azimuth angle). Physical range [0..1]";
CM_ SG_ 409 RFC_Loc018_PhiQuality "Probability for correct signal model (elevation angle). Physical range [0..1]";
CM_ SG_ 409 RFC_Loc019_Dr "Location radial distance";
CM_ SG_ 409 RFC_Loc019_Vr "Location radial relative velocity";
CM_ SG_ 409 RFC_Loc019_Theta "Location azimuth angle. \"Not a number\" TBD";
CM_ SG_ 409 RFC_Loc019_Phi "Location elevation angle. \"Not a number\" TBD";
CM_ SG_ 409 RFC_Loc019_DrVnce "Variance of Location radial distance";
CM_ SG_ 409 RFC_Loc019_VrVnce "Variance of Location radial relative velocity";
CM_ SG_ 409 RFC_Loc019_ThetaVnce "Variance of Location azimuth angle";
CM_ SG_ 409 RFC_Loc019_PhiVnce "Variance of Location elevation angle";
CM_ SG_ 409 RFC_Loc019_DrVrCoVnce "Covariance of Dr and Vr";
CM_ SG_ 409 RFC_Loc019_RCS "Radar Cross Section (RCS) estimation";
CM_ SG_ 409 RFC_Loc019_RSSI "Received Signal Strength Indication (RSSI)";
CM_ SG_ 409 RFC_Loc019_DrVrQuality "Quality of radial distance and velocity resolution processing. Physical range [0..1]";
CM_ SG_ 409 RFC_Loc019_ThetaQuality "Probability for correct signal model (azimuth angle). Physical range [0..1]";
CM_ SG_ 409 RFC_Loc019_PhiQuality "Probability for correct signal model (elevation angle). Physical range [0..1]";
BA_DEF_ BO_  "GenMsgSendType" ENUM  "cyclic","NoMsgSendType","IfActive","Event","CA","CE";
BA_DEF_ BO_  "GenMsgCycleTime" INT 0 0;
BA_DEF_ SG_  "GenSigSendType" ENUM  "cyclic","OnChange","OnWrite","IfActive","OnChangeWithRepetition","OnWriteWithRepetition","IfActiveWithRepetition","CA","CE","Event";
BA_DEF_ SG_  "GenSigStartValue" INT 0 0;
BA_DEF_ BO_  "CANFD_BRS" ENUM  "0","1";
BA_DEF_ BO_  "VFrameFormat" ENUM  "StandardCAN","ExtendedCAN","reserved","reserved","reserved","reserved","reserved","reserved","reserved","reserved","reserved","reserved","reserved","reserved","StandardCAN_FD","ExtendedCAN_FD";
BA_DEF_ BO_  "GenMsgILSupport" ENUM  "No","Yes";
BA_DEF_ SG_  "sigDespEng" STRING ;
BA_DEF_ SG_  "sigSecLevel" STRING ;
BA_DEF_ SG_  "sigConfig" STRING ;
BA_DEF_ SG_  "sigExplanation" STRING ;
BA_DEF_DEF_  "GenMsgSendType" "cyclic";
BA_DEF_DEF_  "GenMsgCycleTime" 0;
BA_DEF_DEF_  "GenSigSendType" "cyclic";
BA_DEF_DEF_  "GenSigStartValue" 0;
BA_DEF_DEF_  "CANFD_BRS" "1";
BA_DEF_DEF_  "VFrameFormat" "";
BA_DEF_DEF_  "GenMsgILSupport" "Yes";
BA_DEF_DEF_  "sigDespEng" "";
BA_DEF_DEF_  "sigSecLevel" "";
BA_DEF_DEF_  "sigConfig" "";
BA_DEF_DEF_  "sigExplanation" "";
BA_ "GenMsgSendType" BO_ 214 3;
BA_ "VFrameFormat" BO_ 214 14;
BA_ "GenMsgSendType" BO_ 215 3;
BA_ "VFrameFormat" BO_ 215 14;
BA_ "GenMsgSendType" BO_ 128 3;
BA_ "VFrameFormat" BO_ 128 14;
BA_ "GenMsgSendType" BO_ 129 3;
BA_ "VFrameFormat" BO_ 129 14;
BA_ "GenMsgSendType" BO_ 130 3;
BA_ "VFrameFormat" BO_ 130 14;
BA_ "GenMsgSendType" BO_ 131 3;
BA_ "VFrameFormat" BO_ 131 14;
BA_ "GenMsgSendType" BO_ 132 3;
BA_ "VFrameFormat" BO_ 132 14;
BA_ "GenMsgSendType" BO_ 133 3;
BA_ "VFrameFormat" BO_ 133 14;
BA_ "GenMsgSendType" BO_ 134 3;
BA_ "VFrameFormat" BO_ 134 14;
BA_ "GenMsgSendType" BO_ 135 3;
BA_ "VFrameFormat" BO_ 135 14;
BA_ "GenMsgSendType" BO_ 136 3;
BA_ "VFrameFormat" BO_ 136 14;
BA_ "GenMsgCycleTime" BO_ 930 100;
BA_ "VFrameFormat" BO_ 930 14;
BA_ "GenMsgSendType" BO_ 384 3;
BA_ "VFrameFormat" BO_ 384 14;
BA_ "GenMsgSendType" BO_ 385 3;
BA_ "VFrameFormat" BO_ 385 14;
BA_ "GenMsgSendType" BO_ 386 3;
BA_ "VFrameFormat" BO_ 386 14;
BA_ "GenMsgSendType" BO_ 387 3;
BA_ "VFrameFormat" BO_ 387 14;
BA_ "GenMsgSendType" BO_ 388 3;
BA_ "VFrameFormat" BO_ 388 14;
BA_ "GenMsgSendType" BO_ 400 3;
BA_ "VFrameFormat" BO_ 400 14;
BA_ "GenMsgSendType" BO_ 401 3;
BA_ "VFrameFormat" BO_ 401 14;
BA_ "GenMsgSendType" BO_ 402 3;
BA_ "VFrameFormat" BO_ 402 14;
BA_ "GenMsgSendType" BO_ 403 3;
BA_ "VFrameFormat" BO_ 403 14;
BA_ "GenMsgSendType" BO_ 404 3;
BA_ "VFrameFormat" BO_ 404 14;
BA_ "GenMsgSendType" BO_ 405 3;
BA_ "VFrameFormat" BO_ 405 14;
BA_ "GenMsgSendType" BO_ 406 3;
BA_ "VFrameFormat" BO_ 406 14;
BA_ "GenMsgSendType" BO_ 407 3;
BA_ "VFrameFormat" BO_ 407 14;
BA_ "GenMsgSendType" BO_ 408 3;
BA_ "VFrameFormat" BO_ 408 14;
BA_ "GenMsgSendType" BO_ 409 3;
BA_ "VFrameFormat" BO_ 409 14;
BA_ "GenSigSendType" SG_ 214 VFC_Obj19A_CRC 9;
BA_ "GenSigSendType" SG_ 214 VFC_Obj19A_AliveCtr 9;
BA_ "GenSigSendType" SG_ 214 VFC_Obj19A_BlockCtr 9;
BA_ "GenSigSendType" SG_ 214 VFC_Obj19A_ProtOrderIndex 9;
BA_ "GenSigStartValue" SG_ 214 VFC_Obj19A_Ax 160;
BA_ "GenSigSendType" SG_ 214 VFC_Obj19A_Ax 9;
BA_ "GenSigStartValue" SG_ 214 VFC_Obj19A_Vx 1540;
BA_ "GenSigSendType" SG_ 214 VFC_Obj19A_Vx 9;
BA_ "GenSigSendType" SG_ 214 VFC_Obj19A_Dx 9;
BA_ "GenSigStartValue" SG_ 214 VFC_Obj19A_Dy 8000;
BA_ "GenSigSendType" SG_ 214 VFC_Obj19A_Dy 9;
BA_ "GenSigStartValue" SG_ 214 VFC_Obj19A_Vy 500;
BA_ "GenSigSendType" SG_ 214 VFC_Obj19A_Vy 9;
BA_ "GenSigStartValue" SG_ 214 VFC_Obj19A_Ay 120;
BA_ "GenSigSendType" SG_ 214 VFC_Obj19A_Ay 9;
BA_ "GenSigSendType" SG_ 214 VFC_Obj19A_DyStdDev 9;
BA_ "GenSigSendType" SG_ 214 VFC_Obj19A_DxStdDev 9;
BA_ "GenSigSendType" SG_ 214 VFC_Obj19A_VxStdDev 9;
BA_ "GenSigSendType" SG_ 214 VFC_Obj19A_ExistProb 9;
BA_ "GenSigSendType" SG_ 214 VFC_Obj19A_VyStdDev 9;
BA_ "GenSigSendType" SG_ 214 VFC_Obj19A_TypeProb 9;
BA_ "GenSigSendType" SG_ 214 VFC_Obj19A_AxStdDev 9;
BA_ "GenSigSendType" SG_ 214 VFC_Obj19A_AyStdDev 9;
BA_ "GenSigStartValue" SG_ 214 VFC_Obj19A_PhiLeft 4000;
BA_ "GenSigSendType" SG_ 214 VFC_Obj19A_PhiLeft 9;
BA_ "GenSigSendType" SG_ 214 VFC_Obj19A_ClassifiedView 9;
BA_ "GenSigSendType" SG_ 214 VFC_Obj19A_Length 9;
BA_ "GenSigSendType" SG_ 214 VFC_Obj19A_WidthStdDev 9;
BA_ "GenSigSendType" SG_ 214 VFC_Obj19A_Height 9;
BA_ "GenSigSendType" SG_ 214 VFC_Obj19A_HeightStdDev 9;
BA_ "GenSigSendType" SG_ 214 VFC_Obj19A_PhiLeftStdDev 9;
BA_ "GenSigSendType" SG_ 214 VFC_Obj19A_HeadingStdDev 9;
BA_ "GenSigSendType" SG_ 214 VFC_Obj19A_Measured 9;
BA_ "GenSigStartValue" SG_ 214 VFC_Obj19A_Heading 157;
BA_ "GenSigSendType" SG_ 214 VFC_Obj19A_Heading 9;
BA_ "GenSigSendType" SG_ 214 VFC_Obj19A_LengthStdDev 9;
BA_ "GenSigStartValue" SG_ 214 VFC_Obj19A_PhiMid 4000;
BA_ "GenSigSendType" SG_ 214 VFC_Obj19A_PhiMid 9;
BA_ "GenSigSendType" SG_ 214 VFC_Obj19A_Width 9;
BA_ "GenSigSendType" SG_ 214 VFC_Obj19A_PhiMidStdDev 9;
BA_ "GenSigStartValue" SG_ 214 VFC_Obj19A_PhiRight 4000;
BA_ "GenSigSendType" SG_ 214 VFC_Obj19A_PhiRight 9;
BA_ "GenSigSendType" SG_ 214 VFC_Obj19A_VisibleView 9;
BA_ "GenSigSendType" SG_ 214 VFC_Obj19A_PhiRightStdDev 9;
BA_ "GenSigStartValue" SG_ 214 VFC_Obj19A_PhiLeftVel 4000;
BA_ "GenSigSendType" SG_ 214 VFC_Obj19A_PhiLeftVel 9;
BA_ "GenSigStartValue" SG_ 214 VFC_Obj19A_PhiRightVel 4000;
BA_ "GenSigSendType" SG_ 214 VFC_Obj19A_PhiRightVel 9;
BA_ "GenSigSendType" SG_ 214 VFC_Obj19A_PhiRightVelStdDev 9;
BA_ "GenSigSendType" SG_ 214 VFC_Obj19A_PhiLeftVelStdDev 9;
BA_ "GenSigStartValue" SG_ 214 VFC_Obj19A_PhiTop 1600;
BA_ "GenSigSendType" SG_ 214 VFC_Obj19A_PhiTop 9;
BA_ "GenSigStartValue" SG_ 214 VFC_Obj19A_PhiBottom 1600;
BA_ "GenSigSendType" SG_ 214 VFC_Obj19A_PhiBottom 9;
BA_ "GenSigSendType" SG_ 214 VFC_Obj19A_PhiTopStdDev 9;
BA_ "GenSigSendType" SG_ 214 VFC_Obj19A_HeadOrientation 9;
BA_ "GenSigSendType" SG_ 214 VFC_Obj19A_Type 9;
BA_ "GenSigSendType" SG_ 214 VFC_Obj19A_PhiBottomStdDev 9;
BA_ "GenSigStartValue" SG_ 214 VFC_Obj19A_NormVx 40000;
BA_ "GenSigSendType" SG_ 214 VFC_Obj19A_NormVx 9;
BA_ "GenSigStartValue" SG_ 214 VFC_Obj19A_NormAx 5000;
BA_ "GenSigSendType" SG_ 214 VFC_Obj19A_NormAx 9;
BA_ "GenSigSendType" SG_ 214 VFC_Obj19A_NormAxStdDev 9;
BA_ "GenSigSendType" SG_ 214 VFC_Obj19A_ProbMovingLat 9;
BA_ "GenSigSendType" SG_ 214 VFC_Obj19A_ID 9;
BA_ "GenSigSendType" SG_ 214 VFC_Obj19A_NormVxStdDev 9;
BA_ "GenSigSendType" SG_ 214 VFC_Obj19A_ProbMovingLong 9;
BA_ "GenSigSendType" SG_ 215 VFC_Obj19B_TTIPC_StdDev 9;
BA_ "GenSigSendType" SG_ 215 VFC_Obj19B_TTIPC 9;
BA_ "GenSigStartValue" SG_ 215 VFC_Obj19B_AngLongitude 500;
BA_ "GenSigSendType" SG_ 215 VFC_Obj19B_AngLongitude 9;
BA_ "GenSigSendType" SG_ 215 VFC_Obj19B_CRC 9;
BA_ "GenSigSendType" SG_ 215 VFC_Obj19B_AliveCtr 9;
BA_ "GenSigSendType" SG_ 215 VFC_Obj19B_BlockCtr 9;
BA_ "GenSigSendType" SG_ 215 VFC_Obj19B_ScaleChange 9;
BA_ "GenSigSendType" SG_ 215 VFC_Obj19B_ScaleChngStdDev 9;
BA_ "GenSigSendType" SG_ 215 VFC_Obj19B_LineEdgeRightEgo 9;
BA_ "GenSigSendType" SG_ 215 VFC_Obj19B_LineEdgeLeftEgo 9;
BA_ "GenSigSendType" SG_ 215 VFC_Obj19B_CompletelyInImg 9;
BA_ "GenSigSendType" SG_ 215 VFC_Obj19B_DirIndicator 9;
BA_ "GenSigStartValue" SG_ 215 VFC_Obj19B_LineEdgeAngle 4000;
BA_ "GenSigSendType" SG_ 215 VFC_Obj19B_LineEdgeAngle 9;
BA_ "GenSigSendType" SG_ 215 VFC_Obj19B_BrakeLight 9;
BA_ "GenSigSendType" SG_ 215 VFC_Obj19B_MeasSource 9;
BA_ "GenSigSendType" SG_ 215 VFC_Obj19B_Reliab 9;
BA_ "GenSigSendType" SG_ 128 VFC_LineHdr_AUTOSARTStamp 9;
BA_ "GenSigSendType" SG_ 128 VFC_LineHdr_FrameNo 9;
BA_ "GenSigSendType" SG_ 128 VFC_LineHdr_CRC 9;
BA_ "GenSigSendType" SG_ 128 VFC_LineHdr_AliveCtr 9;
BA_ "GenSigSendType" SG_ 128 VFC_LineHdr_BlockCounter 9;
BA_ "GenSigSendType" SG_ 128 VFC_LineHdr_Report 9;
BA_ "GenSigSendType" SG_ 128 VFC_LineHdr_LineCount 9;
BA_ "GenSigSendType" SG_ 128 VFC_LineHdr_PEPSIRuntime 9;
BA_ "GenSigSendType" SG_ 128 VFC_LineHdr_TimeStamp 9;
BA_ "GenSigSendType" SG_ 128 VFC_LineHdr_Blindness 9;
BA_ "GenSigSendType" SG_ 128 VFC_LineHdr_State 9;
BA_ "GenSigSendType" SG_ 129 VFC_Line01_CRC 9;
BA_ "GenSigSendType" SG_ 129 VFC_Line01_AliveCtr 9;
BA_ "GenSigSendType" SG_ 129 VFC_Line01_BlockCounter 9;
BA_ "GenSigSendType" SG_ 129 VFC_Line01_ProtOrderIndex 9;
BA_ "GenSigSendType" SG_ 129 VFC_Line01_LineID 9;
BA_ "GenSigSendType" SG_ 129 VFC_Line01_LaneRelation 9;
BA_ "GenSigSendType" SG_ 129 VFC_Line01_ExistProb 9;
BA_ "GenSigSendType" SG_ 129 VFC_Line01_DxStart 9;
BA_ "GenSigSendType" SG_ 129 VFC_Line01_ColorClass 9;
BA_ "GenSigSendType" SG_ 129 VFC_Line01_DxEnd 9;
BA_ "GenSigStartValue" SG_ 129 VFC_Line01_HeadingAngle 3277;
BA_ "GenSigSendType" SG_ 129 VFC_Line01_HeadingAngle 9;
BA_ "GenSigStartValue" SG_ 129 VFC_Line01_Dy 2048;
BA_ "GenSigSendType" SG_ 129 VFC_Line01_Dy 9;
BA_ "GenSigStartValue" SG_ 129 VFC_Line01_CurvChange 2048;
BA_ "GenSigSendType" SG_ 129 VFC_Line01_CurvChange 9;
BA_ "GenSigStartValue" SG_ 129 VFC_Line01_Curv 4096;
BA_ "GenSigSendType" SG_ 129 VFC_Line01_Curv 9;
BA_ "GenSigSendType" SG_ 129 VFC_Line01_MeasureType 9;
BA_ "GenSigSendType" SG_ 129 VFC_Line01_LineWidth 9;
BA_ "GenSigSendType" SG_ 129 VFC_Line01_CourseDeviation 9;
BA_ "GenSigSendType" SG_ 129 VFC_Line01_Type 9;
BA_ "GenSigSendType" SG_ 129 VFC_Line01_DyStdDevDxEnd 9;
BA_ "GenSigSendType" SG_ 129 VFC_Line01_HypoConfidence 9;
BA_ "GenSigSendType" SG_ 129 VFC_Line01_prevID 9;
BA_ "GenSigSendType" SG_ 129 VFC_Line01_nextID 9;
BA_ "GenSigSendType" SG_ 129 VFC_Line01_DyStdDevDxStart 9;
BA_ "GenSigSendType" SG_ 129 VFC_Line01_TypeProb 9;
BA_ "GenSigSendType" SG_ 129 VFC_Line01_DyStdDevDxMid 9;
BA_ "GenSigSendType" SG_ 130 VFC_Line02_CRC 9;
BA_ "GenSigSendType" SG_ 130 VFC_Line02_AliveCtr 9;
BA_ "GenSigSendType" SG_ 130 VFC_Line02_BlockCounter 9;
BA_ "GenSigSendType" SG_ 130 VFC_Line02_ProtOrderIndex 9;
BA_ "GenSigSendType" SG_ 130 VFC_Line02_LineID 9;
BA_ "GenSigSendType" SG_ 130 VFC_Line02_LaneRelation 9;
BA_ "GenSigSendType" SG_ 130 VFC_Line02_ExistProb 9;
BA_ "GenSigSendType" SG_ 130 VFC_Line02_DxStart 9;
BA_ "GenSigSendType" SG_ 130 VFC_Line02_ColorClass 9;
BA_ "GenSigSendType" SG_ 130 VFC_Line02_DxEnd 9;
BA_ "GenSigStartValue" SG_ 130 VFC_Line02_HeadingAngle 3277;
BA_ "GenSigSendType" SG_ 130 VFC_Line02_HeadingAngle 9;
BA_ "GenSigStartValue" SG_ 130 VFC_Line02_Dy 2048;
BA_ "GenSigSendType" SG_ 130 VFC_Line02_Dy 9;
BA_ "GenSigStartValue" SG_ 130 VFC_Line02_CurvChange 2048;
BA_ "GenSigSendType" SG_ 130 VFC_Line02_CurvChange 9;
BA_ "GenSigStartValue" SG_ 130 VFC_Line02_Curv 4096;
BA_ "GenSigSendType" SG_ 130 VFC_Line02_Curv 9;
BA_ "GenSigSendType" SG_ 130 VFC_Line02_MeasureType 9;
BA_ "GenSigSendType" SG_ 130 VFC_Line02_LineWidth 9;
BA_ "GenSigSendType" SG_ 130 VFC_Line02_CourseDeviation 9;
BA_ "GenSigSendType" SG_ 130 VFC_Line02_Type 9;
BA_ "GenSigSendType" SG_ 130 VFC_Line02_DyStdDevDxEnd 9;
BA_ "GenSigSendType" SG_ 130 VFC_Line02_HypoConfidence 9;
BA_ "GenSigSendType" SG_ 130 VFC_Line02_prevID 9;
BA_ "GenSigSendType" SG_ 130 VFC_Line02_nextID 9;
BA_ "GenSigSendType" SG_ 130 VFC_Line02_DyStdDevDxStart 9;
BA_ "GenSigSendType" SG_ 130 VFC_Line02_TypeProb 9;
BA_ "GenSigSendType" SG_ 130 VFC_Line02_DyStdDevDxMid 9;
BA_ "GenSigSendType" SG_ 131 VFC_Line03_CRC 9;
BA_ "GenSigSendType" SG_ 131 VFC_Line03_AliveCtr 9;
BA_ "GenSigSendType" SG_ 131 VFC_Line03_BlockCounter 9;
BA_ "GenSigSendType" SG_ 131 VFC_Line03_ProtOrderIndex 9;
BA_ "GenSigSendType" SG_ 131 VFC_Line03_LineID 9;
BA_ "GenSigSendType" SG_ 131 VFC_Line03_LaneRelation 9;
BA_ "GenSigSendType" SG_ 131 VFC_Line03_ExistProb 9;
BA_ "GenSigSendType" SG_ 131 VFC_Line03_DxStart 9;
BA_ "GenSigSendType" SG_ 131 VFC_Line03_ColorClass 9;
BA_ "GenSigSendType" SG_ 131 VFC_Line03_DxEnd 9;
BA_ "GenSigStartValue" SG_ 131 VFC_Line03_HeadingAngle 3277;
BA_ "GenSigSendType" SG_ 131 VFC_Line03_HeadingAngle 9;
BA_ "GenSigStartValue" SG_ 131 VFC_Line03_Dy 2048;
BA_ "GenSigSendType" SG_ 131 VFC_Line03_Dy 9;
BA_ "GenSigStartValue" SG_ 131 VFC_Line03_CurvChange 2048;
BA_ "GenSigSendType" SG_ 131 VFC_Line03_CurvChange 9;
BA_ "GenSigStartValue" SG_ 131 VFC_Line03_Curv 4096;
BA_ "GenSigSendType" SG_ 131 VFC_Line03_Curv 9;
BA_ "GenSigSendType" SG_ 131 VFC_Line03_MeasureType 9;
BA_ "GenSigSendType" SG_ 131 VFC_Line03_LineWidth 9;
BA_ "GenSigSendType" SG_ 131 VFC_Line03_CourseDeviation 9;
BA_ "GenSigSendType" SG_ 131 VFC_Line03_Type 9;
BA_ "GenSigSendType" SG_ 131 VFC_Line03_DyStdDevDxEnd 9;
BA_ "GenSigSendType" SG_ 131 VFC_Line03_HypoConfidence 9;
BA_ "GenSigSendType" SG_ 131 VFC_Line03_prevID 9;
BA_ "GenSigSendType" SG_ 131 VFC_Line03_nextID 9;
BA_ "GenSigSendType" SG_ 131 VFC_Line03_DyStdDevDxStart 9;
BA_ "GenSigSendType" SG_ 131 VFC_Line03_TypeProb 9;
BA_ "GenSigSendType" SG_ 131 VFC_Line03_DyStdDevDxMid 9;
BA_ "GenSigSendType" SG_ 132 VFC_Line04_CRC 9;
BA_ "GenSigSendType" SG_ 132 VFC_Line04_AliveCtr 9;
BA_ "GenSigSendType" SG_ 132 VFC_Line04_BlockCounter 9;
BA_ "GenSigSendType" SG_ 132 VFC_Line04_ProtOrderIndex 9;
BA_ "GenSigSendType" SG_ 132 VFC_Line04_LineID 9;
BA_ "GenSigSendType" SG_ 132 VFC_Line04_LaneRelation 9;
BA_ "GenSigSendType" SG_ 132 VFC_Line04_ExistProb 9;
BA_ "GenSigSendType" SG_ 132 VFC_Line04_DxStart 9;
BA_ "GenSigSendType" SG_ 132 VFC_Line04_ColorClass 9;
BA_ "GenSigSendType" SG_ 132 VFC_Line04_DxEnd 9;
BA_ "GenSigStartValue" SG_ 132 VFC_Line04_HeadingAngle 3277;
BA_ "GenSigSendType" SG_ 132 VFC_Line04_HeadingAngle 9;
BA_ "GenSigStartValue" SG_ 132 VFC_Line04_Dy 2048;
BA_ "GenSigSendType" SG_ 132 VFC_Line04_Dy 9;
BA_ "GenSigStartValue" SG_ 132 VFC_Line04_CurvChange 2048;
BA_ "GenSigSendType" SG_ 132 VFC_Line04_CurvChange 9;
BA_ "GenSigStartValue" SG_ 132 VFC_Line04_Curv 4096;
BA_ "GenSigSendType" SG_ 132 VFC_Line04_Curv 9;
BA_ "GenSigSendType" SG_ 132 VFC_Line04_MeasureType 9;
BA_ "GenSigSendType" SG_ 132 VFC_Line04_LineWidth 9;
BA_ "GenSigSendType" SG_ 132 VFC_Line04_CourseDeviation 9;
BA_ "GenSigSendType" SG_ 132 VFC_Line04_Type 9;
BA_ "GenSigSendType" SG_ 132 VFC_Line04_DyStdDevDxEnd 9;
BA_ "GenSigSendType" SG_ 132 VFC_Line04_HypoConfidence 9;
BA_ "GenSigSendType" SG_ 132 VFC_Line04_prevID 9;
BA_ "GenSigSendType" SG_ 132 VFC_Line04_nextID 9;
BA_ "GenSigSendType" SG_ 132 VFC_Line04_DyStdDevDxStart 9;
BA_ "GenSigSendType" SG_ 132 VFC_Line04_TypeProb 9;
BA_ "GenSigSendType" SG_ 132 VFC_Line04_DyStdDevDxMid 9;
BA_ "GenSigSendType" SG_ 133 VFC_Line05_CRC 9;
BA_ "GenSigSendType" SG_ 133 VFC_Line05_AliveCtr 9;
BA_ "GenSigSendType" SG_ 133 VFC_Line05_BlockCounter 9;
BA_ "GenSigSendType" SG_ 133 VFC_Line05_ProtOrderIndex 9;
BA_ "GenSigSendType" SG_ 133 VFC_Line05_LineID 9;
BA_ "GenSigSendType" SG_ 133 VFC_Line05_LaneRelation 9;
BA_ "GenSigSendType" SG_ 133 VFC_Line05_ExistProb 9;
BA_ "GenSigSendType" SG_ 133 VFC_Line05_DxStart 9;
BA_ "GenSigSendType" SG_ 133 VFC_Line05_ColorClass 9;
BA_ "GenSigSendType" SG_ 133 VFC_Line05_DxEnd 9;
BA_ "GenSigStartValue" SG_ 133 VFC_Line05_HeadingAngle 3277;
BA_ "GenSigSendType" SG_ 133 VFC_Line05_HeadingAngle 9;
BA_ "GenSigStartValue" SG_ 133 VFC_Line05_Dy 2048;
BA_ "GenSigSendType" SG_ 133 VFC_Line05_Dy 9;
BA_ "GenSigStartValue" SG_ 133 VFC_Line05_CurvChange 2048;
BA_ "GenSigSendType" SG_ 133 VFC_Line05_CurvChange 9;
BA_ "GenSigStartValue" SG_ 133 VFC_Line05_Curv 4096;
BA_ "GenSigSendType" SG_ 133 VFC_Line05_Curv 9;
BA_ "GenSigSendType" SG_ 133 VFC_Line05_MeasureType 9;
BA_ "GenSigSendType" SG_ 133 VFC_Line05_LineWidth 9;
BA_ "GenSigSendType" SG_ 133 VFC_Line05_CourseDeviation 9;
BA_ "GenSigSendType" SG_ 133 VFC_Line05_Type 9;
BA_ "GenSigSendType" SG_ 133 VFC_Line05_DyStdDevDxEnd 9;
BA_ "GenSigSendType" SG_ 133 VFC_Line05_HypoConfidence 9;
BA_ "GenSigSendType" SG_ 133 VFC_Line05_prevID 9;
BA_ "GenSigSendType" SG_ 133 VFC_Line05_nextID 9;
BA_ "GenSigSendType" SG_ 133 VFC_Line05_DyStdDevDxStart 9;
BA_ "GenSigSendType" SG_ 133 VFC_Line05_TypeProb 9;
BA_ "GenSigSendType" SG_ 133 VFC_Line05_DyStdDevDxMid 9;
BA_ "GenSigSendType" SG_ 134 VFC_Line06_CRC 9;
BA_ "GenSigSendType" SG_ 134 VFC_Line06_AliveCtr 9;
BA_ "GenSigSendType" SG_ 134 VFC_Line06_BlockCounter 9;
BA_ "GenSigSendType" SG_ 134 VFC_Line06_ProtOrderIndex 9;
BA_ "GenSigSendType" SG_ 134 VFC_Line06_LineID 9;
BA_ "GenSigSendType" SG_ 134 VFC_Line06_LaneRelation 9;
BA_ "GenSigSendType" SG_ 134 VFC_Line06_ExistProb 9;
BA_ "GenSigSendType" SG_ 134 VFC_Line06_DxStart 9;
BA_ "GenSigSendType" SG_ 134 VFC_Line06_ColorClass 9;
BA_ "GenSigSendType" SG_ 134 VFC_Line06_DxEnd 9;
BA_ "GenSigStartValue" SG_ 134 VFC_Line06_HeadingAngle 3277;
BA_ "GenSigSendType" SG_ 134 VFC_Line06_HeadingAngle 9;
BA_ "GenSigStartValue" SG_ 134 VFC_Line06_Dy 2048;
BA_ "GenSigSendType" SG_ 134 VFC_Line06_Dy 9;
BA_ "GenSigStartValue" SG_ 134 VFC_Line06_CurvChange 2048;
BA_ "GenSigSendType" SG_ 134 VFC_Line06_CurvChange 9;
BA_ "GenSigStartValue" SG_ 134 VFC_Line06_Curv 4096;
BA_ "GenSigSendType" SG_ 134 VFC_Line06_Curv 9;
BA_ "GenSigSendType" SG_ 134 VFC_Line06_MeasureType 9;
BA_ "GenSigSendType" SG_ 134 VFC_Line06_LineWidth 9;
BA_ "GenSigSendType" SG_ 134 VFC_Line06_CourseDeviation 9;
BA_ "GenSigSendType" SG_ 134 VFC_Line06_Type 9;
BA_ "GenSigSendType" SG_ 134 VFC_Line06_DyStdDevDxEnd 9;
BA_ "GenSigSendType" SG_ 134 VFC_Line06_HypoConfidence 9;
BA_ "GenSigSendType" SG_ 134 VFC_Line06_prevID 9;
BA_ "GenSigSendType" SG_ 134 VFC_Line06_nextID 9;
BA_ "GenSigSendType" SG_ 134 VFC_Line06_DyStdDevDxStart 9;
BA_ "GenSigSendType" SG_ 134 VFC_Line06_TypeProb 9;
BA_ "GenSigSendType" SG_ 134 VFC_Line06_DyStdDevDxMid 9;
BA_ "GenSigSendType" SG_ 135 VFC_Line07_CRC 9;
BA_ "GenSigSendType" SG_ 135 VFC_Line07_AliveCtr 9;
BA_ "GenSigSendType" SG_ 135 VFC_Line07_BlockCounter 9;
BA_ "GenSigSendType" SG_ 135 VFC_Line07_ProtOrderIndex 9;
BA_ "GenSigSendType" SG_ 135 VFC_Line07_LineID 9;
BA_ "GenSigSendType" SG_ 135 VFC_Line07_LaneRelation 9;
BA_ "GenSigSendType" SG_ 135 VFC_Line07_ExistProb 9;
BA_ "GenSigSendType" SG_ 135 VFC_Line07_DxStart 9;
BA_ "GenSigSendType" SG_ 135 VFC_Line07_ColorClass 9;
BA_ "GenSigSendType" SG_ 135 VFC_Line07_DxEnd 9;
BA_ "GenSigStartValue" SG_ 135 VFC_Line07_HeadingAngle 3277;
BA_ "GenSigSendType" SG_ 135 VFC_Line07_HeadingAngle 9;
BA_ "GenSigStartValue" SG_ 135 VFC_Line07_Dy 2048;
BA_ "GenSigSendType" SG_ 135 VFC_Line07_Dy 9;
BA_ "GenSigStartValue" SG_ 135 VFC_Line07_CurvChange 2048;
BA_ "GenSigSendType" SG_ 135 VFC_Line07_CurvChange 9;
BA_ "GenSigStartValue" SG_ 135 VFC_Line07_Curv 4096;
BA_ "GenSigSendType" SG_ 135 VFC_Line07_Curv 9;
BA_ "GenSigSendType" SG_ 135 VFC_Line07_MeasureType 9;
BA_ "GenSigSendType" SG_ 135 VFC_Line07_LineWidth 9;
BA_ "GenSigSendType" SG_ 135 VFC_Line07_CourseDeviation 9;
BA_ "GenSigSendType" SG_ 135 VFC_Line07_Type 9;
BA_ "GenSigSendType" SG_ 135 VFC_Line07_DyStdDevDxEnd 9;
BA_ "GenSigSendType" SG_ 135 VFC_Line07_HypoConfidence 9;
BA_ "GenSigSendType" SG_ 135 VFC_Line07_prevID 9;
BA_ "GenSigSendType" SG_ 135 VFC_Line07_nextID 9;
BA_ "GenSigSendType" SG_ 135 VFC_Line07_DyStdDevDxStart 9;
BA_ "GenSigSendType" SG_ 135 VFC_Line07_TypeProb 9;
BA_ "GenSigSendType" SG_ 135 VFC_Line07_DyStdDevDxMid 9;
BA_ "GenSigSendType" SG_ 136 VFC_Line08_CRC 9;
BA_ "GenSigSendType" SG_ 136 VFC_Line08_AliveCtr 9;
BA_ "GenSigSendType" SG_ 136 VFC_Line08_BlockCounter 9;
BA_ "GenSigSendType" SG_ 136 VFC_Line08_ProtOrderIndex 9;
BA_ "GenSigSendType" SG_ 136 VFC_Line08_LineID 9;
BA_ "GenSigSendType" SG_ 136 VFC_Line08_LaneRelation 9;
BA_ "GenSigSendType" SG_ 136 VFC_Line08_ExistProb 9;
BA_ "GenSigSendType" SG_ 136 VFC_Line08_DxStart 9;
BA_ "GenSigSendType" SG_ 136 VFC_Line08_ColorClass 9;
BA_ "GenSigSendType" SG_ 136 VFC_Line08_DxEnd 9;
BA_ "GenSigStartValue" SG_ 136 VFC_Line08_HeadingAngle 3277;
BA_ "GenSigSendType" SG_ 136 VFC_Line08_HeadingAngle 9;
BA_ "GenSigStartValue" SG_ 136 VFC_Line08_Dy 2048;
BA_ "GenSigSendType" SG_ 136 VFC_Line08_Dy 9;
BA_ "GenSigStartValue" SG_ 136 VFC_Line08_CurvChange 2048;
BA_ "GenSigSendType" SG_ 136 VFC_Line08_CurvChange 9;
BA_ "GenSigStartValue" SG_ 136 VFC_Line08_Curv 4096;
BA_ "GenSigSendType" SG_ 136 VFC_Line08_Curv 9;
BA_ "GenSigSendType" SG_ 136 VFC_Line08_MeasureType 9;
BA_ "GenSigSendType" SG_ 136 VFC_Line08_LineWidth 9;
BA_ "GenSigSendType" SG_ 136 VFC_Line08_CourseDeviation 9;
BA_ "GenSigSendType" SG_ 136 VFC_Line08_Type 9;
BA_ "GenSigSendType" SG_ 136 VFC_Line08_DyStdDevDxEnd 9;
BA_ "GenSigSendType" SG_ 136 VFC_Line08_HypoConfidence 9;
BA_ "GenSigSendType" SG_ 136 VFC_Line08_prevID 9;
BA_ "GenSigSendType" SG_ 136 VFC_Line08_nextID 9;
BA_ "GenSigSendType" SG_ 136 VFC_Line08_DyStdDevDxStart 9;
BA_ "GenSigSendType" SG_ 136 VFC_Line08_TypeProb 9;
BA_ "GenSigSendType" SG_ 136 VFC_Line08_DyStdDevDxMid 9;
BA_ "GenSigSendType" SG_ 384 RFC_Hdr00_CRC 9;
BA_ "GenSigSendType" SG_ 384 RFC_Hdr00_AliveCtr 9;
BA_ "GenSigSendType" SG_ 384 RFC_Hdr00_ProtBlockCtr 9;
BA_ "GenSigSendType" SG_ 384 RFC_Hdr00_ProtocolVersion 9;
BA_ "GenSigStartValue" SG_ 384 RFC_Hdr00_ProtocolVersion 773;
BA_ "GenSigSendType" SG_ 384 RFC_Hdr00_ProtLocationCount 9;
BA_ "GenSigSendType" SG_ 384 RFC_Hdr00_SensorState 9;
BA_ "GenSigSendType" SG_ 384 RFC_Hdr00_TimeStamp 9;
BA_ "GenSigSendType" SG_ 384 RFC_Hdr00_TimeStampStatus 9;
BA_ "GenSigSendType" SG_ 384 RFC_Hdr00_LocDownSel 9;
BA_ "GenSigSendType" SG_ 384 RFC_Hdr00_BliThetaVld 9;
BA_ "GenSigSendType" SG_ 384 RFC_Hdr00_BliThetaSIMOVld 9;
BA_ "GenSigSendType" SG_ 384 RFC_Hdr00_BliThetaMIMOVld 9;
BA_ "GenSigSendType" SG_ 384 RFC_Hdr00_BliThetaSIMOShareVld 9;
BA_ "GenSigSendType" SG_ 384 RFC_Hdr00_BliThetaMIMOShareVld 9;
BA_ "GenSigSendType" SG_ 384 RFC_Hdr00_BliPhiVld 9;
BA_ "GenSigSendType" SG_ 384 RFC_Hdr00_BliRCSMOVld 9;
BA_ "GenSigSendType" SG_ 384 RFC_Hdr00_BliBinOverThresholdVld 9;
BA_ "GenSigSendType" SG_ 384 RFC_Hdr00_BliNumValidReflectVld 9;
BA_ "GenSigSendType" SG_ 384 RFC_Hdr00_BliTheta 9;
BA_ "GenSigSendType" SG_ 384 RFC_Hdr00_BliThetaSIMO 9;
BA_ "GenSigSendType" SG_ 384 RFC_Hdr00_BliThetaMIMO 9;
BA_ "GenSigSendType" SG_ 384 RFC_Hdr00_BliThetaSIMOShare 9;
BA_ "GenSigSendType" SG_ 384 RFC_Hdr00_BliThetaMIMOShare 9;
BA_ "GenSigSendType" SG_ 384 RFC_Hdr00_BliPhi 9;
BA_ "GenSigSendType" SG_ 384 RFC_Hdr00_BliRCSMO 9;
BA_ "GenSigSendType" SG_ 384 RFC_Hdr00_BliBinsOverThreshold 9;
BA_ "GenSigSendType" SG_ 384 RFC_Hdr00_BliNumValidReflections 9;
BA_ "GenSigSendType" SG_ 384 RFC_Hdr00_BliCrossCorrSO 9;
BA_ "GenSigSendType" SG_ 384 RFC_Hdr00_BliCrossCorrSOVld 9;
BA_ "GenSigSendType" SG_ 385 RFC_Hdr01_PersVerWriteCnt03 9;
BA_ "GenSigSendType" SG_ 385 RFC_Hdr01_PersVerWriteCnt02 9;
BA_ "GenSigSendType" SG_ 385 RFC_Hdr01_PersVerWriteCnt01 9;
BA_ "GenSigSendType" SG_ 385 RFC_Hdr01_CRC 9;
BA_ "GenSigSendType" SG_ 385 RFC_Hdr01_AliveCtr 9;
BA_ "GenSigSendType" SG_ 385 RFC_Hdr01_ProtBlockCtr 9;
BA_ "GenSigSendType" SG_ 385 RFC_Hdr01_PersVerWriteCnt00 9;
BA_ "GenSigSendType" SG_ 385 RFC_Hdr01_PersAngIndAzi 9;
BA_ "GenSigSendType" SG_ 385 RFC_Hdr01_PersAngIndElev 9;
BA_ "GenSigSendType" SG_ 385 RFC_Hdr01_PersAngIndAziMean 9;
BA_ "GenSigSendType" SG_ 385 RFC_Hdr01_PersAngIndElevMean 9;
BA_ "GenSigSendType" SG_ 385 RFC_Hdr01_PersAngIndAziVnce 9;
BA_ "GenSigSendType" SG_ 385 RFC_Hdr01_PersAngIndElevVnce 9;
BA_ "GenSigSendType" SG_ 385 RFC_Hdr01_PersAngIndAziElevCov 9;
BA_ "GenSigSendType" SG_ 385 RFC_Hdr01_PersAngCurrAzi 9;
BA_ "GenSigSendType" SG_ 385 RFC_Hdr01_PersAngCurrElev 9;
BA_ "GenSigSendType" SG_ 385 RFC_Hdr01_PersAngCurrAziMean 9;
BA_ "GenSigSendType" SG_ 385 RFC_Hdr01_PersAngCurrElevMean 9;
BA_ "GenSigSendType" SG_ 385 RFC_Hdr01_PersAngCurrAziVnce 9;
BA_ "GenSigSendType" SG_ 385 RFC_Hdr01_PersAngCurrElevVnce 9;
BA_ "GenSigSendType" SG_ 385 RFC_Hdr01_PersAngCurrAziElevCov 9;
BA_ "GenSigSendType" SG_ 386 RFC_Hdr02_ModPerfDMax 9;
BA_ "GenSigSendType" SG_ 386 RFC_Hdr02_CRC 9;
BA_ "GenSigSendType" SG_ 386 RFC_Hdr02_AliveCtr 9;
BA_ "GenSigSendType" SG_ 386 RFC_Hdr02_ProtBlockCtr 9;
BA_ "GenSigSendType" SG_ 386 RFC_Hdr02_PersFiltDspMalIndAzi 9;
BA_ "GenSigSendType" SG_ 386 RFC_Hdr02_PersFiltWeightIndAzi 9;
BA_ "GenSigSendType" SG_ 386 RFC_Hdr02_PersFiltDspCurrAzi 9;
BA_ "GenSigSendType" SG_ 386 RFC_Hdr02_PersFiltDspMalIndElev 9;
BA_ "GenSigSendType" SG_ 386 RFC_Hdr02_PersFiltWeightIndElev 9;
BA_ "GenSigSendType" SG_ 386 RFC_Hdr02_PersFiltDspCurrElev 9;
BA_ "GenSigSendType" SG_ 386 RFC_Hdr02_PersMalStablePosAzi 9;
BA_ "GenSigSendType" SG_ 386 RFC_Hdr02_PersMalStablePosElev 9;
BA_ "GenSigSendType" SG_ 386 RFC_Hdr02_PersChDetPozAzi 9;
BA_ "GenSigSendType" SG_ 386 RFC_Hdr02_PersChDetNegAzi 9;
BA_ "GenSigSendType" SG_ 386 RFC_Hdr02_PersChDetPozElev 9;
BA_ "GenSigSendType" SG_ 386 RFC_Hdr02_PersChDetNegElev 9;
BA_ "GenSigSendType" SG_ 386 RFC_Hdr02_MntAziCur 9;
BA_ "GenSigSendType" SG_ 386 RFC_Hdr02_MntElevCur 9;
BA_ "GenSigSendType" SG_ 386 RFC_Hdr02_PersOutOfSpecAzi 9;
BA_ "GenSigSendType" SG_ 386 RFC_Hdr02_PersOutOfSpecElev 9;
BA_ "GenSigSendType" SG_ 387 RFC_Hdr03_CRC 9;
BA_ "GenSigSendType" SG_ 387 RFC_Hdr03_AliveCtr 9;
BA_ "GenSigSendType" SG_ 387 RFC_Hdr03_ProtBlockCtr 9;
BA_ "GenSigSendType" SG_ 387 RFC_Hdr03_FoVdMaxTheta00 9;
BA_ "GenSigSendType" SG_ 387 RFC_Hdr03_FoVdMaxTheta01 9;
BA_ "GenSigSendType" SG_ 387 RFC_Hdr03_FoVdMaxTheta02 9;
BA_ "GenSigSendType" SG_ 387 RFC_Hdr03_FoVdMaxTheta03 9;
BA_ "GenSigSendType" SG_ 387 RFC_Hdr03_FoVdMaxTheta04 9;
BA_ "GenSigSendType" SG_ 387 RFC_Hdr03_FoVdMaxTheta05 9;
BA_ "GenSigSendType" SG_ 387 RFC_Hdr03_FoVdMaxTheta06 9;
BA_ "GenSigSendType" SG_ 387 RFC_Hdr03_FoVdMaxTheta07 9;
BA_ "GenSigSendType" SG_ 387 RFC_Hdr03_FoVdMaxTheta08 9;
BA_ "GenSigSendType" SG_ 387 RFC_Hdr03_FoVdMaxTheta09 9;
BA_ "GenSigSendType" SG_ 387 RFC_Hdr03_FoVdMaxTheta10 9;
BA_ "GenSigSendType" SG_ 387 RFC_Hdr03_FoVdMaxTheta11 9;
BA_ "GenSigSendType" SG_ 387 RFC_Hdr03_FoVdMaxTheta12 9;
BA_ "GenSigSendType" SG_ 387 RFC_Hdr03_FoVdMaxTheta13 9;
BA_ "GenSigSendType" SG_ 387 RFC_Hdr03_FoVdMaxTheta14 9;
BA_ "GenSigSendType" SG_ 387 RFC_Hdr03_FoVdMaxTheta15 9;
BA_ "GenSigSendType" SG_ 387 RFC_Hdr03_FoVdMaxTheta16 9;
BA_ "GenSigSendType" SG_ 387 RFC_Hdr03_FoVdMaxTheta17 9;
BA_ "GenSigSendType" SG_ 387 RFC_Hdr03_FoVdMaxTheta18 9;
BA_ "GenSigSendType" SG_ 387 RFC_Hdr03_FoVdMaxTheta19 9;
BA_ "GenSigSendType" SG_ 387 RFC_Hdr03_FoVdMaxTheta20 9;
BA_ "GenSigSendType" SG_ 387 RFC_Hdr03_FoVdMaxTheta21 9;
BA_ "GenSigSendType" SG_ 387 RFC_Hdr03_FoVdMaxTheta22 9;
BA_ "GenSigSendType" SG_ 387 RFC_Hdr03_FoVdMaxTheta23 9;
BA_ "GenSigSendType" SG_ 387 RFC_Hdr03_FoVdMaxTheta24 9;
BA_ "GenSigSendType" SG_ 387 RFC_Hdr03_FoVdMaxPhi00 9;
BA_ "GenSigSendType" SG_ 387 RFC_Hdr03_FoVTheta00 9;
BA_ "GenSigSendType" SG_ 387 RFC_Hdr03_FoVTheta01 9;
BA_ "GenSigSendType" SG_ 387 RFC_Hdr03_FoVTheta02 9;
BA_ "GenSigSendType" SG_ 387 RFC_Hdr03_FoVTheta03 9;
BA_ "GenSigSendType" SG_ 387 RFC_Hdr03_FoVTheta04 9;
BA_ "GenSigSendType" SG_ 387 RFC_Hdr03_FoVTheta05 9;
BA_ "GenSigSendType" SG_ 387 RFC_Hdr03_FoVTheta06 9;
BA_ "GenSigSendType" SG_ 387 RFC_Hdr03_FoVTheta07 9;
BA_ "GenSigSendType" SG_ 387 RFC_Hdr03_FoVTheta08 9;
BA_ "GenSigSendType" SG_ 387 RFC_Hdr03_FoVTheta09 9;
BA_ "GenSigSendType" SG_ 387 RFC_Hdr03_FoVTheta10 9;
BA_ "GenSigSendType" SG_ 387 RFC_Hdr03_FoVTheta11 9;
BA_ "GenSigSendType" SG_ 387 RFC_Hdr03_FoVTheta12 9;
BA_ "GenSigSendType" SG_ 387 RFC_Hdr03_FoVTheta13 9;
BA_ "GenSigSendType" SG_ 387 RFC_Hdr03_FoVTheta14 9;
BA_ "GenSigSendType" SG_ 387 RFC_Hdr03_FoVTheta15 9;
BA_ "GenSigSendType" SG_ 387 RFC_Hdr03_FoVTheta16 9;
BA_ "GenSigSendType" SG_ 387 RFC_Hdr03_FoVTheta17 9;
BA_ "GenSigSendType" SG_ 387 RFC_Hdr03_FoVTheta18 9;
BA_ "GenSigSendType" SG_ 387 RFC_Hdr03_FoVTheta19 9;
BA_ "GenSigSendType" SG_ 387 RFC_Hdr03_FoVTheta20 9;
BA_ "GenSigSendType" SG_ 387 RFC_Hdr03_FoVTheta21 9;
BA_ "GenSigSendType" SG_ 387 RFC_Hdr03_FoVTheta22 9;
BA_ "GenSigSendType" SG_ 387 RFC_Hdr03_FoVTheta23 9;
BA_ "GenSigSendType" SG_ 387 RFC_Hdr03_FoVTheta24 9;
BA_ "GenSigSendType" SG_ 387 RFC_Hdr03_FoVdMaxPhi01 9;
BA_ "GenSigSendType" SG_ 387 RFC_Hdr03_FoVdMaxPhi02 9;
BA_ "GenSigSendType" SG_ 387 RFC_Hdr03_FoVdMaxPhi03 9;
BA_ "GenSigSendType" SG_ 387 RFC_Hdr03_FoVdMaxPhi04 9;
BA_ "GenSigSendType" SG_ 387 RFC_Hdr03_FoVdMaxPhi05 9;
BA_ "GenSigSendType" SG_ 387 RFC_Hdr03_FoVdMaxPhi06 9;
BA_ "GenSigSendType" SG_ 388 RFC_Hdr04_CRC 9;
BA_ "GenSigSendType" SG_ 388 RFC_Hdr04_AliveCtr 9;
BA_ "GenSigSendType" SG_ 388 RFC_Hdr04_ProtBlockCtr 9;
BA_ "GenSigSendType" SG_ 388 RFC_Hdr04_FoVdMaxPhi07 9;
BA_ "GenSigSendType" SG_ 388 RFC_Hdr04_FoVdMaxPhi08 9;
BA_ "GenSigSendType" SG_ 388 RFC_Hdr04_FoVdMaxPhi09 9;
BA_ "GenSigSendType" SG_ 388 RFC_Hdr04_FoVdMaxPhi10 9;
BA_ "GenSigSendType" SG_ 388 RFC_Hdr04_FoVPhi00 9;
BA_ "GenSigSendType" SG_ 388 RFC_Hdr04_FoVPhi01 9;
BA_ "GenSigSendType" SG_ 388 RFC_Hdr04_FoVPhi02 9;
BA_ "GenSigSendType" SG_ 388 RFC_Hdr04_FoVPhi03 9;
BA_ "GenSigSendType" SG_ 388 RFC_Hdr04_FoVPhi04 9;
BA_ "GenSigSendType" SG_ 388 RFC_Hdr04_FoVPhi05 9;
BA_ "GenSigSendType" SG_ 388 RFC_Hdr04_FoVPhi06 9;
BA_ "GenSigSendType" SG_ 388 RFC_Hdr04_FoVPhi07 9;
BA_ "GenSigSendType" SG_ 388 RFC_Hdr04_FoVPhi08 9;
BA_ "GenSigSendType" SG_ 388 RFC_Hdr04_FoVPhi09 9;
BA_ "GenSigSendType" SG_ 388 RFC_Hdr04_FoVPhi10 9;
BA_ "GenSigSendType" SG_ 388 RFC_Hdr04_MntPosX 9;
BA_ "GenSigSendType" SG_ 388 RFC_Hdr04_MntPosY 9;
BA_ "GenSigSendType" SG_ 388 RFC_Hdr04_MntPosZ 9;
BA_ "GenSigSendType" SG_ 388 RFC_Hdr04_MntAziNom 9;
BA_ "GenSigSendType" SG_ 388 RFC_Hdr04_MntElevNom 9;
BA_ "GenSigSendType" SG_ 388 RFC_Hdr04_InitCov 9;
BA_ "GenSigSendType" SG_ 388 RFC_Hdr04_TspMeasID 9;
BA_ "GenSigSendType" SG_ 388 RFC_Hdr04_TspSensID 9;
BA_ "GenSigSendType" SG_ 388 RFC_Hdr04_TspLastMeas 9;
BA_ "GenSigSendType" SG_ 388 RFC_Hdr04_TspLastRec 9;
BA_ "GenSigSendType" SG_ 388 RFC_Hdr04_TspPredMeas 9;
BA_ "GenSigSendType" SG_ 388 RFC_Hdr04_TspPredRec 9;
BA_ "GenSigSendType" SG_ 400 RFC_Loc000_CRC 9;
BA_ "GenSigSendType" SG_ 400 RFC_Loc000_AliveCtr 9;
BA_ "GenSigSendType" SG_ 400 RFC_Loc000_ProtBlockCtr 9;
BA_ "GenSigSendType" SG_ 400 RFC_Loc000_Dr 9;
BA_ "GenSigSendType" SG_ 400 RFC_Loc000_Vr 9;
BA_ "GenSigStartValue" SG_ 400 RFC_Loc000_Vr 32768;
BA_ "GenSigSendType" SG_ 400 RFC_Loc000_Theta 9;
BA_ "GenSigStartValue" SG_ 400 RFC_Loc000_Theta 32768;
BA_ "GenSigSendType" SG_ 400 RFC_Loc000_Phi 9;
BA_ "GenSigStartValue" SG_ 400 RFC_Loc000_Phi 32768;
BA_ "GenSigSendType" SG_ 400 RFC_Loc000_DrVnce 9;
BA_ "GenSigSendType" SG_ 400 RFC_Loc000_VrVnce 9;
BA_ "GenSigSendType" SG_ 400 RFC_Loc000_ThetaVnce 9;
BA_ "GenSigSendType" SG_ 400 RFC_Loc000_PhiVnce 9;
BA_ "GenSigSendType" SG_ 400 RFC_Loc000_DrVrCoVnce 9;
BA_ "GenSigStartValue" SG_ 400 RFC_Loc000_DrVrCoVnce 32768;
BA_ "GenSigSendType" SG_ 400 RFC_Loc000_RCS 9;
BA_ "GenSigStartValue" SG_ 400 RFC_Loc000_RCS 32768;
BA_ "GenSigSendType" SG_ 400 RFC_Loc000_RSSI 9;
BA_ "GenSigSendType" SG_ 400 RFC_Loc000_DrVrQuality 9;
BA_ "GenSigSendType" SG_ 400 RFC_Loc000_ThetaQuality 9;
BA_ "GenSigSendType" SG_ 400 RFC_Loc000_PhiQuality 9;
BA_ "GenSigSendType" SG_ 400 RFC_Loc001_Dr 9;
BA_ "GenSigSendType" SG_ 400 RFC_Loc001_Vr 9;
BA_ "GenSigStartValue" SG_ 400 RFC_Loc001_Vr 32768;
BA_ "GenSigSendType" SG_ 400 RFC_Loc001_Theta 9;
BA_ "GenSigStartValue" SG_ 400 RFC_Loc001_Theta 32768;
BA_ "GenSigSendType" SG_ 400 RFC_Loc001_Phi 9;
BA_ "GenSigStartValue" SG_ 400 RFC_Loc001_Phi 32768;
BA_ "GenSigSendType" SG_ 400 RFC_Loc001_DrVnce 9;
BA_ "GenSigSendType" SG_ 400 RFC_Loc001_VrVnce 9;
BA_ "GenSigSendType" SG_ 400 RFC_Loc001_ThetaVnce 9;
BA_ "GenSigSendType" SG_ 400 RFC_Loc001_PhiVnce 9;
BA_ "GenSigSendType" SG_ 400 RFC_Loc001_DrVrCoVnce 9;
BA_ "GenSigStartValue" SG_ 400 RFC_Loc001_DrVrCoVnce 32768;
BA_ "GenSigSendType" SG_ 400 RFC_Loc001_RCS 9;
BA_ "GenSigStartValue" SG_ 400 RFC_Loc001_RCS 32768;
BA_ "GenSigSendType" SG_ 400 RFC_Loc001_RSSI 9;
BA_ "GenSigSendType" SG_ 400 RFC_Loc001_DrVrQuality 9;
BA_ "GenSigSendType" SG_ 400 RFC_Loc001_ThetaQuality 9;
BA_ "GenSigSendType" SG_ 400 RFC_Loc001_PhiQuality 9;
BA_ "GenSigSendType" SG_ 401 RFC_Loc002_CRC 9;
BA_ "GenSigSendType" SG_ 401 RFC_Loc002_AliveCtr 9;
BA_ "GenSigSendType" SG_ 401 RFC_Loc002_ProtBlockCtr 9;
BA_ "GenSigSendType" SG_ 401 RFC_Loc002_Dr 9;
BA_ "GenSigSendType" SG_ 401 RFC_Loc002_Vr 9;
BA_ "GenSigStartValue" SG_ 401 RFC_Loc002_Vr 32768;
BA_ "GenSigSendType" SG_ 401 RFC_Loc002_Theta 9;
BA_ "GenSigStartValue" SG_ 401 RFC_Loc002_Theta 32768;
BA_ "GenSigSendType" SG_ 401 RFC_Loc002_Phi 9;
BA_ "GenSigStartValue" SG_ 401 RFC_Loc002_Phi 32768;
BA_ "GenSigSendType" SG_ 401 RFC_Loc002_DrVnce 9;
BA_ "GenSigSendType" SG_ 401 RFC_Loc002_VrVnce 9;
BA_ "GenSigSendType" SG_ 401 RFC_Loc002_ThetaVnce 9;
BA_ "GenSigSendType" SG_ 401 RFC_Loc002_PhiVnce 9;
BA_ "GenSigSendType" SG_ 401 RFC_Loc002_DrVrCoVnce 9;
BA_ "GenSigStartValue" SG_ 401 RFC_Loc002_DrVrCoVnce 32768;
BA_ "GenSigSendType" SG_ 401 RFC_Loc002_RCS 9;
BA_ "GenSigStartValue" SG_ 401 RFC_Loc002_RCS 32768;
BA_ "GenSigSendType" SG_ 401 RFC_Loc002_RSSI 9;
BA_ "GenSigSendType" SG_ 401 RFC_Loc002_DrVrQuality 9;
BA_ "GenSigSendType" SG_ 401 RFC_Loc002_ThetaQuality 9;
BA_ "GenSigSendType" SG_ 401 RFC_Loc002_PhiQuality 9;
BA_ "GenSigSendType" SG_ 401 RFC_Loc003_Dr 9;
BA_ "GenSigSendType" SG_ 401 RFC_Loc003_Vr 9;
BA_ "GenSigStartValue" SG_ 401 RFC_Loc003_Vr 32768;
BA_ "GenSigSendType" SG_ 401 RFC_Loc003_Theta 9;
BA_ "GenSigStartValue" SG_ 401 RFC_Loc003_Theta 32768;
BA_ "GenSigSendType" SG_ 401 RFC_Loc003_Phi 9;
BA_ "GenSigStartValue" SG_ 401 RFC_Loc003_Phi 32768;
BA_ "GenSigSendType" SG_ 401 RFC_Loc003_DrVnce 9;
BA_ "GenSigSendType" SG_ 401 RFC_Loc003_VrVnce 9;
BA_ "GenSigSendType" SG_ 401 RFC_Loc003_ThetaVnce 9;
BA_ "GenSigSendType" SG_ 401 RFC_Loc003_PhiVnce 9;
BA_ "GenSigSendType" SG_ 401 RFC_Loc003_DrVrCoVnce 9;
BA_ "GenSigStartValue" SG_ 401 RFC_Loc003_DrVrCoVnce 32768;
BA_ "GenSigSendType" SG_ 401 RFC_Loc003_RCS 9;
BA_ "GenSigStartValue" SG_ 401 RFC_Loc003_RCS 32768;
BA_ "GenSigSendType" SG_ 401 RFC_Loc003_RSSI 9;
BA_ "GenSigSendType" SG_ 401 RFC_Loc003_DrVrQuality 9;
BA_ "GenSigSendType" SG_ 401 RFC_Loc003_ThetaQuality 9;
BA_ "GenSigSendType" SG_ 401 RFC_Loc003_PhiQuality 9;
BA_ "GenSigSendType" SG_ 402 RFC_Loc004_CRC 9;
BA_ "GenSigSendType" SG_ 402 RFC_Loc004_AliveCtr 9;
BA_ "GenSigSendType" SG_ 402 RFC_Loc004_ProtBlockCtr 9;
BA_ "GenSigSendType" SG_ 402 RFC_Loc004_Dr 9;
BA_ "GenSigSendType" SG_ 402 RFC_Loc004_Vr 9;
BA_ "GenSigStartValue" SG_ 402 RFC_Loc004_Vr 32768;
BA_ "GenSigSendType" SG_ 402 RFC_Loc004_Theta 9;
BA_ "GenSigStartValue" SG_ 402 RFC_Loc004_Theta 32768;
BA_ "GenSigSendType" SG_ 402 RFC_Loc004_Phi 9;
BA_ "GenSigStartValue" SG_ 402 RFC_Loc004_Phi 32768;
BA_ "GenSigSendType" SG_ 402 RFC_Loc004_DrVnce 9;
BA_ "GenSigSendType" SG_ 402 RFC_Loc004_VrVnce 9;
BA_ "GenSigSendType" SG_ 402 RFC_Loc004_ThetaVnce 9;
BA_ "GenSigSendType" SG_ 402 RFC_Loc004_PhiVnce 9;
BA_ "GenSigSendType" SG_ 402 RFC_Loc004_DrVrCoVnce 9;
BA_ "GenSigStartValue" SG_ 402 RFC_Loc004_DrVrCoVnce 32768;
BA_ "GenSigSendType" SG_ 402 RFC_Loc004_RCS 9;
BA_ "GenSigStartValue" SG_ 402 RFC_Loc004_RCS 32768;
BA_ "GenSigSendType" SG_ 402 RFC_Loc004_RSSI 9;
BA_ "GenSigSendType" SG_ 402 RFC_Loc004_DrVrQuality 9;
BA_ "GenSigSendType" SG_ 402 RFC_Loc004_ThetaQuality 9;
BA_ "GenSigSendType" SG_ 402 RFC_Loc004_PhiQuality 9;
BA_ "GenSigSendType" SG_ 402 RFC_Loc005_Dr 9;
BA_ "GenSigSendType" SG_ 402 RFC_Loc005_Vr 9;
BA_ "GenSigStartValue" SG_ 402 RFC_Loc005_Vr 32768;
BA_ "GenSigSendType" SG_ 402 RFC_Loc005_Theta 9;
BA_ "GenSigStartValue" SG_ 402 RFC_Loc005_Theta 32768;
BA_ "GenSigSendType" SG_ 402 RFC_Loc005_Phi 9;
BA_ "GenSigStartValue" SG_ 402 RFC_Loc005_Phi 32768;
BA_ "GenSigSendType" SG_ 402 RFC_Loc005_DrVnce 9;
BA_ "GenSigSendType" SG_ 402 RFC_Loc005_VrVnce 9;
BA_ "GenSigSendType" SG_ 402 RFC_Loc005_ThetaVnce 9;
BA_ "GenSigSendType" SG_ 402 RFC_Loc005_PhiVnce 9;
BA_ "GenSigSendType" SG_ 402 RFC_Loc005_DrVrCoVnce 9;
BA_ "GenSigStartValue" SG_ 402 RFC_Loc005_DrVrCoVnce 32768;
BA_ "GenSigSendType" SG_ 402 RFC_Loc005_RCS 9;
BA_ "GenSigStartValue" SG_ 402 RFC_Loc005_RCS 32768;
BA_ "GenSigSendType" SG_ 402 RFC_Loc005_RSSI 9;
BA_ "GenSigSendType" SG_ 402 RFC_Loc005_DrVrQuality 9;
BA_ "GenSigSendType" SG_ 402 RFC_Loc005_ThetaQuality 9;
BA_ "GenSigSendType" SG_ 402 RFC_Loc005_PhiQuality 9;
BA_ "GenSigSendType" SG_ 403 RFC_Loc006_CRC 9;
BA_ "GenSigSendType" SG_ 403 RFC_Loc006_AliveCtr 9;
BA_ "GenSigSendType" SG_ 403 RFC_Loc006_ProtBlockCtr 9;
BA_ "GenSigSendType" SG_ 403 RFC_Loc006_Dr 9;
BA_ "GenSigSendType" SG_ 403 RFC_Loc006_Vr 9;
BA_ "GenSigStartValue" SG_ 403 RFC_Loc006_Vr 32768;
BA_ "GenSigSendType" SG_ 403 RFC_Loc006_Theta 9;
BA_ "GenSigStartValue" SG_ 403 RFC_Loc006_Theta 32768;
BA_ "GenSigSendType" SG_ 403 RFC_Loc006_Phi 9;
BA_ "GenSigStartValue" SG_ 403 RFC_Loc006_Phi 32768;
BA_ "GenSigSendType" SG_ 403 RFC_Loc006_DrVnce 9;
BA_ "GenSigSendType" SG_ 403 RFC_Loc006_VrVnce 9;
BA_ "GenSigSendType" SG_ 403 RFC_Loc006_ThetaVnce 9;
BA_ "GenSigSendType" SG_ 403 RFC_Loc006_PhiVnce 9;
BA_ "GenSigSendType" SG_ 403 RFC_Loc006_DrVrCoVnce 9;
BA_ "GenSigStartValue" SG_ 403 RFC_Loc006_DrVrCoVnce 32768;
BA_ "GenSigSendType" SG_ 403 RFC_Loc006_RCS 9;
BA_ "GenSigStartValue" SG_ 403 RFC_Loc006_RCS 32768;
BA_ "GenSigSendType" SG_ 403 RFC_Loc006_RSSI 9;
BA_ "GenSigSendType" SG_ 403 RFC_Loc006_DrVrQuality 9;
BA_ "GenSigSendType" SG_ 403 RFC_Loc006_ThetaQuality 9;
BA_ "GenSigSendType" SG_ 403 RFC_Loc006_PhiQuality 9;
BA_ "GenSigSendType" SG_ 403 RFC_Loc007_Dr 9;
BA_ "GenSigSendType" SG_ 403 RFC_Loc007_Vr 9;
BA_ "GenSigStartValue" SG_ 403 RFC_Loc007_Vr 32768;
BA_ "GenSigSendType" SG_ 403 RFC_Loc007_Theta 9;
BA_ "GenSigStartValue" SG_ 403 RFC_Loc007_Theta 32768;
BA_ "GenSigSendType" SG_ 403 RFC_Loc007_Phi 9;
BA_ "GenSigStartValue" SG_ 403 RFC_Loc007_Phi 32768;
BA_ "GenSigSendType" SG_ 403 RFC_Loc007_DrVnce 9;
BA_ "GenSigSendType" SG_ 403 RFC_Loc007_VrVnce 9;
BA_ "GenSigSendType" SG_ 403 RFC_Loc007_ThetaVnce 9;
BA_ "GenSigSendType" SG_ 403 RFC_Loc007_PhiVnce 9;
BA_ "GenSigSendType" SG_ 403 RFC_Loc007_DrVrCoVnce 9;
BA_ "GenSigStartValue" SG_ 403 RFC_Loc007_DrVrCoVnce 32768;
BA_ "GenSigSendType" SG_ 403 RFC_Loc007_RCS 9;
BA_ "GenSigStartValue" SG_ 403 RFC_Loc007_RCS 32768;
BA_ "GenSigSendType" SG_ 403 RFC_Loc007_RSSI 9;
BA_ "GenSigSendType" SG_ 403 RFC_Loc007_DrVrQuality 9;
BA_ "GenSigSendType" SG_ 403 RFC_Loc007_ThetaQuality 9;
BA_ "GenSigSendType" SG_ 403 RFC_Loc007_PhiQuality 9;
BA_ "GenSigSendType" SG_ 404 RFC_Loc008_CRC 9;
BA_ "GenSigSendType" SG_ 404 RFC_Loc008_AliveCtr 9;
BA_ "GenSigSendType" SG_ 404 RFC_Loc008_ProtBlockCtr 9;
BA_ "GenSigSendType" SG_ 404 RFC_Loc008_Dr 9;
BA_ "GenSigSendType" SG_ 404 RFC_Loc008_Vr 9;
BA_ "GenSigStartValue" SG_ 404 RFC_Loc008_Vr 32768;
BA_ "GenSigSendType" SG_ 404 RFC_Loc008_Theta 9;
BA_ "GenSigStartValue" SG_ 404 RFC_Loc008_Theta 32768;
BA_ "GenSigSendType" SG_ 404 RFC_Loc008_Phi 9;
BA_ "GenSigStartValue" SG_ 404 RFC_Loc008_Phi 32768;
BA_ "GenSigSendType" SG_ 404 RFC_Loc008_DrVnce 9;
BA_ "GenSigSendType" SG_ 404 RFC_Loc008_VrVnce 9;
BA_ "GenSigSendType" SG_ 404 RFC_Loc008_ThetaVnce 9;
BA_ "GenSigSendType" SG_ 404 RFC_Loc008_PhiVnce 9;
BA_ "GenSigSendType" SG_ 404 RFC_Loc008_DrVrCoVnce 9;
BA_ "GenSigStartValue" SG_ 404 RFC_Loc008_DrVrCoVnce 32768;
BA_ "GenSigSendType" SG_ 404 RFC_Loc008_RCS 9;
BA_ "GenSigStartValue" SG_ 404 RFC_Loc008_RCS 32768;
BA_ "GenSigSendType" SG_ 404 RFC_Loc008_RSSI 9;
BA_ "GenSigSendType" SG_ 404 RFC_Loc008_DrVrQuality 9;
BA_ "GenSigSendType" SG_ 404 RFC_Loc008_ThetaQuality 9;
BA_ "GenSigSendType" SG_ 404 RFC_Loc008_PhiQuality 9;
BA_ "GenSigSendType" SG_ 404 RFC_Loc009_Dr 9;
BA_ "GenSigSendType" SG_ 404 RFC_Loc009_Vr 9;
BA_ "GenSigStartValue" SG_ 404 RFC_Loc009_Vr 32768;
BA_ "GenSigSendType" SG_ 404 RFC_Loc009_Theta 9;
BA_ "GenSigStartValue" SG_ 404 RFC_Loc009_Theta 32768;
BA_ "GenSigSendType" SG_ 404 RFC_Loc009_Phi 9;
BA_ "GenSigStartValue" SG_ 404 RFC_Loc009_Phi 32768;
BA_ "GenSigSendType" SG_ 404 RFC_Loc009_DrVnce 9;
BA_ "GenSigSendType" SG_ 404 RFC_Loc009_VrVnce 9;
BA_ "GenSigSendType" SG_ 404 RFC_Loc009_ThetaVnce 9;
BA_ "GenSigSendType" SG_ 404 RFC_Loc009_PhiVnce 9;
BA_ "GenSigSendType" SG_ 404 RFC_Loc009_DrVrCoVnce 9;
BA_ "GenSigStartValue" SG_ 404 RFC_Loc009_DrVrCoVnce 32768;
BA_ "GenSigSendType" SG_ 404 RFC_Loc009_RCS 9;
BA_ "GenSigStartValue" SG_ 404 RFC_Loc009_RCS 32768;
BA_ "GenSigSendType" SG_ 404 RFC_Loc009_RSSI 9;
BA_ "GenSigSendType" SG_ 404 RFC_Loc009_DrVrQuality 9;
BA_ "GenSigSendType" SG_ 404 RFC_Loc009_ThetaQuality 9;
BA_ "GenSigSendType" SG_ 404 RFC_Loc009_PhiQuality 9;
BA_ "GenSigSendType" SG_ 405 RFC_Loc010_CRC 9;
BA_ "GenSigSendType" SG_ 405 RFC_Loc010_AliveCtr 9;
BA_ "GenSigSendType" SG_ 405 RFC_Loc010_ProtBlockCtr 9;
BA_ "GenSigSendType" SG_ 405 RFC_Loc010_Dr 9;
BA_ "GenSigSendType" SG_ 405 RFC_Loc010_Vr 9;
BA_ "GenSigStartValue" SG_ 405 RFC_Loc010_Vr 32768;
BA_ "GenSigSendType" SG_ 405 RFC_Loc010_Theta 9;
BA_ "GenSigStartValue" SG_ 405 RFC_Loc010_Theta 32768;
BA_ "GenSigSendType" SG_ 405 RFC_Loc010_Phi 9;
BA_ "GenSigStartValue" SG_ 405 RFC_Loc010_Phi 32768;
BA_ "GenSigSendType" SG_ 405 RFC_Loc010_DrVnce 9;
BA_ "GenSigSendType" SG_ 405 RFC_Loc010_VrVnce 9;
BA_ "GenSigSendType" SG_ 405 RFC_Loc010_ThetaVnce 9;
BA_ "GenSigSendType" SG_ 405 RFC_Loc010_PhiVnce 9;
BA_ "GenSigSendType" SG_ 405 RFC_Loc010_DrVrCoVnce 9;
BA_ "GenSigStartValue" SG_ 405 RFC_Loc010_DrVrCoVnce 32768;
BA_ "GenSigSendType" SG_ 405 RFC_Loc010_RCS 9;
BA_ "GenSigStartValue" SG_ 405 RFC_Loc010_RCS 32768;
BA_ "GenSigSendType" SG_ 405 RFC_Loc010_RSSI 9;
BA_ "GenSigSendType" SG_ 405 RFC_Loc010_DrVrQuality 9;
BA_ "GenSigSendType" SG_ 405 RFC_Loc010_ThetaQuality 9;
BA_ "GenSigSendType" SG_ 405 RFC_Loc010_PhiQuality 9;
BA_ "GenSigSendType" SG_ 405 RFC_Loc011_Dr 9;
BA_ "GenSigSendType" SG_ 405 RFC_Loc011_Vr 9;
BA_ "GenSigStartValue" SG_ 405 RFC_Loc011_Vr 32768;
BA_ "GenSigSendType" SG_ 405 RFC_Loc011_Theta 9;
BA_ "GenSigStartValue" SG_ 405 RFC_Loc011_Theta 32768;
BA_ "GenSigSendType" SG_ 405 RFC_Loc011_Phi 9;
BA_ "GenSigStartValue" SG_ 405 RFC_Loc011_Phi 32768;
BA_ "GenSigSendType" SG_ 405 RFC_Loc011_DrVnce 9;
BA_ "GenSigSendType" SG_ 405 RFC_Loc011_VrVnce 9;
BA_ "GenSigSendType" SG_ 405 RFC_Loc011_ThetaVnce 9;
BA_ "GenSigSendType" SG_ 405 RFC_Loc011_PhiVnce 9;
BA_ "GenSigSendType" SG_ 405 RFC_Loc011_DrVrCoVnce 9;
BA_ "GenSigStartValue" SG_ 405 RFC_Loc011_DrVrCoVnce 32768;
BA_ "GenSigSendType" SG_ 405 RFC_Loc011_RCS 9;
BA_ "GenSigStartValue" SG_ 405 RFC_Loc011_RCS 32768;
BA_ "GenSigSendType" SG_ 405 RFC_Loc011_RSSI 9;
BA_ "GenSigSendType" SG_ 405 RFC_Loc011_DrVrQuality 9;
BA_ "GenSigSendType" SG_ 405 RFC_Loc011_ThetaQuality 9;
BA_ "GenSigSendType" SG_ 405 RFC_Loc011_PhiQuality 9;
BA_ "GenSigSendType" SG_ 406 RFC_Loc012_CRC 9;
BA_ "GenSigSendType" SG_ 406 RFC_Loc012_AliveCtr 9;
BA_ "GenSigSendType" SG_ 406 RFC_Loc012_ProtBlockCtr 9;
BA_ "GenSigSendType" SG_ 406 RFC_Loc012_Dr 9;
BA_ "GenSigSendType" SG_ 406 RFC_Loc012_Vr 9;
BA_ "GenSigStartValue" SG_ 406 RFC_Loc012_Vr 32768;
BA_ "GenSigSendType" SG_ 406 RFC_Loc012_Theta 9;
BA_ "GenSigStartValue" SG_ 406 RFC_Loc012_Theta 32768;
BA_ "GenSigSendType" SG_ 406 RFC_Loc012_Phi 9;
BA_ "GenSigStartValue" SG_ 406 RFC_Loc012_Phi 32768;
BA_ "GenSigSendType" SG_ 406 RFC_Loc012_DrVnce 9;
BA_ "GenSigSendType" SG_ 406 RFC_Loc012_VrVnce 9;
BA_ "GenSigSendType" SG_ 406 RFC_Loc012_ThetaVnce 9;
BA_ "GenSigSendType" SG_ 406 RFC_Loc012_PhiVnce 9;
BA_ "GenSigSendType" SG_ 406 RFC_Loc012_DrVrCoVnce 9;
BA_ "GenSigStartValue" SG_ 406 RFC_Loc012_DrVrCoVnce 32768;
BA_ "GenSigSendType" SG_ 406 RFC_Loc012_RCS 9;
BA_ "GenSigStartValue" SG_ 406 RFC_Loc012_RCS 32768;
BA_ "GenSigSendType" SG_ 406 RFC_Loc012_RSSI 9;
BA_ "GenSigSendType" SG_ 406 RFC_Loc012_DrVrQuality 9;
BA_ "GenSigSendType" SG_ 406 RFC_Loc012_ThetaQuality 9;
BA_ "GenSigSendType" SG_ 406 RFC_Loc012_PhiQuality 9;
BA_ "GenSigSendType" SG_ 406 RFC_Loc013_Dr 9;
BA_ "GenSigSendType" SG_ 406 RFC_Loc013_Vr 9;
BA_ "GenSigStartValue" SG_ 406 RFC_Loc013_Vr 32768;
BA_ "GenSigSendType" SG_ 406 RFC_Loc013_Theta 9;
BA_ "GenSigStartValue" SG_ 406 RFC_Loc013_Theta 32768;
BA_ "GenSigSendType" SG_ 406 RFC_Loc013_Phi 9;
BA_ "GenSigStartValue" SG_ 406 RFC_Loc013_Phi 32768;
BA_ "GenSigSendType" SG_ 406 RFC_Loc013_DrVnce 9;
BA_ "GenSigSendType" SG_ 406 RFC_Loc013_VrVnce 9;
BA_ "GenSigSendType" SG_ 406 RFC_Loc013_ThetaVnce 9;
BA_ "GenSigSendType" SG_ 406 RFC_Loc013_PhiVnce 9;
BA_ "GenSigSendType" SG_ 406 RFC_Loc013_DrVrCoVnce 9;
BA_ "GenSigStartValue" SG_ 406 RFC_Loc013_DrVrCoVnce 32768;
BA_ "GenSigSendType" SG_ 406 RFC_Loc013_RCS 9;
BA_ "GenSigStartValue" SG_ 406 RFC_Loc013_RCS 32768;
BA_ "GenSigSendType" SG_ 406 RFC_Loc013_RSSI 9;
BA_ "GenSigSendType" SG_ 406 RFC_Loc013_DrVrQuality 9;
BA_ "GenSigSendType" SG_ 406 RFC_Loc013_ThetaQuality 9;
BA_ "GenSigSendType" SG_ 406 RFC_Loc013_PhiQuality 9;
BA_ "GenSigSendType" SG_ 407 RFC_Loc014_CRC 9;
BA_ "GenSigSendType" SG_ 407 RFC_Loc014_AliveCtr 9;
BA_ "GenSigSendType" SG_ 407 RFC_Loc014_ProtBlockCtr 9;
BA_ "GenSigSendType" SG_ 407 RFC_Loc014_Dr 9;
BA_ "GenSigSendType" SG_ 407 RFC_Loc014_Vr 9;
BA_ "GenSigStartValue" SG_ 407 RFC_Loc014_Vr 32768;
BA_ "GenSigSendType" SG_ 407 RFC_Loc014_Theta 9;
BA_ "GenSigStartValue" SG_ 407 RFC_Loc014_Theta 32768;
BA_ "GenSigSendType" SG_ 407 RFC_Loc014_Phi 9;
BA_ "GenSigStartValue" SG_ 407 RFC_Loc014_Phi 32768;
BA_ "GenSigSendType" SG_ 407 RFC_Loc014_DrVnce 9;
BA_ "GenSigSendType" SG_ 407 RFC_Loc014_VrVnce 9;
BA_ "GenSigSendType" SG_ 407 RFC_Loc014_ThetaVnce 9;
BA_ "GenSigSendType" SG_ 407 RFC_Loc014_PhiVnce 9;
BA_ "GenSigSendType" SG_ 407 RFC_Loc014_DrVrCoVnce 9;
BA_ "GenSigStartValue" SG_ 407 RFC_Loc014_DrVrCoVnce 32768;
BA_ "GenSigSendType" SG_ 407 RFC_Loc014_RCS 9;
BA_ "GenSigStartValue" SG_ 407 RFC_Loc014_RCS 32768;
BA_ "GenSigSendType" SG_ 407 RFC_Loc014_RSSI 9;
BA_ "GenSigSendType" SG_ 407 RFC_Loc014_DrVrQuality 9;
BA_ "GenSigSendType" SG_ 407 RFC_Loc014_ThetaQuality 9;
BA_ "GenSigSendType" SG_ 407 RFC_Loc014_PhiQuality 9;
BA_ "GenSigSendType" SG_ 407 RFC_Loc015_Dr 9;
BA_ "GenSigSendType" SG_ 407 RFC_Loc015_Vr 9;
BA_ "GenSigStartValue" SG_ 407 RFC_Loc015_Vr 32768;
BA_ "GenSigSendType" SG_ 407 RFC_Loc015_Theta 9;
BA_ "GenSigStartValue" SG_ 407 RFC_Loc015_Theta 32768;
BA_ "GenSigSendType" SG_ 407 RFC_Loc015_Phi 9;
BA_ "GenSigStartValue" SG_ 407 RFC_Loc015_Phi 32768;
BA_ "GenSigSendType" SG_ 407 RFC_Loc015_DrVnce 9;
BA_ "GenSigSendType" SG_ 407 RFC_Loc015_VrVnce 9;
BA_ "GenSigSendType" SG_ 407 RFC_Loc015_ThetaVnce 9;
BA_ "GenSigSendType" SG_ 407 RFC_Loc015_PhiVnce 9;
BA_ "GenSigSendType" SG_ 407 RFC_Loc015_DrVrCoVnce 9;
BA_ "GenSigStartValue" SG_ 407 RFC_Loc015_DrVrCoVnce 32768;
BA_ "GenSigSendType" SG_ 407 RFC_Loc015_RCS 9;
BA_ "GenSigStartValue" SG_ 407 RFC_Loc015_RCS 32768;
BA_ "GenSigSendType" SG_ 407 RFC_Loc015_RSSI 9;
BA_ "GenSigSendType" SG_ 407 RFC_Loc015_DrVrQuality 9;
BA_ "GenSigSendType" SG_ 407 RFC_Loc015_ThetaQuality 9;
BA_ "GenSigSendType" SG_ 407 RFC_Loc015_PhiQuality 9;
BA_ "GenSigSendType" SG_ 408 RFC_Loc016_CRC 9;
BA_ "GenSigSendType" SG_ 408 RFC_Loc016_AliveCtr 9;
BA_ "GenSigSendType" SG_ 408 RFC_Loc016_ProtBlockCtr 9;
BA_ "GenSigSendType" SG_ 408 RFC_Loc016_Dr 9;
BA_ "GenSigSendType" SG_ 408 RFC_Loc016_Vr 9;
BA_ "GenSigStartValue" SG_ 408 RFC_Loc016_Vr 32768;
BA_ "GenSigSendType" SG_ 408 RFC_Loc016_Theta 9;
BA_ "GenSigStartValue" SG_ 408 RFC_Loc016_Theta 32768;
BA_ "GenSigSendType" SG_ 408 RFC_Loc016_Phi 9;
BA_ "GenSigStartValue" SG_ 408 RFC_Loc016_Phi 32768;
BA_ "GenSigSendType" SG_ 408 RFC_Loc016_DrVnce 9;
BA_ "GenSigSendType" SG_ 408 RFC_Loc016_VrVnce 9;
BA_ "GenSigSendType" SG_ 408 RFC_Loc016_ThetaVnce 9;
BA_ "GenSigSendType" SG_ 408 RFC_Loc016_PhiVnce 9;
BA_ "GenSigSendType" SG_ 408 RFC_Loc016_DrVrCoVnce 9;
BA_ "GenSigStartValue" SG_ 408 RFC_Loc016_DrVrCoVnce 32768;
BA_ "GenSigSendType" SG_ 408 RFC_Loc016_RCS 9;
BA_ "GenSigStartValue" SG_ 408 RFC_Loc016_RCS 32768;
BA_ "GenSigSendType" SG_ 408 RFC_Loc016_RSSI 9;
BA_ "GenSigSendType" SG_ 408 RFC_Loc016_DrVrQuality 9;
BA_ "GenSigSendType" SG_ 408 RFC_Loc016_ThetaQuality 9;
BA_ "GenSigSendType" SG_ 408 RFC_Loc016_PhiQuality 9;
BA_ "GenSigSendType" SG_ 408 RFC_Loc017_Dr 9;
BA_ "GenSigSendType" SG_ 408 RFC_Loc017_Vr 9;
BA_ "GenSigStartValue" SG_ 408 RFC_Loc017_Vr 32768;
BA_ "GenSigSendType" SG_ 408 RFC_Loc017_Theta 9;
BA_ "GenSigStartValue" SG_ 408 RFC_Loc017_Theta 32768;
BA_ "GenSigSendType" SG_ 408 RFC_Loc017_Phi 9;
BA_ "GenSigStartValue" SG_ 408 RFC_Loc017_Phi 32768;
BA_ "GenSigSendType" SG_ 408 RFC_Loc017_DrVnce 9;
BA_ "GenSigSendType" SG_ 408 RFC_Loc017_VrVnce 9;
BA_ "GenSigSendType" SG_ 408 RFC_Loc017_ThetaVnce 9;
BA_ "GenSigSendType" SG_ 408 RFC_Loc017_PhiVnce 9;
BA_ "GenSigSendType" SG_ 408 RFC_Loc017_DrVrCoVnce 9;
BA_ "GenSigStartValue" SG_ 408 RFC_Loc017_DrVrCoVnce 32768;
BA_ "GenSigSendType" SG_ 408 RFC_Loc017_RCS 9;
BA_ "GenSigStartValue" SG_ 408 RFC_Loc017_RCS 32768;
BA_ "GenSigSendType" SG_ 408 RFC_Loc017_RSSI 9;
BA_ "GenSigSendType" SG_ 408 RFC_Loc017_DrVrQuality 9;
BA_ "GenSigSendType" SG_ 408 RFC_Loc017_ThetaQuality 9;
BA_ "GenSigSendType" SG_ 408 RFC_Loc017_PhiQuality 9;
BA_ "GenSigSendType" SG_ 409 RFC_Loc018_CRC 9;
BA_ "GenSigSendType" SG_ 409 RFC_Loc018_AliveCtr 9;
BA_ "GenSigSendType" SG_ 409 RFC_Loc018_ProtBlockCtr 9;
BA_ "GenSigSendType" SG_ 409 RFC_Loc018_Dr 9;
BA_ "GenSigSendType" SG_ 409 RFC_Loc018_Vr 9;
BA_ "GenSigStartValue" SG_ 409 RFC_Loc018_Vr 32768;
BA_ "GenSigSendType" SG_ 409 RFC_Loc018_Theta 9;
BA_ "GenSigStartValue" SG_ 409 RFC_Loc018_Theta 32768;
BA_ "GenSigSendType" SG_ 409 RFC_Loc018_Phi 9;
BA_ "GenSigStartValue" SG_ 409 RFC_Loc018_Phi 32768;
BA_ "GenSigSendType" SG_ 409 RFC_Loc018_DrVnce 9;
BA_ "GenSigSendType" SG_ 409 RFC_Loc018_VrVnce 9;
BA_ "GenSigSendType" SG_ 409 RFC_Loc018_ThetaVnce 9;
BA_ "GenSigSendType" SG_ 409 RFC_Loc018_PhiVnce 9;
BA_ "GenSigSendType" SG_ 409 RFC_Loc018_DrVrCoVnce 9;
BA_ "GenSigStartValue" SG_ 409 RFC_Loc018_DrVrCoVnce 32768;
BA_ "GenSigSendType" SG_ 409 RFC_Loc018_RCS 9;
BA_ "GenSigStartValue" SG_ 409 RFC_Loc018_RCS 32768;
BA_ "GenSigSendType" SG_ 409 RFC_Loc018_RSSI 9;
BA_ "GenSigSendType" SG_ 409 RFC_Loc018_DrVrQuality 9;
BA_ "GenSigSendType" SG_ 409 RFC_Loc018_ThetaQuality 9;
BA_ "GenSigSendType" SG_ 409 RFC_Loc018_PhiQuality 9;
BA_ "GenSigSendType" SG_ 409 RFC_Loc019_Dr 9;
BA_ "GenSigSendType" SG_ 409 RFC_Loc019_Vr 9;
BA_ "GenSigStartValue" SG_ 409 RFC_Loc019_Vr 32768;
BA_ "GenSigSendType" SG_ 409 RFC_Loc019_Theta 9;
BA_ "GenSigStartValue" SG_ 409 RFC_Loc019_Theta 32768;
BA_ "GenSigSendType" SG_ 409 RFC_Loc019_Phi 9;
BA_ "GenSigStartValue" SG_ 409 RFC_Loc019_Phi 32768;
BA_ "GenSigSendType" SG_ 409 RFC_Loc019_DrVnce 9;
BA_ "GenSigSendType" SG_ 409 RFC_Loc019_VrVnce 9;
BA_ "GenSigSendType" SG_ 409 RFC_Loc019_ThetaVnce 9;
BA_ "GenSigSendType" SG_ 409 RFC_Loc019_PhiVnce 9;
BA_ "GenSigSendType" SG_ 409 RFC_Loc019_DrVrCoVnce 9;
BA_ "GenSigStartValue" SG_ 409 RFC_Loc019_DrVrCoVnce 32768;
BA_ "GenSigSendType" SG_ 409 RFC_Loc019_RCS 9;
BA_ "GenSigStartValue" SG_ 409 RFC_Loc019_RCS 32768;
BA_ "GenSigSendType" SG_ 409 RFC_Loc019_RSSI 9;
BA_ "GenSigSendType" SG_ 409 RFC_Loc019_DrVrQuality 9;
BA_ "GenSigSendType" SG_ 409 RFC_Loc019_ThetaQuality 9;
BA_ "GenSigSendType" SG_ 409 RFC_Loc019_PhiQuality 9;
VAL_ 214 VFC_Obj19A_ClassifiedView 0 "Unknown" 1 "Front" 2 "Rear" 3 "Left" 4 "Right" ;
VAL_ 214 VFC_Obj19A_Measured 0 "Invalid" 1 "Predicted" 2 "Measured" 3 "Reserved" ;
VAL_ 214 VFC_Obj19A_VisibleView 0 "UNKNOWN" 1 "CLASSIC" 2 "SIDE" 3 "CLASSIC_SIDE" 4 "SIDE_CLASSIC" ;
VAL_ 214 VFC_Obj19A_HeadOrientation 0 "N/A" 1 "Head front" 2 "Head left front" 3 "Head left" 4 "Head left back" 5 "Head back" 6 "Head right back" 7 "Head right" 8 "Head right front" 15 "Unknown" ;
VAL_ 214 VFC_Obj19A_Type 0 "No type" 1 "Car" 2 "Truck" 3 "Motorcycle" 4 "Pedestrian" 5 "Cyclist" 6 "Animal" ;
VAL_ 215 VFC_Obj19B_LineEdgeRightEgo 0 "Right" 1 "Not Right" ;
VAL_ 215 VFC_Obj19B_LineEdgeLeftEgo 0 "Left" 1 "Not Left" ;
VAL_ 215 VFC_Obj19B_CompletelyInImg 0 "completely measured" 1 "not completely measured" ;
VAL_ 215 VFC_Obj19B_DirIndicator 0 "No direction indicator" 1 "Left indicator" 2 "Right indicator" 3 "Warning Lights" 4 "Unknown" ;
VAL_ 215 VFC_Obj19B_BrakeLight 0 "No light detected" 1 "One light detected" 2 "Two lights detected" 3 "Three lights detected" 4 "Unknown" ;
VAL_ 215 VFC_Obj19B_MeasSource 1 "MOD" 2 "PDET" 4 "OFT" 8 "OLS" 16 "Reserved" ;
VAL_ 215 VFC_Obj19B_Reliab 1 "Classifier Path" 2 "Flow Path" 4 "Disparity Path" 8 "Semantic Segmentation Path" 16 "Flow Stixel Path" 32 "Reserved" ;
VAL_ 128 VFC_LineHdr_Report 1 "INVALID_BET_INPUT" 2 "INVALID_MOPED_INPUT" 4 "INVALID_MOFU_INPUT" 8 "NO_LBSEGS" 16 "INVALID_YAW_RATE" 32 "INVALID_YAW_ANGLE" 64 "INVALID_VELOCITY" 128 "INVALID_TIMESTAMP" ;
VAL_ 128 VFC_LineHdr_State 0 "off" 1 "on" 2 "Reduced" 3 "HW_Error" 4 "SW_Error" 5 "FID_Active" 6 "Reserved6" 7 "Reserved7" ;
VAL_ 129 VFC_Line01_LaneRelation 0 "LEFT_EGO_LINE" 1 "RIGHT_EGO_LINE" 2 "LEFT_LEFT_LINE" 3 "RIGHT_RIGHT_LINE" 4 "ROAD_EDGE_LEFT" 5 "ROAD_EDGE_RIGHT" 6 "RAISED_LEFT" 7 "RAISED_RIGHT" ;
VAL_ 129 VFC_Line01_ColorClass 0 "COLOR_WHITE" 1 "COLOR_YELLOW" 2 "COLOR_RED" 3 "COLOR_BLUE" 7 "COLOR_UNKNOWN" ;
VAL_ 129 VFC_Line01_MeasureType 0 "MTYPE_MEASURED" 1 "MTYPE_VIRTUAL" 2 "MTYPE_INTERPOLATED" 3 "MTYPE_UNKNOWN" ;
VAL_ 129 VFC_Line01_Type 0 "TYPE_SOLID_LINE" 1 "TYPE_DASHED_LINE" 2 "TYPE_DOUBLE_DASHED_DASHED" 3 "TYPE_DOUBLE_DASHED_SOLID" 4 "TYPE_DOUBLE_SOLID_DASHED" 5 "TYPE_DOUBLE_SOLID_SOLID" 6 "TYPE_MULTIPLE" 7 "TYPE_MULTIPLE_WARNING" 8 "TYPE_CAR_POOL" 9 "TYPE_ASPHALT_JOINT" 10 "TYPE_BOTTS_DOTS" 11 "TYPE_ROAD_EDGE" 12 "TYPE_GUARDRAIL" 13 "TYPE_CURBSTONE" 14 "TYPE_WALL" 15 "TYPE_TRAFFIC_CONE" 16 "TYPE_DELINEATOR_POST" 17 "TYPE_PARKING_CAR" 18 "TYPE_UNKNOWN_RAISED" 19 "TYPE_UNKNOWN" ;
VAL_ 130 VFC_Line02_LaneRelation 0 "LEFT_EGO_LINE" 1 "RIGHT_EGO_LINE" 2 "LEFT_LEFT_LINE" 3 "RIGHT_RIGHT_LINE" 4 "ROAD_EDGE_LEFT" 5 "ROAD_EDGE_RIGHT" 6 "RAISED_LEFT" 7 "RAISED_RIGHT" ;
VAL_ 130 VFC_Line02_ColorClass 0 "COLOR_WHITE" 1 "COLOR_YELLOW" 2 "COLOR_RED" 3 "COLOR_BLUE" 7 "COLOR_UNKNOWN" ;
VAL_ 130 VFC_Line02_MeasureType 0 "MTYPE_MEASURED" 1 "MTYPE_VIRTUAL" 2 "MTYPE_INTERPOLATED" 3 "MTYPE_UNKNOWN" ;
VAL_ 130 VFC_Line02_Type 0 "TYPE_SOLID_LINE" 1 "TYPE_DASHED_LINE" 2 "TYPE_DOUBLE_DASHED_DASHED" 3 "TYPE_DOUBLE_DASHED_SOLID" 4 "TYPE_DOUBLE_SOLID_DASHED" 5 "TYPE_DOUBLE_SOLID_SOLID" 6 "TYPE_MULTIPLE" 7 "TYPE_MULTIPLE_WARNING" 8 "TYPE_CAR_POOL" 9 "TYPE_ASPHALT_JOINT" 10 "TYPE_BOTTS_DOTS" 11 "TYPE_ROAD_EDGE" 12 "TYPE_GUARDRAIL" 13 "TYPE_CURBSTONE" 14 "TYPE_WALL" 15 "TYPE_TRAFFIC_CONE" 16 "TYPE_DELINEATOR_POST" 17 "TYPE_PARKING_CAR" 18 "TYPE_UNKNOWN_RAISED" 19 "TYPE_UNKNOWN" ;
VAL_ 131 VFC_Line03_LaneRelation 0 "LEFT_EGO_LINE" 1 "RIGHT_EGO_LINE" 2 "LEFT_LEFT_LINE" 3 "RIGHT_RIGHT_LINE" 4 "ROAD_EDGE_LEFT" 5 "ROAD_EDGE_RIGHT" 6 "RAISED_LEFT" 7 "RAISED_RIGHT" ;
VAL_ 131 VFC_Line03_ColorClass 0 "COLOR_WHITE" 1 "COLOR_YELLOW" 2 "COLOR_RED" 3 "COLOR_BLUE" 7 "COLOR_UNKNOWN" ;
VAL_ 131 VFC_Line03_MeasureType 0 "MTYPE_MEASURED" 1 "MTYPE_VIRTUAL" 2 "MTYPE_INTERPOLATED" 3 "MTYPE_UNKNOWN" ;
VAL_ 131 VFC_Line03_Type 0 "TYPE_SOLID_LINE" 1 "TYPE_DASHED_LINE" 2 "TYPE_DOUBLE_DASHED_DASHED" 3 "TYPE_DOUBLE_DASHED_SOLID" 4 "TYPE_DOUBLE_SOLID_DASHED" 5 "TYPE_DOUBLE_SOLID_SOLID" 6 "TYPE_MULTIPLE" 7 "TYPE_MULTIPLE_WARNING" 8 "TYPE_CAR_POOL" 9 "TYPE_ASPHALT_JOINT" 10 "TYPE_BOTTS_DOTS" 11 "TYPE_ROAD_EDGE" 12 "TYPE_GUARDRAIL" 13 "TYPE_CURBSTONE" 14 "TYPE_WALL" 15 "TYPE_TRAFFIC_CONE" 16 "TYPE_DELINEATOR_POST" 17 "TYPE_PARKING_CAR" 18 "TYPE_UNKNOWN_RAISED" 19 "TYPE_UNKNOWN" ;
VAL_ 132 VFC_Line04_LaneRelation 0 "LEFT_EGO_LINE" 1 "RIGHT_EGO_LINE" 2 "LEFT_LEFT_LINE" 3 "RIGHT_RIGHT_LINE" 4 "ROAD_EDGE_LEFT" 5 "ROAD_EDGE_RIGHT" 6 "RAISED_LEFT" 7 "RAISED_RIGHT" ;
VAL_ 132 VFC_Line04_ColorClass 0 "COLOR_WHITE" 1 "COLOR_YELLOW" 2 "COLOR_RED" 3 "COLOR_BLUE" 7 "COLOR_UNKNOWN" ;
VAL_ 132 VFC_Line04_MeasureType 0 "MTYPE_MEASURED" 1 "MTYPE_VIRTUAL" 2 "MTYPE_INTERPOLATED" 3 "MTYPE_UNKNOWN" ;
VAL_ 132 VFC_Line04_Type 0 "TYPE_SOLID_LINE" 1 "TYPE_DASHED_LINE" 2 "TYPE_DOUBLE_DASHED_DASHED" 3 "TYPE_DOUBLE_DASHED_SOLID" 4 "TYPE_DOUBLE_SOLID_DASHED" 5 "TYPE_DOUBLE_SOLID_SOLID" 6 "TYPE_MULTIPLE" 7 "TYPE_MULTIPLE_WARNING" 8 "TYPE_CAR_POOL" 9 "TYPE_ASPHALT_JOINT" 10 "TYPE_BOTTS_DOTS" 11 "TYPE_ROAD_EDGE" 12 "TYPE_GUARDRAIL" 13 "TYPE_CURBSTONE" 14 "TYPE_WALL" 15 "TYPE_TRAFFIC_CONE" 16 "TYPE_DELINEATOR_POST" 17 "TYPE_PARKING_CAR" 18 "TYPE_UNKNOWN_RAISED" 19 "TYPE_UNKNOWN" ;
VAL_ 133 VFC_Line05_LaneRelation 0 "LEFT_EGO_LINE" 1 "RIGHT_EGO_LINE" 2 "LEFT_LEFT_LINE" 3 "RIGHT_RIGHT_LINE" 4 "ROAD_EDGE_LEFT" 5 "ROAD_EDGE_RIGHT" 6 "RAISED_LEFT" 7 "RAISED_RIGHT" ;
VAL_ 133 VFC_Line05_ColorClass 0 "COLOR_WHITE" 1 "COLOR_YELLOW" 2 "COLOR_RED" 3 "COLOR_BLUE" 7 "COLOR_UNKNOWN" ;
VAL_ 133 VFC_Line05_MeasureType 0 "MTYPE_MEASURED" 1 "MTYPE_VIRTUAL" 2 "MTYPE_INTERPOLATED" 3 "MTYPE_UNKNOWN" ;
VAL_ 133 VFC_Line05_Type 0 "TYPE_SOLID_LINE" 1 "TYPE_DASHED_LINE" 2 "TYPE_DOUBLE_DASHED_DASHED" 3 "TYPE_DOUBLE_DASHED_SOLID" 4 "TYPE_DOUBLE_SOLID_DASHED" 5 "TYPE_DOUBLE_SOLID_SOLID" 6 "TYPE_MULTIPLE" 7 "TYPE_MULTIPLE_WARNING" 8 "TYPE_CAR_POOL" 9 "TYPE_ASPHALT_JOINT" 10 "TYPE_BOTTS_DOTS" 11 "TYPE_ROAD_EDGE" 12 "TYPE_GUARDRAIL" 13 "TYPE_CURBSTONE" 14 "TYPE_WALL" 15 "TYPE_TRAFFIC_CONE" 16 "TYPE_DELINEATOR_POST" 17 "TYPE_PARKING_CAR" 18 "TYPE_UNKNOWN_RAISED" 19 "TYPE_UNKNOWN" ;
VAL_ 134 VFC_Line06_LaneRelation 0 "LEFT_EGO_LINE" 1 "RIGHT_EGO_LINE" 2 "LEFT_LEFT_LINE" 3 "RIGHT_RIGHT_LINE" 4 "ROAD_EDGE_LEFT" 5 "ROAD_EDGE_RIGHT" 6 "RAISED_LEFT" 7 "RAISED_RIGHT" ;
VAL_ 134 VFC_Line06_ColorClass 0 "COLOR_WHITE" 1 "COLOR_YELLOW" 2 "COLOR_RED" 3 "COLOR_BLUE" 7 "COLOR_UNKNOWN" ;
VAL_ 134 VFC_Line06_MeasureType 0 "MTYPE_MEASURED" 1 "MTYPE_VIRTUAL" 2 "MTYPE_INTERPOLATED" 3 "MTYPE_UNKNOWN" ;
VAL_ 134 VFC_Line06_Type 0 "TYPE_SOLID_LINE" 1 "TYPE_DASHED_LINE" 2 "TYPE_DOUBLE_DASHED_DASHED" 3 "TYPE_DOUBLE_DASHED_SOLID" 4 "TYPE_DOUBLE_SOLID_DASHED" 5 "TYPE_DOUBLE_SOLID_SOLID" 6 "TYPE_MULTIPLE" 7 "TYPE_MULTIPLE_WARNING" 8 "TYPE_CAR_POOL" 9 "TYPE_ASPHALT_JOINT" 10 "TYPE_BOTTS_DOTS" 11 "TYPE_ROAD_EDGE" 12 "TYPE_GUARDRAIL" 13 "TYPE_CURBSTONE" 14 "TYPE_WALL" 15 "TYPE_TRAFFIC_CONE" 16 "TYPE_DELINEATOR_POST" 17 "TYPE_PARKING_CAR" 18 "TYPE_UNKNOWN_RAISED" 19 "TYPE_UNKNOWN" ;
VAL_ 135 VFC_Line07_LaneRelation 0 "LEFT_EGO_LINE" 1 "RIGHT_EGO_LINE" 2 "LEFT_LEFT_LINE" 3 "RIGHT_RIGHT_LINE" 4 "ROAD_EDGE_LEFT" 5 "ROAD_EDGE_RIGHT" 6 "RAISED_LEFT" 7 "RAISED_RIGHT" ;
VAL_ 135 VFC_Line07_ColorClass 0 "COLOR_WHITE" 1 "COLOR_YELLOW" 2 "COLOR_RED" 3 "COLOR_BLUE" 7 "COLOR_UNKNOWN" ;
VAL_ 135 VFC_Line07_MeasureType 0 "MTYPE_MEASURED" 1 "MTYPE_VIRTUAL" 2 "MTYPE_INTERPOLATED" 3 "MTYPE_UNKNOWN" ;
VAL_ 135 VFC_Line07_Type 0 "TYPE_SOLID_LINE" 1 "TYPE_DASHED_LINE" 2 "TYPE_DOUBLE_DASHED_DASHED" 3 "TYPE_DOUBLE_DASHED_SOLID" 4 "TYPE_DOUBLE_SOLID_DASHED" 5 "TYPE_DOUBLE_SOLID_SOLID" 6 "TYPE_MULTIPLE" 7 "TYPE_MULTIPLE_WARNING" 8 "TYPE_CAR_POOL" 9 "TYPE_ASPHALT_JOINT" 10 "TYPE_BOTTS_DOTS" 11 "TYPE_ROAD_EDGE" 12 "TYPE_GUARDRAIL" 13 "TYPE_CURBSTONE" 14 "TYPE_WALL" 15 "TYPE_TRAFFIC_CONE" 16 "TYPE_DELINEATOR_POST" 17 "TYPE_PARKING_CAR" 18 "TYPE_UNKNOWN_RAISED" 19 "TYPE_UNKNOWN" ;
VAL_ 136 VFC_Line08_LaneRelation 0 "LEFT_EGO_LINE" 1 "RIGHT_EGO_LINE" 2 "LEFT_LEFT_LINE" 3 "RIGHT_RIGHT_LINE" 4 "ROAD_EDGE_LEFT" 5 "ROAD_EDGE_RIGHT" 6 "RAISED_LEFT" 7 "RAISED_RIGHT" ;
VAL_ 136 VFC_Line08_ColorClass 0 "COLOR_WHITE" 1 "COLOR_YELLOW" 2 "COLOR_RED" 3 "COLOR_BLUE" 7 "COLOR_UNKNOWN" ;
VAL_ 136 VFC_Line08_MeasureType 0 "MTYPE_MEASURED" 1 "MTYPE_VIRTUAL" 2 "MTYPE_INTERPOLATED" 3 "MTYPE_UNKNOWN" ;
VAL_ 136 VFC_Line08_Type 0 "TYPE_SOLID_LINE" 1 "TYPE_DASHED_LINE" 2 "TYPE_DOUBLE_DASHED_DASHED" 3 "TYPE_DOUBLE_DASHED_SOLID" 4 "TYPE_DOUBLE_SOLID_DASHED" 5 "TYPE_DOUBLE_SOLID_SOLID" 6 "TYPE_MULTIPLE" 7 "TYPE_MULTIPLE_WARNING" 8 "TYPE_CAR_POOL" 9 "TYPE_ASPHALT_JOINT" 10 "TYPE_BOTTS_DOTS" 11 "TYPE_ROAD_EDGE" 12 "TYPE_GUARDRAIL" 13 "TYPE_CURBSTONE" 14 "TYPE_WALL" 15 "TYPE_TRAFFIC_CONE" 16 "TYPE_DELINEATOR_POST" 17 "TYPE_PARKING_CAR" 18 "TYPE_UNKNOWN_RAISED" 19 "TYPE_UNKNOWN" ;
VAL_ 930 VFC_ADAS_ModSts_SLA 0 "Unknown" 1 "Off" 2 "Fusion mode" 3 "Vision mode" 4 "Navigation only mode" 5 "Defect" 6 "Reserved" 7 "Reserved" ;
VAL_ 930 VFC_ADAS_SpdLim_SLA 0 "No Display" 1 "SPL Cancelled" 2 "SPL 5" 3 "SPL 10" 4 "SPL 15" 5 "SPL 20" 6 "SPL 25" 7 "SPL 30" 8 "SPL 35" 9 "SPL 40" 10 "SPL 45" 11 "SPL 50" 12 "SPL 55" 13 "SPL 60" 14 "SPL 65" 15 "SPL 70" 16 "SPL 75" 17 "SPL 80" 18 "SPL 85" 19 "SPL 90" 20 "SPL 95" 21 "SPL 100" 22 "SPL 105" 23 "SPL 110" 24 "SPL 115" 25 "SPL 120" 26 "SPL 125" 27 "SPL 130" 28 "Reserved" 29 "0x1C(28)-FF(255): Reserved." 255 "0x1C(28)-FF(255): Reserved." ;
VAL_ 930 VFC_ADAS_SpdLimUnit_SLA 0 "Unknown" 1 "KPH" 2 "MPH" 3 "Reserved" ;
VAL_ 384 RFC_Hdr00_SensorState 0 "SENSOR FULLY OPERATIONAL" 1 "HW MALFUNCTION" 2 "DSP ISSUES" 3 "COMMUNICATION ERRORS" 4 "MISALIGNMENT (OUT OF SPEC)" 5 "SENSOR BLIDNESS DETECTED" 6 "SENSOR DISTUBED" 7 "OTHER ISSUES" 8 "RESERVED1" 9 "RESERVED2" 10 "RESERVED3" 11 "RESERVED4" 12 "RESERVED5" 13 "RESERVED6" 14 "RESERVED7" 15 "INVALID" ;
VAL_ 384 RFC_Hdr00_LocDownSel 0 "no downselection" 1 "downselected" ;
SIG_VALTYPE_ 384 RFC_Hdr00_BliTheta : 1;
SIG_VALTYPE_ 384 RFC_Hdr00_BliThetaSIMO : 1;
SIG_VALTYPE_ 384 RFC_Hdr00_BliThetaMIMO : 1;
SIG_VALTYPE_ 384 RFC_Hdr00_BliThetaSIMOShare : 1;
SIG_VALTYPE_ 384 RFC_Hdr00_BliThetaMIMOShare : 1;
SIG_VALTYPE_ 384 RFC_Hdr00_BliPhi : 1;
SIG_VALTYPE_ 384 RFC_Hdr00_BliRCSMO : 1;
SIG_VALTYPE_ 384 RFC_Hdr00_BliBinsOverThreshold : 1;
SIG_VALTYPE_ 384 RFC_Hdr00_BliNumValidReflections : 1;
SIG_VALTYPE_ 384 RFC_Hdr00_BliCrossCorrSO : 1;
SIG_VALTYPE_ 385 RFC_Hdr01_PersAngIndAzi : 1;
SIG_VALTYPE_ 385 RFC_Hdr01_PersAngIndElev : 1;
SIG_VALTYPE_ 385 RFC_Hdr01_PersAngIndAziMean : 1;
SIG_VALTYPE_ 385 RFC_Hdr01_PersAngIndElevMean : 1;
SIG_VALTYPE_ 385 RFC_Hdr01_PersAngIndAziVnce : 1;
SIG_VALTYPE_ 385 RFC_Hdr01_PersAngIndElevVnce : 1;
SIG_VALTYPE_ 385 RFC_Hdr01_PersAngIndAziElevCov : 1;
SIG_VALTYPE_ 385 RFC_Hdr01_PersAngCurrAzi : 1;
SIG_VALTYPE_ 385 RFC_Hdr01_PersAngCurrElev : 1;
SIG_VALTYPE_ 385 RFC_Hdr01_PersAngCurrAziMean : 1;
SIG_VALTYPE_ 385 RFC_Hdr01_PersAngCurrElevMean : 1;
SIG_VALTYPE_ 385 RFC_Hdr01_PersAngCurrAziVnce : 1;
SIG_VALTYPE_ 385 RFC_Hdr01_PersAngCurrElevVnce : 1;
SIG_VALTYPE_ 385 RFC_Hdr01_PersAngCurrAziElevCov : 1;
SIG_VALTYPE_ 386 RFC_Hdr02_PersFiltDspMalIndAzi : 1;
SIG_VALTYPE_ 386 RFC_Hdr02_PersFiltWeightIndAzi : 1;
SIG_VALTYPE_ 386 RFC_Hdr02_PersFiltDspCurrAzi : 1;
SIG_VALTYPE_ 386 RFC_Hdr02_PersFiltDspMalIndElev : 1;
SIG_VALTYPE_ 386 RFC_Hdr02_PersFiltWeightIndElev : 1;
SIG_VALTYPE_ 386 RFC_Hdr02_PersFiltDspCurrElev : 1;
SIG_VALTYPE_ 386 RFC_Hdr02_PersMalStablePosAzi : 1;
SIG_VALTYPE_ 386 RFC_Hdr02_PersMalStablePosElev : 1;
SIG_VALTYPE_ 386 RFC_Hdr02_PersChDetPozAzi : 1;
SIG_VALTYPE_ 386 RFC_Hdr02_PersChDetNegAzi : 1;
SIG_VALTYPE_ 386 RFC_Hdr02_PersChDetPozElev : 1;
SIG_VALTYPE_ 386 RFC_Hdr02_PersChDetNegElev : 1;
SIG_VALTYPE_ 386 RFC_Hdr02_MntAziCur : 1;
SIG_VALTYPE_ 386 RFC_Hdr02_MntElevCur : 1;
SIG_VALTYPE_ 388 RFC_Hdr04_MntPosX : 1;
SIG_VALTYPE_ 388 RFC_Hdr04_MntPosY : 1;
SIG_VALTYPE_ 388 RFC_Hdr04_MntPosZ : 1;
SIG_VALTYPE_ 388 RFC_Hdr04_MntAziNom : 1;
SIG_VALTYPE_ 388 RFC_Hdr04_MntElevNom : 1;
SIG_VALTYPE_ 388 RFC_Hdr04_InitCov : 1;
